AUTOSAR XML (schema 4-0-3)
standard types defined: Boolean, UInt16, UInt32, UInt8
package /AUTOSAR_Platform/DataConstrs
  range DC_Boolean: raw 0..1
  range DC_UInt16: raw 0..65535
  range DC_UInt8: raw 0..255
package /DataTypes/Units
  unit NoUnit1: display-name=NoUnit, factor-si-to-unit=1, offset-si-to-unit=0
package /PATAC/Facility/DataTypes/Implementation
  unit NoUnit: factor-si-to-unit=1, offset-si-to-unit=0
package /PATAC/MSM/ComponentTypes
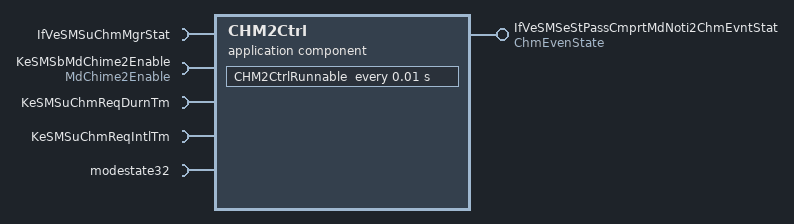
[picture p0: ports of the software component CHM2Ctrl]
  application sw component type CHM2Ctrl
    provide port IfVeSMSeStPassCmprtMdNoti2ChmEvntStat: nonqueued-sender-com-spec=data-element=ChmEvenState/Val, provided-interface=ChmEvenState
    5 x require port:
      IfVeSMSuChmMgrStat: nonqueued-receiver-com-spec{data-element=IfVeSMSuChmMgrStat/Val, filter=data-filter-type=ALWAYS}, required-interface=IfVeSMSuChmMgrStat
      KeSMSbMdChime2Enable: parameter-require-com-spec{init-value=0, parameter=MdChime2Enable/Val}, required-interface=MdChime2Enable
      KeSMSuChmReqDurnTm: parameter-require-com-spec{init-value=200, parameter=KeSMSuChmReqDurnTm/Val}, required-interface=KeSMSuChmReqDurnTm
      KeSMSuChmReqIntlTm: parameter-require-com-spec{init-value=50, parameter=KeSMSuChmReqIntlTm/Val}, required-interface=KeSMSuChmReqIntlTm
      modestate32: nonqueued-receiver-com-spec{data-element=modestate32/Val, filter=data-filter-type=ALWAYS, init-value=0}, required-interface=modestate32
    behavior CHM2Ctrl_InternalBehavior
      timing event TMT_CHM2CtrlRunnable: start-on-event=CHM2CtrlRunnable, period=0.01
      runnable CHM2CtrlRunnable
        data-receive-point-by-arguments:
          access REC_IfVeSMSuChmMgrStat_Val: accessed-variable=IfVeSMSuChmMgrStat.Val
          access REC_modestate32_Val: accessed-variable=modestate32.Val
        data-send-points:
          access SEND_IfVeSMSeStPassCmprtMdNoti2ChmEvntStat_Val: accessed-variable=IfVeSMSeStPassCmprtMdNoti2ChmEvntStat.Val
        parameter access PA_KeSMSbMdChime2Enable_Val: accessed-parameter=KeSMSbMdChime2Enable.Val
        parameter access PA_KeSMSuChmReqDurnTm_Val: accessed-parameter=KeSMSuChmReqDurnTm.Val
        parameter access PA_KeSMSuChmReqIntlTm_Val: accessed-parameter=KeSMSuChmReqIntlTm.Val
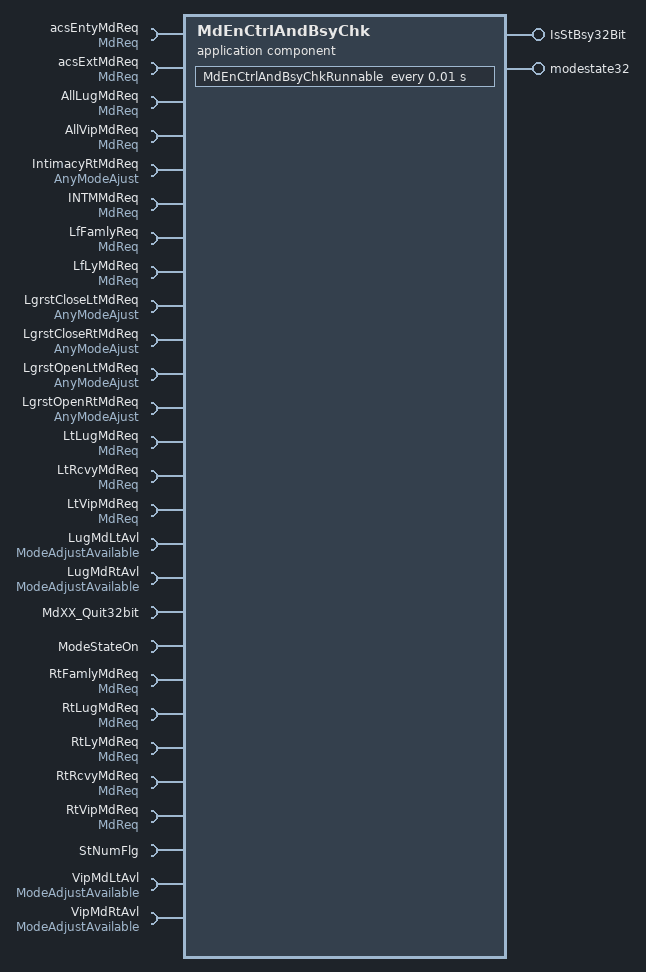
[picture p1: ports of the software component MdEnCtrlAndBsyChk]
  application sw component type MdEnCtrlAndBsyChk
    provide port IsStBsy32Bit: nonqueued-sender-com-spec{data-element=IsStBsy32Bit/Val, init-value=0}, provided-interface=IsStBsy32Bit
    provide port modestate32: nonqueued-sender-com-spec{data-element=modestate32/Val, init-value=0}, provided-interface=modestate32
    27 x require port:
      acsEntyMdReq: nonqueued-receiver-com-spec{data-element=MdReq/Val, filter=data-filter-type=ALWAYS, init-value=0}, required-interface=MdReq
      acsExtMdReq: nonqueued-receiver-com-spec{data-element=MdReq/Val, filter=data-filter-type=ALWAYS, init-value=0}, required-interface=MdReq
      AllLugMdReq: nonqueued-receiver-com-spec{data-element=MdReq/Val, filter=data-filter-type=ALWAYS, init-value=0}, required-interface=MdReq
      AllVipMdReq: nonqueued-receiver-com-spec{data-element=MdReq/Val, filter=data-filter-type=ALWAYS, init-value=0}, required-interface=MdReq
      IntimacyRtMdReq: nonqueued-receiver-com-spec{data-element=AnyModeAjust/Val, filter=data-filter-type=ALWAYS, init-value=0}, required-interface=AnyModeAjust
      INTMMdReq: nonqueued-receiver-com-spec{data-element=MdReq/Val, filter=data-filter-type=ALWAYS, init-value=0}, required-interface=MdReq
      LfFamlyReq: nonqueued-receiver-com-spec{data-element=MdReq/Val, filter=data-filter-type=ALWAYS, init-value=0}, required-interface=MdReq
      LfLyMdReq: nonqueued-receiver-com-spec{data-element=MdReq/Val, filter=data-filter-type=ALWAYS, init-value=0}, required-interface=MdReq
      LgrstCloseLtMdReq: nonqueued-receiver-com-spec{data-element=AnyModeAjust/Val, filter=data-filter-type=ALWAYS, init-value=0}, required-interface=AnyModeAjust
      LgrstCloseRtMdReq: nonqueued-receiver-com-spec{data-element=AnyModeAjust/Val, filter=data-filter-type=ALWAYS, init-value=0}, required-interface=AnyModeAjust
      LgrstOpenLtMdReq: nonqueued-receiver-com-spec{data-element=AnyModeAjust/Val, filter=data-filter-type=ALWAYS, init-value=0}, required-interface=AnyModeAjust
      LgrstOpenRtMdReq: nonqueued-receiver-com-spec{data-element=AnyModeAjust/Val, filter=data-filter-type=ALWAYS, init-value=0}, required-interface=AnyModeAjust
      LtLugMdReq: nonqueued-receiver-com-spec{data-element=MdReq/Val, filter=data-filter-type=ALWAYS, init-value=0}, required-interface=MdReq
      LtRcvyMdReq: nonqueued-receiver-com-spec{data-element=MdReq/Val, filter=data-filter-type=ALWAYS, init-value=0}, required-interface=MdReq
      LtVipMdReq: nonqueued-receiver-com-spec{data-element=MdReq/Val, filter=data-filter-type=ALWAYS, init-value=0}, required-interface=MdReq
      LugMdLtAvl: nonqueued-receiver-com-spec{data-element=ModeAdjustAvailable/Val, filter=data-filter-type=ALWAYS, init-value=0}, required-interface=ModeAdjustAvailable
      LugMdRtAvl: nonqueued-receiver-com-spec{data-element=ModeAdjustAvailable/Val, filter=data-filter-type=ALWAYS, init-value=0}, required-interface=ModeAdjustAvailable
      MdXX_Quit32bit: nonqueued-receiver-com-spec{data-element=MdXX_Quit32bit/Val, filter=data-filter-type=ALWAYS, init-value=0}, required-interface=MdXX_Quit32bit
      ModeStateOn: nonqueued-receiver-com-spec{data-element=ModeStateOn/Val, filter=data-filter-type=ALWAYS, init-value=0}, required-interface=ModeStateOn
      RtFamlyMdReq: nonqueued-receiver-com-spec{data-element=MdReq/Val, filter=data-filter-type=ALWAYS, init-value=0}, required-interface=MdReq
      RtLugMdReq: nonqueued-receiver-com-spec{data-element=MdReq/Val, filter=data-filter-type=ALWAYS, init-value=0}, required-interface=MdReq
      RtLyMdReq: nonqueued-receiver-com-spec{data-element=MdReq/Val, filter=data-filter-type=ALWAYS, init-value=0}, required-interface=MdReq
      RtRcvyMdReq: nonqueued-receiver-com-spec{data-element=MdReq/Val, filter=data-filter-type=ALWAYS, init-value=0}, required-interface=MdReq
      RtVipMdReq: nonqueued-receiver-com-spec{data-element=MdReq/Val, filter=data-filter-type=ALWAYS, init-value=0}, required-interface=MdReq
      StNumFlg: required-interface=StNumFlg
        required-com-specs:
          data-element=Is4s, filter=data-filter-type=ALWAYS, init-value=0
          data-element=Is6s, filter=data-filter-type=ALWAYS, init-value=0
          data-element=Is6s7s, filter=data-filter-type=ALWAYS, init-value=0
          data-element=Is7s, filter=data-filter-type=ALWAYS, init-value=0
      VipMdLtAvl: nonqueued-receiver-com-spec{data-element=ModeAdjustAvailable/Val, filter=data-filter-type=ALWAYS, init-value=0}, required-interface=ModeAdjustAvailable
      VipMdRtAvl: nonqueued-receiver-com-spec{data-element=ModeAdjustAvailable/Val, filter=data-filter-type=ALWAYS, init-value=0}, required-interface=ModeAdjustAvailable
    behavior MdEnCtrlAndBsyChk_InternalBehavior
      timing event TMT_EZEStateCtrlRunnable: start-on-event=MdEnCtrlAndBsyChkRunnable, period=0.01
      runnable MdEnCtrlAndBsyChkRunnable
        data-receive-point-by-arguments:
          30 x access:
            REC_acsEntyMdReq_Val: accessed-variable=acsEntyMdReq.Val
            REC_acsExtMdReq_Val: accessed-variable=acsExtMdReq.Val
            REC_AllLugMdReq_Val: accessed-variable=AllLugMdReq.Val
            REC_AllVipMdReq_Val: accessed-variable=AllVipMdReq.Val
            REC_IntimacyRtMdReq_Val: accessed-variable=IntimacyRtMdReq.Val
            REC_INTMMdReq_Val: accessed-variable=INTMMdReq.Val
            REC_LfFamlyReq_Val: accessed-variable=LfFamlyReq.Val
            REC_LfLyMdReq_Val: accessed-variable=LfLyMdReq.Val
            REC_LgrstCloseLtMdReq_Val: accessed-variable=LgrstCloseLtMdReq.Val
            REC_LgrstCloseRtMdReq_Val: accessed-variable=LgrstCloseRtMdReq.Val
            REC_LgrstOpenLtMdReq_Val: accessed-variable=LgrstOpenLtMdReq.Val
            REC_LgrstOpenRtMdReq_Val: accessed-variable=LgrstOpenRtMdReq.Val
            REC_LtLugMdReq_Val: accessed-variable=LtLugMdReq.Val
            REC_LtRcvyMdReq_Val: accessed-variable=LtRcvyMdReq.Val
            REC_LtVipMdReq_Val: accessed-variable=LtVipMdReq.Val
            REC_LugMdLtAvl_Val: accessed-variable=LugMdLtAvl.Val
            REC_LugMdRtAvl_Val: accessed-variable=LugMdRtAvl.Val
            REC_MdXX_Quit32bit_Val: accessed-variable=MdXX_Quit32bit.Val
            REC_ModeStateOn_Val: accessed-variable=ModeStateOn.Val
            REC_RtFamlyMdReq_Val: accessed-variable=RtFamlyMdReq.Val
            REC_RtLugMdReq_Val: accessed-variable=RtLugMdReq.Val
            REC_RtLyMdReq_Val: accessed-variable=RtLyMdReq.Val
            REC_RtRcvyMdReq_Val: accessed-variable=RtRcvyMdReq.Val
            REC_RtVipMdReq_Val: accessed-variable=RtVipMdReq.Val
            REC_StNumFlg_Is4s: accessed-variable=StNumFlg.Is4s
            REC_StNumFlg_Is6s: accessed-variable=StNumFlg.Is6s
            REC_StNumFlg_Is6s7s: accessed-variable=StNumFlg.Is6s7s
            REC_StNumFlg_Is7s: accessed-variable=StNumFlg.Is7s
            REC_VipMdLtAvl_Val: accessed-variable=VipMdLtAvl.Val
            REC_VipMdRtAvl_Val: accessed-variable=VipMdRtAvl.Val
        data-send-points:
          access SEND_IsStBsy32Bit_Val: accessed-variable=IsStBsy32Bit.Val
          access SEND_modestate32_Val: accessed-variable=modestate32.Val
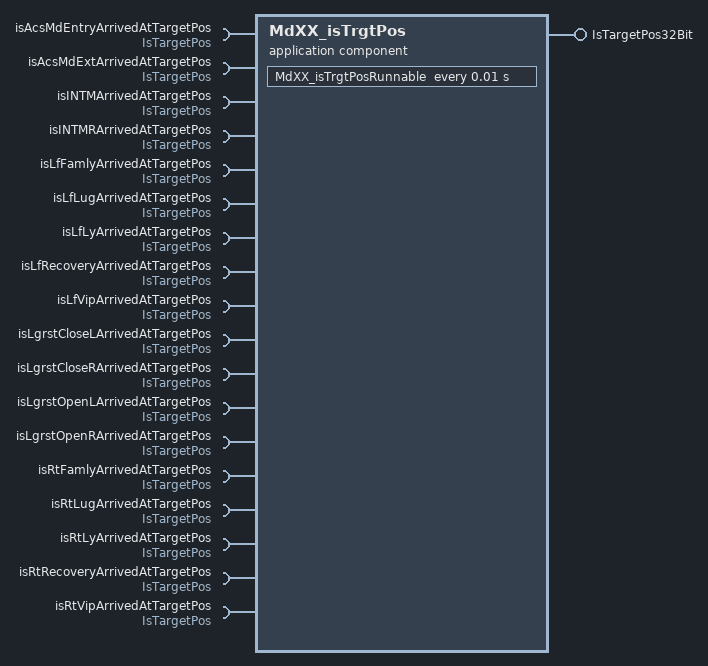
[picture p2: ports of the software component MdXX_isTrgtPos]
  application sw component type MdXX_isTrgtPos
    provide port IsTargetPos32Bit: nonqueued-sender-com-spec{data-element=IsTargetPos32Bit/Val, init-value=0}, provided-interface=IsTargetPos32Bit
    18 x require port, all with nonqueued-receiver-com-spec{data-element=IsTargetPos/Val, filter=data-filter-type=ALWAYS, init-value=0}, required-interface=IsTargetPos:
      isAcsMdEntryArrivedAtTargetPos
      isAcsMdExtArrivedAtTargetPos
      isINTMArrivedAtTargetPos
      isINTMRArrivedAtTargetPos
      isLfFamlyArrivedAtTargetPos
      isLfLugArrivedAtTargetPos
      isLfLyArrivedAtTargetPos
      isLfRecoveryArrivedAtTargetPos
      isLfVipArrivedAtTargetPos
      isLgrstCloseLArrivedAtTargetPos
      isLgrstCloseRArrivedAtTargetPos
      isLgrstOpenLArrivedAtTargetPos
      isLgrstOpenRArrivedAtTargetPos
      isRtFamlyArrivedAtTargetPos
      isRtLugArrivedAtTargetPos
      isRtLyArrivedAtTargetPos
      isRtRecoveryArrivedAtTargetPos
      isRtVipArrivedAtTargetPos
    behavior MdXX_isTrgtPos_InternalBehavior
      timing event TMT_MdXX_isTrgtPosRunnable: start-on-event=MdXX_isTrgtPosRunnable, period=0.01
      runnable MdXX_isTrgtPosRunnable
        data-receive-point-by-arguments:
          18 x access:
            REC_isAcsMdEntryArrivedAtTargetPos_Val: accessed-variable=isAcsMdEntryArrivedAtTargetPos.Val
            REC_isAcsMdExtArrivedAtTargetPos_Val: accessed-variable=isAcsMdExtArrivedAtTargetPos.Val
            REC_isINTMArrivedAtTargetPos_Val: accessed-variable=isINTMArrivedAtTargetPos.Val
            REC_isINTMRArrivedAtTargetPos_Val: accessed-variable=isINTMRArrivedAtTargetPos.Val
            REC_isLfFamlyArrivedAtTargetPos_Val: accessed-variable=isLfFamlyArrivedAtTargetPos.Val
            REC_isLfLugArrivedAtTargetPos_Val: accessed-variable=isLfLugArrivedAtTargetPos.Val
            REC_isLfLyArrivedAtTargetPos_Val: accessed-variable=isLfLyArrivedAtTargetPos.Val
            REC_isLfRecoveryArrivedAtTargetPos_Val: accessed-variable=isLfRecoveryArrivedAtTargetPos.Val
            REC_isLfVipArrivedAtTargetPos_Val: accessed-variable=isLfVipArrivedAtTargetPos.Val
            REC_isLgrstCloseLArrivedAtTargetPos_Val: accessed-variable=isLgrstCloseLArrivedAtTargetPos.Val
            REC_isLgrstCloseRArrivedAtTargetPos_Val: accessed-variable=isLgrstCloseRArrivedAtTargetPos.Val
            REC_isLgrstOpenLArrivedAtTargetPos_Val: accessed-variable=isLgrstOpenLArrivedAtTargetPos.Val
            REC_isLgrstOpenRArrivedAtTargetPos_Val: accessed-variable=isLgrstOpenRArrivedAtTargetPos.Val
            REC_isRtFamlyArrivedAtTargetPos_Val: accessed-variable=isRtFamlyArrivedAtTargetPos.Val
            REC_isRtLugArrivedAtTargetPos_Val: accessed-variable=isRtLugArrivedAtTargetPos.Val
            REC_isRtLyArrivedAtTargetPos_Val: accessed-variable=isRtLyArrivedAtTargetPos.Val
            REC_isRtRecoveryArrivedAtTargetPos_Val: accessed-variable=isRtRecoveryArrivedAtTargetPos.Val
            REC_isRtVipArrivedAtTargetPos_Val: accessed-variable=isRtVipArrivedAtTargetPos.Val
        data-send-points:
          access SEND_IsTargetPos32Bit_Val: accessed-variable=IsTargetPos32Bit.Val
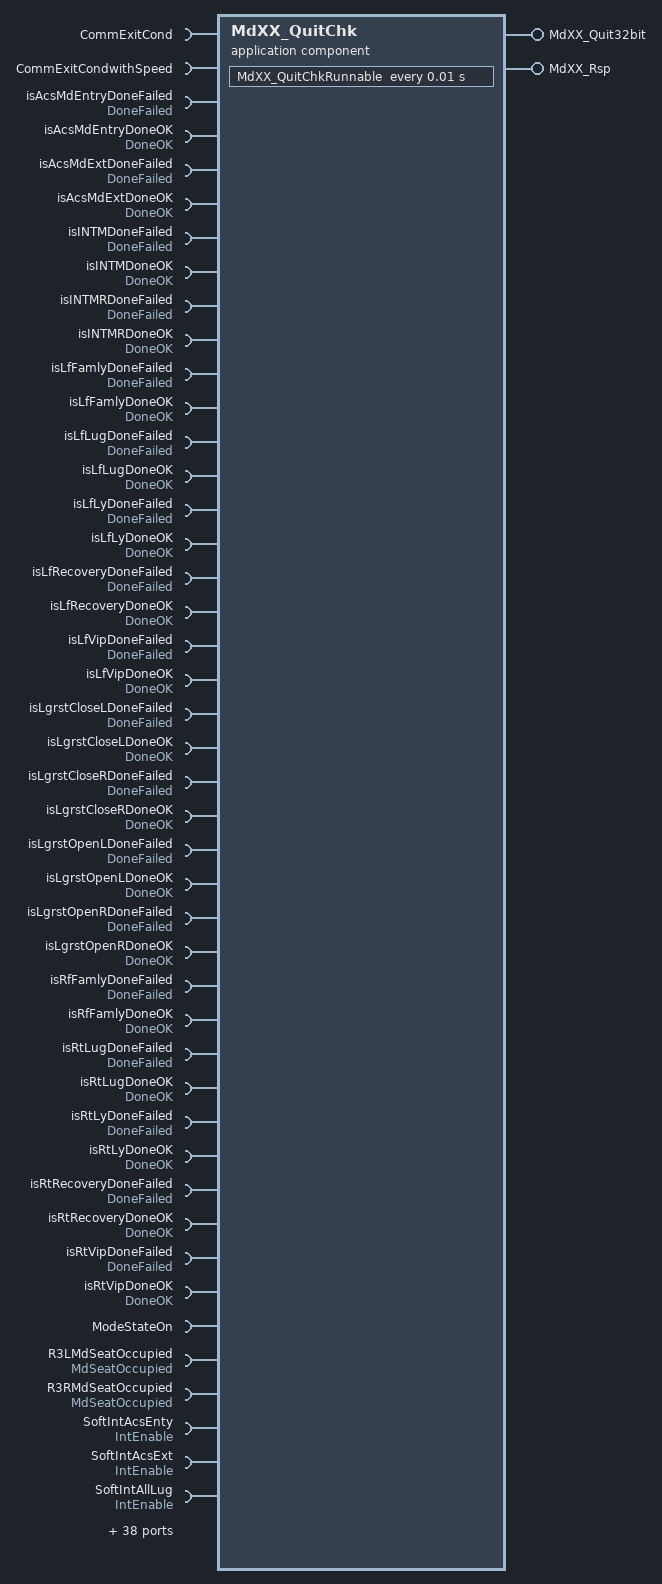
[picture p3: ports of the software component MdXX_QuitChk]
  application sw component type MdXX_QuitChk
    provide port MdXX_Quit32bit: nonqueued-sender-com-spec{data-element=MdXX_Quit32bit/Val, init-value=0}, provided-interface=MdXX_Quit32bit
    provide port MdXX_Rsp: provided-interface=MdXX_Rsp
      provided-com-specs:
        data-element=Md1_Rsp, init-value=0
        data-element=Md{10..19}_Rsp, init-value=0
        data-element=Md2_Rsp, init-value=0
        data-element=Md{20..29}_Rsp, init-value=0
        data-element=Md3_Rsp, init-value=0
        data-element=Md{30..32}_Rsp, init-value=0
        data-element=Md{4..9}_Rsp, init-value=0
    82 x require port:
      CommExitCond: nonqueued-receiver-com-spec{data-element=CommExitCond/Val, filter=data-filter-type=ALWAYS, init-value=0}, required-interface=CommExitCond
      CommExitCondwithSpeed: nonqueued-receiver-com-spec{data-element=CommExitCondwithSpeed/Val, filter=data-filter-type=ALWAYS, init-value=0}, required-interface=CommExitCondwithSpeed
      isAcsMdEntryDoneFailed: nonqueued-receiver-com-spec{data-element=DoneFailed/Val, filter=data-filter-type=ALWAYS, init-value=0}, required-interface=DoneFailed
      isAcsMdEntryDoneOK: nonqueued-receiver-com-spec{data-element=DoneOK/Val, filter=data-filter-type=ALWAYS, init-value=0}, required-interface=DoneOK
      isAcsMdExtDoneFailed: nonqueued-receiver-com-spec{data-element=DoneFailed/Val, filter=data-filter-type=ALWAYS, init-value=0}, required-interface=DoneFailed
      isAcsMdExtDoneOK: nonqueued-receiver-com-spec{data-element=DoneOK/Val, filter=data-filter-type=ALWAYS, init-value=0}, required-interface=DoneOK
      isINTMDoneFailed: nonqueued-receiver-com-spec{data-element=DoneFailed/Val, filter=data-filter-type=ALWAYS, init-value=0}, required-interface=DoneFailed
      isINTMDoneOK: nonqueued-receiver-com-spec{data-element=DoneOK/Val, filter=data-filter-type=ALWAYS, init-value=0}, required-interface=DoneOK
      isINTMRDoneFailed: nonqueued-receiver-com-spec{data-element=DoneFailed/Val, filter=data-filter-type=ALWAYS, init-value=0}, required-interface=DoneFailed
      isINTMRDoneOK: nonqueued-receiver-com-spec{data-element=DoneOK/Val, filter=data-filter-type=ALWAYS, init-value=0}, required-interface=DoneOK
      isLfFamlyDoneFailed: nonqueued-receiver-com-spec{data-element=DoneFailed/Val, filter=data-filter-type=ALWAYS, init-value=0}, required-interface=DoneFailed
      isLfFamlyDoneOK: nonqueued-receiver-com-spec{data-element=DoneOK/Val, filter=data-filter-type=ALWAYS, init-value=0}, required-interface=DoneOK
      isLfLugDoneFailed: nonqueued-receiver-com-spec{data-element=DoneFailed/Val, filter=data-filter-type=ALWAYS, init-value=0}, required-interface=DoneFailed
      isLfLugDoneOK: nonqueued-receiver-com-spec{data-element=DoneOK/Val, filter=data-filter-type=ALWAYS, init-value=0}, required-interface=DoneOK
      isLfLyDoneFailed: nonqueued-receiver-com-spec{data-element=DoneFailed/Val, filter=data-filter-type=ALWAYS, init-value=0}, required-interface=DoneFailed
      isLfLyDoneOK: nonqueued-receiver-com-spec{data-element=DoneOK/Val, filter=data-filter-type=ALWAYS, init-value=0}, required-interface=DoneOK
      isLfRecoveryDoneFailed: nonqueued-receiver-com-spec{data-element=DoneFailed/Val, filter=data-filter-type=ALWAYS, init-value=0}, required-interface=DoneFailed
      isLfRecoveryDoneOK: nonqueued-receiver-com-spec{data-element=DoneOK/Val, filter=data-filter-type=ALWAYS, init-value=0}, required-interface=DoneOK
      isLfVipDoneFailed: nonqueued-receiver-com-spec{data-element=DoneFailed/Val, filter=data-filter-type=ALWAYS, init-value=0}, required-interface=DoneFailed
      isLfVipDoneOK: nonqueued-receiver-com-spec{data-element=DoneOK/Val, filter=data-filter-type=ALWAYS, init-value=0}, required-interface=DoneOK
      isLgrstCloseLDoneFailed: nonqueued-receiver-com-spec{data-element=DoneFailed/Val, filter=data-filter-type=ALWAYS, init-value=0}, required-interface=DoneFailed
      isLgrstCloseLDoneOK: nonqueued-receiver-com-spec{data-element=DoneOK/Val, filter=data-filter-type=ALWAYS, init-value=0}, required-interface=DoneOK
      isLgrstCloseRDoneFailed: nonqueued-receiver-com-spec{data-element=DoneFailed/Val, filter=data-filter-type=ALWAYS, init-value=0}, required-interface=DoneFailed
      isLgrstCloseRDoneOK: nonqueued-receiver-com-spec{data-element=DoneOK/Val, filter=data-filter-type=ALWAYS, init-value=0}, required-interface=DoneOK
      isLgrstOpenLDoneFailed: nonqueued-receiver-com-spec{data-element=DoneFailed/Val, filter=data-filter-type=ALWAYS, init-value=0}, required-interface=DoneFailed
      isLgrstOpenLDoneOK: nonqueued-receiver-com-spec{data-element=DoneOK/Val, filter=data-filter-type=ALWAYS, init-value=0}, required-interface=DoneOK
      isLgrstOpenRDoneFailed: nonqueued-receiver-com-spec{data-element=DoneFailed/Val, filter=data-filter-type=ALWAYS, init-value=0}, required-interface=DoneFailed
      isLgrstOpenRDoneOK: nonqueued-receiver-com-spec{data-element=DoneOK/Val, filter=data-filter-type=ALWAYS, init-value=0}, required-interface=DoneOK
      isRfFamlyDoneFailed: nonqueued-receiver-com-spec{data-element=DoneFailed/Val, filter=data-filter-type=ALWAYS, init-value=0}, required-interface=DoneFailed
      isRfFamlyDoneOK: nonqueued-receiver-com-spec{data-element=DoneOK/Val, filter=data-filter-type=ALWAYS, init-value=0}, required-interface=DoneOK
      isRtLugDoneFailed: nonqueued-receiver-com-spec{data-element=DoneFailed/Val, filter=data-filter-type=ALWAYS, init-value=0}, required-interface=DoneFailed
      isRtLugDoneOK: nonqueued-receiver-com-spec{data-element=DoneOK/Val, filter=data-filter-type=ALWAYS, init-value=0}, required-interface=DoneOK
      isRtLyDoneFailed: nonqueued-receiver-com-spec{data-element=DoneFailed/Val, filter=data-filter-type=ALWAYS, init-value=0}, required-interface=DoneFailed
      isRtLyDoneOK: nonqueued-receiver-com-spec{data-element=DoneOK/Val, filter=data-filter-type=ALWAYS, init-value=0}, required-interface=DoneOK
      isRtRecoveryDoneFailed: nonqueued-receiver-com-spec{data-element=DoneFailed/Val, filter=data-filter-type=ALWAYS, init-value=0}, required-interface=DoneFailed
      isRtRecoveryDoneOK: nonqueued-receiver-com-spec{data-element=DoneOK/Val, filter=data-filter-type=ALWAYS, init-value=0}, required-interface=DoneOK
      isRtVipDoneFailed: nonqueued-receiver-com-spec{data-element=DoneFailed/Val, filter=data-filter-type=ALWAYS, init-value=0}, required-interface=DoneFailed
      isRtVipDoneOK: nonqueued-receiver-com-spec{data-element=DoneOK/Val, filter=data-filter-type=ALWAYS, init-value=0}, required-interface=DoneOK
      ModeStateOn: nonqueued-receiver-com-spec{data-element=ModeStateOn/Val, filter=data-filter-type=ALWAYS, init-value=0}, required-interface=ModeStateOn
      R3LMdSeatOccupied: nonqueued-receiver-com-spec{data-element=MdSeatOccupied/Val, filter=data-filter-type=ALWAYS, init-value=0}, required-interface=MdSeatOccupied
      R3RMdSeatOccupied: nonqueued-receiver-com-spec{data-element=MdSeatOccupied/Val, filter=data-filter-type=ALWAYS, init-value=0}, required-interface=MdSeatOccupied
      SoftIntAcsEnty: nonqueued-receiver-com-spec{data-element=IntEnable/Val, filter=data-filter-type=ALWAYS, init-value=0}, required-interface=IntEnable
      SoftIntAcsExt: nonqueued-receiver-com-spec{data-element=IntEnable/Val, filter=data-filter-type=ALWAYS, init-value=0}, required-interface=IntEnable
      SoftIntAllLug: nonqueued-receiver-com-spec{data-element=IntEnable/Val, filter=data-filter-type=ALWAYS, init-value=0}, required-interface=IntEnable
      SoftIntAllVip: nonqueued-receiver-com-spec{data-element=IntEnable/Val, filter=data-filter-type=ALWAYS, init-value=0}, required-interface=IntEnable
      SoftIntIntimacyRt: nonqueued-receiver-com-spec{data-element=IntEnable/Val, filter=data-filter-type=ALWAYS, init-value=0}, required-interface=IntEnable
      SoftIntINTM: nonqueued-receiver-com-spec{data-element=IntEnable/Val, filter=data-filter-type=ALWAYS, init-value=0}, required-interface=IntEnable
      SoftIntLfFamly: nonqueued-receiver-com-spec{data-element=IntEnable/Val, filter=data-filter-type=ALWAYS, init-value=0}, required-interface=IntEnable
      SoftIntLfLug: nonqueued-receiver-com-spec{data-element=IntEnable/Val, filter=data-filter-type=ALWAYS, init-value=0}, required-interface=IntEnable
      SoftIntLfLy: nonqueued-receiver-com-spec{data-element=IntEnable/Val, filter=data-filter-type=ALWAYS, init-value=0}, required-interface=IntEnable
      SoftIntLfRcvy: nonqueued-receiver-com-spec{data-element=IntEnable/Val, filter=data-filter-type=ALWAYS, init-value=0}, required-interface=IntEnable
      SoftIntLfVip: nonqueued-receiver-com-spec{data-element=IntEnable/Val, filter=data-filter-type=ALWAYS, init-value=0}, required-interface=IntEnable
      SoftIntLgrstCloseLt: nonqueued-receiver-com-spec{data-element=IntEnable/Val, filter=data-filter-type=ALWAYS, init-value=0}, required-interface=IntEnable
      SoftIntLgrstCloseRt: nonqueued-receiver-com-spec{data-element=IntEnable/Val, filter=data-filter-type=ALWAYS, init-value=0}, required-interface=IntEnable
      SoftIntLgrstOpenLt: nonqueued-receiver-com-spec{data-element=IntEnable/Val, filter=data-filter-type=ALWAYS, init-value=0}, required-interface=IntEnable
      SoftIntLgrstOpenRt: nonqueued-receiver-com-spec{data-element=IntEnable/Val, filter=data-filter-type=ALWAYS, init-value=0}, required-interface=IntEnable
      SoftIntRtFamly: nonqueued-receiver-com-spec{data-element=IntEnable/Val, filter=data-filter-type=ALWAYS, init-value=0}, required-interface=IntEnable
      SoftIntRtLug: nonqueued-receiver-com-spec{data-element=IntEnable/Val, filter=data-filter-type=ALWAYS, init-value=0}, required-interface=IntEnable
      SoftIntRtLy: nonqueued-receiver-com-spec{data-element=IntEnable/Val, filter=data-filter-type=ALWAYS, init-value=0}, required-interface=IntEnable
      SoftIntRtRcvy: nonqueued-receiver-com-spec{data-element=IntEnable/Val, filter=data-filter-type=ALWAYS, init-value=0}, required-interface=IntEnable
      SoftIntRtVip: nonqueued-receiver-com-spec{data-element=IntEnable/Val, filter=data-filter-type=ALWAYS, init-value=0}, required-interface=IntEnable
      StNumFlg: required-interface=StNumFlg
        required-com-specs:
          data-element=Is4s, filter=data-filter-type=ALWAYS, init-value=0
          data-element=Is6s, filter=data-filter-type=ALWAYS, init-value=0
          data-element=Is6s7s, filter=data-filter-type=ALWAYS, init-value=0
          data-element=Is7s, filter=data-filter-type=ALWAYS, init-value=0
      SwIntAcsEnty: nonqueued-receiver-com-spec{data-element=IntEnable/Val, filter=data-filter-type=ALWAYS, init-value=0}, required-interface=IntEnable
      SwIntAcsExt: nonqueued-receiver-com-spec{data-element=IntEnable/Val, filter=data-filter-type=ALWAYS, init-value=0}, required-interface=IntEnable
      SwIntAllLug: nonqueued-receiver-com-spec{data-element=IntEnable/Val, filter=data-filter-type=ALWAYS, init-value=0}, required-interface=IntEnable
      SwIntAllVip: nonqueued-receiver-com-spec{data-element=IntEnable/Val, filter=data-filter-type=ALWAYS, init-value=0}, required-interface=IntEnable
      SwIntIntimacyRt: nonqueued-receiver-com-spec{data-element=IntEnable/Val, filter=data-filter-type=ALWAYS, init-value=0}, required-interface=IntEnable
      SwIntINTM: nonqueued-receiver-com-spec{data-element=IntEnable/Val, filter=data-filter-type=ALWAYS, init-value=0}, required-interface=IntEnable
      SwIntLfFamly: nonqueued-receiver-com-spec{data-element=IntEnable/Val, filter=data-filter-type=ALWAYS, init-value=0}, required-interface=IntEnable
      SwIntLfLug: nonqueued-receiver-com-spec{data-element=IntEnable/Val, filter=data-filter-type=ALWAYS, init-value=0}, required-interface=IntEnable
      SwIntLfLy: nonqueued-receiver-com-spec{data-element=IntEnable/Val, filter=data-filter-type=ALWAYS, init-value=0}, required-interface=IntEnable
      SwIntLfRcvy: nonqueued-receiver-com-spec{data-element=IntEnable/Val, filter=data-filter-type=ALWAYS, init-value=0}, required-interface=IntEnable
      SwIntLfVip: nonqueued-receiver-com-spec{data-element=IntEnable/Val, filter=data-filter-type=ALWAYS, init-value=0}, required-interface=IntEnable
      SwIntLgrstCloseLt: nonqueued-receiver-com-spec{data-element=IntEnable/Val, filter=data-filter-type=ALWAYS, init-value=0}, required-interface=IntEnable
      SwIntLgrstCloseRt: nonqueued-receiver-com-spec{data-element=IntEnable/Val, filter=data-filter-type=ALWAYS, init-value=0}, required-interface=IntEnable
      SwIntLgrstOpenLt: nonqueued-receiver-com-spec{data-element=IntEnable/Val, filter=data-filter-type=ALWAYS, init-value=0}, required-interface=IntEnable
      SwIntLgrstOpenRt: nonqueued-receiver-com-spec{data-element=IntEnable/Val, filter=data-filter-type=ALWAYS, init-value=0}, required-interface=IntEnable
      SwIntRtFamly: nonqueued-receiver-com-spec{data-element=IntEnable/Val, filter=data-filter-type=ALWAYS, init-value=0}, required-interface=IntEnable
      SwIntRtLug: nonqueued-receiver-com-spec{data-element=IntEnable/Val, filter=data-filter-type=ALWAYS, init-value=0}, required-interface=IntEnable
      SwIntRtLy: nonqueued-receiver-com-spec{data-element=IntEnable/Val, filter=data-filter-type=ALWAYS, init-value=0}, required-interface=IntEnable
      SwIntRtRcvy: nonqueued-receiver-com-spec{data-element=IntEnable/Val, filter=data-filter-type=ALWAYS, init-value=0}, required-interface=IntEnable
      SwIntRtVip: nonqueued-receiver-com-spec{data-element=IntEnable/Val, filter=data-filter-type=ALWAYS, init-value=0}, required-interface=IntEnable
    behavior MdXX_QuitChk_InternalBehavior
      timing event TMT_EZEBsyChkRunnable: start-on-event=MdXX_QuitChkRunnable, period=0.01
      runnable MdXX_QuitChkRunnable
        data-receive-point-by-arguments:
          85 x access:
            REC_CommExitCond_Val: accessed-variable=CommExitCond.Val
            REC_CommExitCondwithSpeed_Val: accessed-variable=CommExitCondwithSpeed.Val
            REC_isAcsMdEntryDoneFailed_Val: accessed-variable=isAcsMdEntryDoneFailed.Val
            REC_isAcsMdEntryDoneOK_Val: accessed-variable=isAcsMdEntryDoneOK.Val
            REC_isAcsMdExtDoneFailed_Val: accessed-variable=isAcsMdExtDoneFailed.Val
            REC_isAcsMdExtDoneOK_Val: accessed-variable=isAcsMdExtDoneOK.Val
            REC_isINTMDoneFailed_Val: accessed-variable=isINTMDoneFailed.Val
            REC_isINTMDoneOK_Val: accessed-variable=isINTMDoneOK.Val
            REC_isINTMRDoneFailed_Val: accessed-variable=isINTMRDoneFailed.Val
            REC_isINTMRDoneOK_Val: accessed-variable=isINTMRDoneOK.Val
            REC_isLfFamlyDoneFailed_Val: accessed-variable=isLfFamlyDoneFailed.Val
            REC_isLfFamlyDoneOK_Val: accessed-variable=isLfFamlyDoneOK.Val
            REC_isLfLugDoneFailed_Val: accessed-variable=isLfLugDoneFailed.Val
            REC_isLfLugDoneOK_Val: accessed-variable=isLfLugDoneOK.Val
            REC_isLfLyDoneFailed_Val: accessed-variable=isLfLyDoneFailed.Val
            REC_isLfLyDoneOK_Val: accessed-variable=isLfLyDoneOK.Val
            REC_isLfRecoveryDoneFailed_Val: accessed-variable=isLfRecoveryDoneFailed.Val
            REC_isLfRecoveryDoneOK_Val: accessed-variable=isLfRecoveryDoneOK.Val
            REC_isLfVipDoneFailed_Val: accessed-variable=isLfVipDoneFailed.Val
            REC_isLfVipDoneOK_Val: accessed-variable=isLfVipDoneOK.Val
            REC_isLgrstCloseLDoneFailed_Val: accessed-variable=isLgrstCloseLDoneFailed.Val
            REC_isLgrstCloseLDoneOK_Val: accessed-variable=isLgrstCloseLDoneOK.Val
            REC_isLgrstCloseRDoneFailed_Val: accessed-variable=isLgrstCloseRDoneFailed.Val
            REC_isLgrstCloseRDoneOK_Val: accessed-variable=isLgrstCloseRDoneOK.Val
            REC_isLgrstOpenLDoneFailed_Val: accessed-variable=isLgrstOpenLDoneFailed.Val
            REC_isLgrstOpenLDoneOK_Val: accessed-variable=isLgrstOpenLDoneOK.Val
            REC_isLgrstOpenRDoneFailed_Val: accessed-variable=isLgrstOpenRDoneFailed.Val
            REC_isLgrstOpenRDoneOK_Val: accessed-variable=isLgrstOpenRDoneOK.Val
            REC_isRfFamlyDoneFailed_Val: accessed-variable=isRfFamlyDoneFailed.Val
            REC_isRfFamlyDoneOK_Val: accessed-variable=isRfFamlyDoneOK.Val
            REC_isRtLugDoneFailed_Val: accessed-variable=isRtLugDoneFailed.Val
            REC_isRtLugDoneOK_Val: accessed-variable=isRtLugDoneOK.Val
            REC_isRtLyDoneFailed_Val: accessed-variable=isRtLyDoneFailed.Val
            REC_isRtLyDoneOK_Val: accessed-variable=isRtLyDoneOK.Val
            REC_isRtRecoveryDoneFailed_Val: accessed-variable=isRtRecoveryDoneFailed.Val
            REC_isRtRecoveryDoneOK_Val: accessed-variable=isRtRecoveryDoneOK.Val
            REC_isRtVipDoneFailed_Val: accessed-variable=isRtVipDoneFailed.Val
            REC_isRtVipDoneOK_Val: accessed-variable=isRtVipDoneOK.Val
            REC_ModeStateOn_Val: accessed-variable=ModeStateOn.Val
            REC_R3LMdSeatOccupied_Val: accessed-variable=R3LMdSeatOccupied.Val
            REC_R3RMdSeatOccupied_Val: accessed-variable=R3RMdSeatOccupied.Val
            REC_SoftIntAcsEnty_Val: accessed-variable=SoftIntAcsEnty.Val
            REC_SoftIntAcsExt_Val: accessed-variable=SoftIntAcsExt.Val
            REC_SoftIntAllLug_Val: accessed-variable=SoftIntAllLug.Val
            REC_SoftIntAllVip_Val: accessed-variable=SoftIntAllVip.Val
            REC_SoftIntIntimacyRt_Val: accessed-variable=SoftIntIntimacyRt.Val
            REC_SoftIntINTM_Val: accessed-variable=SoftIntINTM.Val
            REC_SoftIntLfFamly_Val: accessed-variable=SoftIntLfFamly.Val
            REC_SoftIntLfLug_Val: accessed-variable=SoftIntLfLug.Val
            REC_SoftIntLfLy_Val: accessed-variable=SoftIntLfLy.Val
            REC_SoftIntLfRcvy_Val: accessed-variable=SoftIntLfRcvy.Val
            REC_SoftIntLfVip_Val: accessed-variable=SoftIntLfVip.Val
            REC_SoftIntLgrstCloseLt_Val: accessed-variable=SoftIntLgrstCloseLt.Val
            REC_SoftIntLgrstCloseRt_Val: accessed-variable=SoftIntLgrstCloseRt.Val
            REC_SoftIntLgrstOpenLt_Val: accessed-variable=SoftIntLgrstOpenLt.Val
            REC_SoftIntLgrstOpenRt_Val: accessed-variable=SoftIntLgrstOpenRt.Val
            REC_SoftIntRtFamly_Val: accessed-variable=SoftIntRtFamly.Val
            REC_SoftIntRtLug_Val: accessed-variable=SoftIntRtLug.Val
            REC_SoftIntRtLy_Val: accessed-variable=SoftIntRtLy.Val
            REC_SoftIntRtRcvy_Val: accessed-variable=SoftIntRtRcvy.Val
            REC_SoftIntRtVip_Val: accessed-variable=SoftIntRtVip.Val
            REC_StNumFlg_Is4s: accessed-variable=StNumFlg.Is4s
            REC_StNumFlg_Is6s: accessed-variable=StNumFlg.Is6s
            REC_StNumFlg_Is6s7s: accessed-variable=StNumFlg.Is6s7s
            REC_StNumFlg_Is7s: accessed-variable=StNumFlg.Is7s
            REC_SwIntAcsEnty_Val: accessed-variable=SwIntAcsEnty.Val
            REC_SwIntAcsExt_Val: accessed-variable=SwIntAcsExt.Val
            REC_SwIntAllLug_Val: accessed-variable=SwIntAllLug.Val
            REC_SwIntAllVip_Val: accessed-variable=SwIntAllVip.Val
            REC_SwIntIntimacyRt_Val: accessed-variable=SwIntIntimacyRt.Val
            REC_SwIntINTM_Val: accessed-variable=SwIntINTM.Val
            REC_SwIntLfFamly_Val: accessed-variable=SwIntLfFamly.Val
            REC_SwIntLfLug_Val: accessed-variable=SwIntLfLug.Val
            REC_SwIntLfLy_Val: accessed-variable=SwIntLfLy.Val
            REC_SwIntLfRcvy_Val: accessed-variable=SwIntLfRcvy.Val
            REC_SwIntLfVip_Val: accessed-variable=SwIntLfVip.Val
            REC_SwIntLgrstCloseLt_Val: accessed-variable=SwIntLgrstCloseLt.Val
            REC_SwIntLgrstCloseRt_Val: accessed-variable=SwIntLgrstCloseRt.Val
            REC_SwIntLgrstOpenLt_Val: accessed-variable=SwIntLgrstOpenLt.Val
            REC_SwIntLgrstOpenRt_Val: accessed-variable=SwIntLgrstOpenRt.Val
            REC_SwIntRtFamly_Val: accessed-variable=SwIntRtFamly.Val
            REC_SwIntRtLug_Val: accessed-variable=SwIntRtLug.Val
            REC_SwIntRtLy_Val: accessed-variable=SwIntRtLy.Val
            REC_SwIntRtRcvy_Val: accessed-variable=SwIntRtRcvy.Val
            REC_SwIntRtVip_Val: accessed-variable=SwIntRtVip.Val
        data-send-points:
          33 x access:
            SEND_MdXX_Rsp_Md1_Rsp: accessed-variable=MdXX_Rsp.Md1_Rsp
            SEND_MdXX_Rsp_Md{10..19}_Rsp: accessed-variable=MdXX_Rsp.Md{10..19}_Rsp
            SEND_MdXX_Rsp_Md2_Rsp: accessed-variable=MdXX_Rsp.Md2_Rsp
            SEND_MdXX_Rsp_Md{20..29}_Rsp: accessed-variable=MdXX_Rsp.Md{20..29}_Rsp
            SEND_MdXX_Rsp_Md3_Rsp: accessed-variable=MdXX_Rsp.Md3_Rsp
            SEND_MdXX_Rsp_Md{30..32}_Rsp: accessed-variable=MdXX_Rsp.Md{30..32}_Rsp
            SEND_MdXX_Rsp_Md{4..9}_Rsp: accessed-variable=MdXX_Rsp.Md{4..9}_Rsp
            SEND_MdXXQuit32bit_Val: accessed-variable=MdXX_Quit32bit.Val
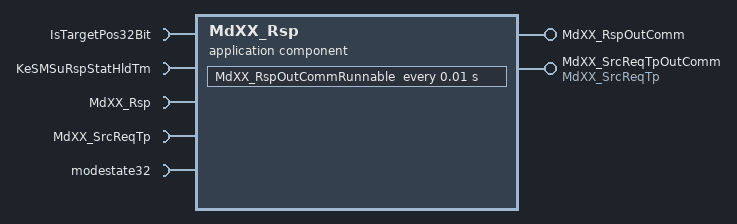
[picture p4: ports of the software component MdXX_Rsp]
  application sw component type MdXX_Rsp
    provide port MdXX_RspOutComm: provided-interface=MdXX_RspOutComm
      provided-com-specs:
        data-element=Md1_RspOutComm, init-value=0
        data-element=Md{10..19}_RspOutComm, init-value=0
        data-element=Md2_RspOutComm, init-value=0
        data-element=Md{20..29}_RspOutComm, init-value=0
        data-element=Md3_RspOutComm, init-value=0
        data-element=Md{30..32}_RspOutComm, init-value=0
        data-element=Md{4..9}_RspOutComm, init-value=0
    provide port MdXX_SrcReqTpOutComm: provided-interface=MdXX_SrcReqTp
      provided-com-specs:
        data-element=Md1_SrcTp, init-value=0
        data-element=Md{10..19}_SrcTp, init-value=0
        data-element=Md2_SrcTp, init-value=0
        data-element=Md{20..29}_SrcTp, init-value=0
        data-element=Md3_SrcTp, init-value=0
        data-element=Md{30..32}_SrcTp, init-value=0
        data-element=Md{4..9}_SrcTp, init-value=0
    5 x require port:
      IsTargetPos32Bit: nonqueued-receiver-com-spec{data-element=IsTargetPos32Bit/Val, filter=data-filter-type=ALWAYS, init-value=0}, required-interface=IsTargetPos32Bit
      KeSMSuRspStatHldTm: parameter-require-com-spec{init-value=100, parameter=KeSMSuRspStatHldTm/Val}, required-interface=KeSMSuRspStatHldTm
      MdXX_Rsp: required-interface=MdXX_Rsp
        required-com-specs:
          data-element=Md1_Rsp, filter=data-filter-type=ALWAYS, init-value=0
          data-element=Md{10..19}_Rsp, filter=data-filter-type=ALWAYS, init-value=0
          data-element=Md2_Rsp, filter=data-filter-type=ALWAYS, init-value=0
          data-element=Md{20..29}_Rsp, filter=data-filter-type=ALWAYS, init-value=0
          data-element=Md3_Rsp, filter=data-filter-type=ALWAYS, init-value=0
          data-element=Md{30..32}_Rsp, filter=data-filter-type=ALWAYS, init-value=0
          data-element=Md{4..9}_Rsp, filter=data-filter-type=ALWAYS, init-value=0
      MdXX_SrcReqTp: required-interface=MdXX_SrcReqTp
        required-com-specs:
          data-element=Md1_SrcTp, filter=data-filter-type=ALWAYS, init-value=0
          data-element=Md{10..19}_SrcTp, filter=data-filter-type=ALWAYS, init-value=0
          data-element=Md2_SrcTp, filter=data-filter-type=ALWAYS, init-value=0
          data-element=Md{20..29}_SrcTp, filter=data-filter-type=ALWAYS, init-value=0
          data-element=Md3_SrcTp, filter=data-filter-type=ALWAYS, init-value=0
          data-element=Md{30..32}_SrcTp, filter=data-filter-type=ALWAYS, init-value=0
          data-element=Md{4..9}_SrcTp, filter=data-filter-type=ALWAYS, init-value=0
      modestate32: nonqueued-receiver-com-spec{data-element=modestate32/Val, filter=data-filter-type=ALWAYS}, required-interface=modestate32
    behavior MdXX_Rsp_InternalBehavior
      timing event TMT_Runnable: start-on-event=MdXX_RspOutCommRunnable, period=0.01
      runnable MdXX_RspOutCommRunnable
        data-receive-point-by-arguments:
          66 x access:
            REC_IsTargetPos32Bit_Val: accessed-variable=IsTargetPos32Bit.Val
            REC_MdXX_Rsp_Md1_Rsp: accessed-variable=MdXX_Rsp.Md1_Rsp
            REC_MdXX_Rsp_Md{10..19}_Rsp: accessed-variable=MdXX_Rsp.Md{10..19}_Rsp
            REC_MdXX_Rsp_Md2_Rsp: accessed-variable=MdXX_Rsp.Md2_Rsp
            REC_MdXX_Rsp_Md{20..29}_Rsp: accessed-variable=MdXX_Rsp.Md{20..29}_Rsp
            REC_MdXX_Rsp_Md3_Rsp: accessed-variable=MdXX_Rsp.Md3_Rsp
            REC_MdXX_Rsp_Md{30..32}_Rsp: accessed-variable=MdXX_Rsp.Md{30..32}_Rsp
            REC_MdXX_Rsp_Md{4..9}_Rsp: accessed-variable=MdXX_Rsp.Md{4..9}_Rsp
            REC_MdXX_SrcReqTp_Md1_SrcTp: accessed-variable=MdXX_SrcReqTp.Md1_SrcTp
            REC_MdXX_SrcReqTp_Md{10..19}_SrcTp: accessed-variable=MdXX_SrcReqTp.Md{10..19}_SrcTp
            REC_MdXX_SrcReqTp_Md2_SrcTp: accessed-variable=MdXX_SrcReqTp.Md2_SrcTp
            REC_MdXX_SrcReqTp_Md{20..29}_SrcTp: accessed-variable=MdXX_SrcReqTp.Md{20..29}_SrcTp
            REC_MdXX_SrcReqTp_Md3_SrcTp: accessed-variable=MdXX_SrcReqTp.Md3_SrcTp
            REC_MdXX_SrcReqTp_Md{30..32}_SrcTp: accessed-variable=MdXX_SrcReqTp.Md{30..32}_SrcTp
            REC_MdXX_SrcReqTp_Md{4..9}_SrcTp: accessed-variable=MdXX_SrcReqTp.Md{4..9}_SrcTp
            REC_modestate32_Val: accessed-variable=modestate32.Val
        data-send-points:
          64 x access:
            SEND_MdXX_RspOutComm_Md1_RspOutComm: accessed-variable=MdXX_RspOutComm.Md1_RspOutComm
            SEND_MdXX_RspOutComm_Md{10..19}_RspOutComm: accessed-variable=MdXX_RspOutComm.Md{10..19}_RspOutComm
            SEND_MdXX_RspOutComm_Md2_RspOutComm: accessed-variable=MdXX_RspOutComm.Md2_RspOutComm
            SEND_MdXX_RspOutComm_Md{20..29}_RspOutComm: accessed-variable=MdXX_RspOutComm.Md{20..29}_RspOutComm
            SEND_MdXX_RspOutComm_Md3_RspOutComm: accessed-variable=MdXX_RspOutComm.Md3_RspOutComm
            SEND_MdXX_RspOutComm_Md{30..32}_RspOutComm: accessed-variable=MdXX_RspOutComm.Md{30..32}_RspOutComm
            SEND_MdXX_RspOutComm_Md{4..9}_RspOutComm: accessed-variable=MdXX_RspOutComm.Md{4..9}_RspOutComm
            SEND_MdXX_SrcReqTpOutComm_Md1_SrcTp: accessed-variable=MdXX_SrcReqTpOutComm.Md1_SrcTp
            SEND_MdXX_SrcReqTpOutComm_Md{10..19}_SrcTp: accessed-variable=MdXX_SrcReqTpOutComm.Md{10..19}_SrcTp
            SEND_MdXX_SrcReqTpOutComm_Md2_SrcTp: accessed-variable=MdXX_SrcReqTpOutComm.Md2_SrcTp
            SEND_MdXX_SrcReqTpOutComm_Md{20..29}_SrcTp: accessed-variable=MdXX_SrcReqTpOutComm.Md{20..29}_SrcTp
            SEND_MdXX_SrcReqTpOutComm_Md3_SrcTp: accessed-variable=MdXX_SrcReqTpOutComm.Md3_SrcTp
            SEND_MdXX_SrcReqTpOutComm_Md{30..32}_SrcTp: accessed-variable=MdXX_SrcReqTpOutComm.Md{30..32}_SrcTp
            SEND_MdXX_SrcReqTpOutComm_Md{4..9}_SrcTp: accessed-variable=MdXX_SrcReqTpOutComm.Md{4..9}_SrcTp
        parameter access PA_KeSMSuRspStatHldTm_Val: accessed-parameter=KeSMSuRspStatHldTm.Val
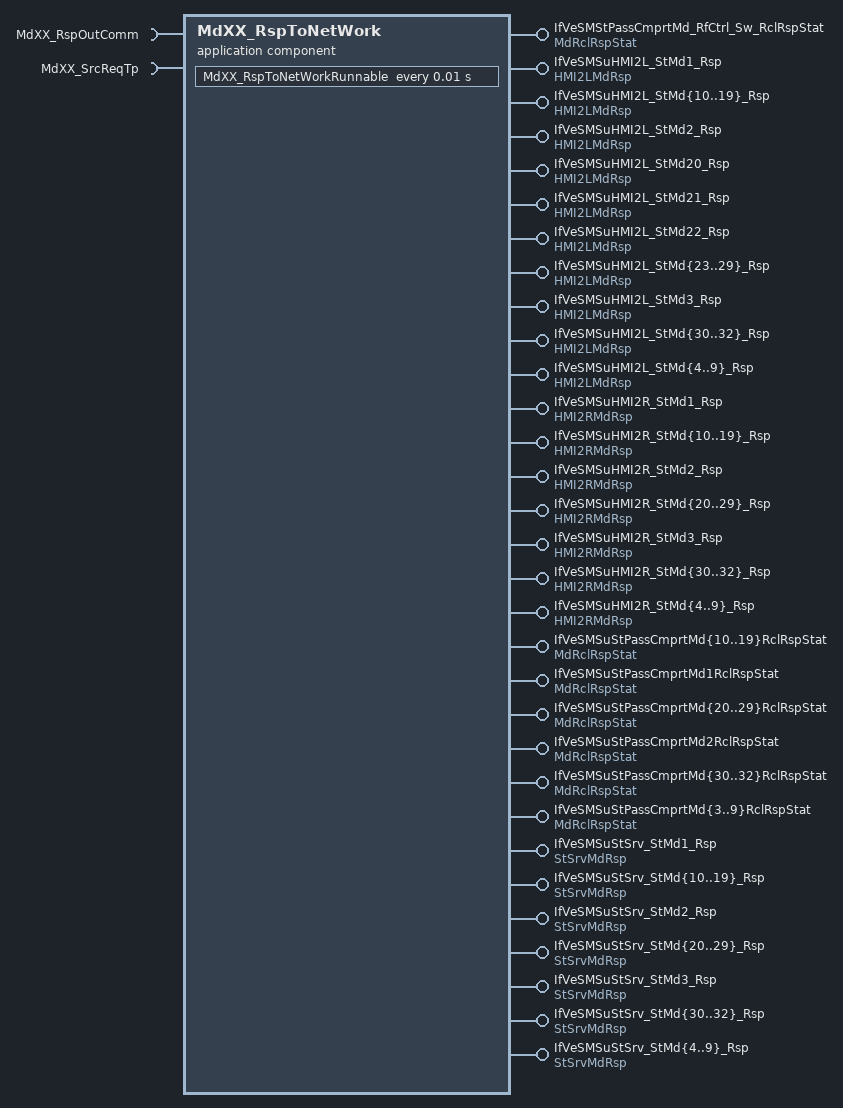
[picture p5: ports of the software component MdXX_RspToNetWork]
  application sw component type MdXX_RspToNetWork
    129 x provide port:
      IfVeSMStPassCmprtMd_RfCtrl_Sw_RclRspStat: nonqueued-sender-com-spec=data-element=MdRclRspStat/Val, provided-interface=MdRclRspStat
      IfVeSMSuHMI2L_StMd1_Rsp: nonqueued-sender-com-spec=data-element=HMI2LMdRsp/Val, provided-interface=HMI2LMdRsp
      IfVeSMSuHMI2L_StMd{10..19}_Rsp: nonqueued-sender-com-spec=data-element=HMI2LMdRsp/Val, provided-interface=HMI2LMdRsp
      IfVeSMSuHMI2L_StMd2_Rsp: nonqueued-sender-com-spec=data-element=HMI2LMdRsp/Val, provided-interface=HMI2LMdRsp
      IfVeSMSuHMI2L_StMd20_Rsp: nonqueued-sender-com-spec=data-element=HMI2LMdRsp/Val, provided-interface=HMI2LMdRsp
      IfVeSMSuHMI2L_StMd21_Rsp: nonqueued-sender-com-spec=data-element=HMI2LMdRsp/Val, provided-interface=HMI2LMdRsp
      IfVeSMSuHMI2L_StMd22_Rsp: nonqueued-sender-com-spec{data-element=HMI2LMdRsp/Val, init-value=0}, provided-interface=HMI2LMdRsp
      IfVeSMSuHMI2L_StMd{23..29}_Rsp: nonqueued-sender-com-spec=data-element=HMI2LMdRsp/Val, provided-interface=HMI2LMdRsp
      IfVeSMSuHMI2L_StMd3_Rsp: nonqueued-sender-com-spec=data-element=HMI2LMdRsp/Val, provided-interface=HMI2LMdRsp
      IfVeSMSuHMI2L_StMd{30..32}_Rsp: nonqueued-sender-com-spec=data-element=HMI2LMdRsp/Val, provided-interface=HMI2LMdRsp
      IfVeSMSuHMI2L_StMd{4..9}_Rsp: nonqueued-sender-com-spec=data-element=HMI2LMdRsp/Val, provided-interface=HMI2LMdRsp
      IfVeSMSuHMI2R_StMd1_Rsp: nonqueued-sender-com-spec=data-element=HMI2RMdRsp/Val, provided-interface=HMI2RMdRsp
      IfVeSMSuHMI2R_StMd{10..19}_Rsp: nonqueued-sender-com-spec=data-element=HMI2RMdRsp/Val, provided-interface=HMI2RMdRsp
      IfVeSMSuHMI2R_StMd2_Rsp: nonqueued-sender-com-spec=data-element=HMI2RMdRsp/Val, provided-interface=HMI2RMdRsp
      IfVeSMSuHMI2R_StMd{20..29}_Rsp: nonqueued-sender-com-spec=data-element=HMI2RMdRsp/Val, provided-interface=HMI2RMdRsp
      IfVeSMSuHMI2R_StMd3_Rsp: nonqueued-sender-com-spec=data-element=HMI2RMdRsp/Val, provided-interface=HMI2RMdRsp
      IfVeSMSuHMI2R_StMd{30..32}_Rsp: nonqueued-sender-com-spec=data-element=HMI2RMdRsp/Val, provided-interface=HMI2RMdRsp
      IfVeSMSuHMI2R_StMd{4..9}_Rsp: nonqueued-sender-com-spec=data-element=HMI2RMdRsp/Val, provided-interface=HMI2RMdRsp
      IfVeSMSuStPassCmprtMd{10..19}RclRspStat: nonqueued-sender-com-spec=data-element=MdRclRspStat/Val, provided-interface=MdRclRspStat
      IfVeSMSuStPassCmprtMd1RclRspStat: nonqueued-sender-com-spec=data-element=MdRclRspStat/Val, provided-interface=MdRclRspStat
      IfVeSMSuStPassCmprtMd{20..29}RclRspStat: nonqueued-sender-com-spec=data-element=MdRclRspStat/Val, provided-interface=MdRclRspStat
      IfVeSMSuStPassCmprtMd2RclRspStat: nonqueued-sender-com-spec=data-element=MdRclRspStat/Val, provided-interface=MdRclRspStat
      IfVeSMSuStPassCmprtMd{30..32}RclRspStat: nonqueued-sender-com-spec=data-element=MdRclRspStat/Val, provided-interface=MdRclRspStat
      IfVeSMSuStPassCmprtMd{3..9}RclRspStat: nonqueued-sender-com-spec=data-element=MdRclRspStat/Val, provided-interface=MdRclRspStat
      IfVeSMSuStSrv_StMd1_Rsp: nonqueued-sender-com-spec=data-element=StSrvMdRsp/Val, provided-interface=StSrvMdRsp
      IfVeSMSuStSrv_StMd{10..19}_Rsp: nonqueued-sender-com-spec=data-element=StSrvMdRsp/Val, provided-interface=StSrvMdRsp
      IfVeSMSuStSrv_StMd2_Rsp: nonqueued-sender-com-spec=data-element=StSrvMdRsp/Val, provided-interface=StSrvMdRsp
      IfVeSMSuStSrv_StMd{20..29}_Rsp: nonqueued-sender-com-spec=data-element=StSrvMdRsp/Val, provided-interface=StSrvMdRsp
      IfVeSMSuStSrv_StMd3_Rsp: nonqueued-sender-com-spec=data-element=StSrvMdRsp/Val, provided-interface=StSrvMdRsp
      IfVeSMSuStSrv_StMd{30..32}_Rsp: nonqueued-sender-com-spec=data-element=StSrvMdRsp/Val, provided-interface=StSrvMdRsp
      IfVeSMSuStSrv_StMd{4..9}_Rsp: nonqueued-sender-com-spec=data-element=StSrvMdRsp/Val, provided-interface=StSrvMdRsp
    require port MdXX_RspOutComm: required-interface=MdXX_RspOutComm
      required-com-specs:
        data-element=Md1_RspOutComm, filter=data-filter-type=ALWAYS, init-value=0
        data-element=Md{10..19}_RspOutComm, filter=data-filter-type=ALWAYS, init-value=0
        data-element=Md2_RspOutComm, filter=data-filter-type=ALWAYS, init-value=0
        data-element=Md{20..29}_RspOutComm, filter=data-filter-type=ALWAYS, init-value=0
        data-element=Md3_RspOutComm, filter=data-filter-type=ALWAYS, init-value=0
        data-element=Md{30..32}_RspOutComm, filter=data-filter-type=ALWAYS, init-value=0
        data-element=Md{4..9}_RspOutComm, filter=data-filter-type=ALWAYS, init-value=0
    require port MdXX_SrcReqTp: required-interface=MdXX_SrcReqTp
      required-com-specs:
        data-element=Md1_SrcTp, filter=data-filter-type=ALWAYS, init-value=0
        data-element=Md{10..19}_SrcTp, filter=data-filter-type=ALWAYS, init-value=0
        data-element=Md2_SrcTp, filter=data-filter-type=ALWAYS, init-value=0
        data-element=Md{20..29}_SrcTp, filter=data-filter-type=ALWAYS, init-value=0
        data-element=Md3_SrcTp, filter=data-filter-type=ALWAYS, init-value=0
        data-element=Md{30..32}_SrcTp, filter=data-filter-type=ALWAYS, init-value=0
        data-element=Md{4..9}_SrcTp, filter=data-filter-type=ALWAYS, init-value=0
    behavior MdXX_RspToNetWork_InternalBehavior
      timing event TMT_MdXX_RspSelcRunnable: start-on-event=MdXX_RspToNetWorkRunnable, period=0.01
      runnable MdXX_RspToNetWorkRunnable
        data-receive-point-by-arguments:
          64 x access:
            REC_MdXX_RspOutComm_Md1_RspOutComm: accessed-variable=MdXX_RspOutComm.Md1_RspOutComm
            REC_MdXX_RspOutComm_Md{10..19}_RspOutComm: accessed-variable=MdXX_RspOutComm.Md{10..19}_RspOutComm
            REC_MdXX_RspOutComm_Md2_RspOutComm: accessed-variable=MdXX_RspOutComm.Md2_RspOutComm
            REC_MdXX_RspOutComm_Md{20..29}_RspOutComm: accessed-variable=MdXX_RspOutComm.Md{20..29}_RspOutComm
            REC_MdXX_RspOutComm_Md3_RspOutComm: accessed-variable=MdXX_RspOutComm.Md3_RspOutComm
            REC_MdXX_RspOutComm_Md{30..32}_RspOutComm: accessed-variable=MdXX_RspOutComm.Md{30..32}_RspOutComm
            REC_MdXX_RspOutComm_Md{4..9}_RspOutComm: accessed-variable=MdXX_RspOutComm.Md{4..9}_RspOutComm
            REC_MdXX_SrcReqTp_Md1_SrcTp: accessed-variable=MdXX_SrcReqTp.Md1_SrcTp
            REC_MdXX_SrcReqTp_Md{10..19}_SrcTp: accessed-variable=MdXX_SrcReqTp.Md{10..19}_SrcTp
            REC_MdXX_SrcReqTp_Md2_SrcTp: accessed-variable=MdXX_SrcReqTp.Md2_SrcTp
            REC_MdXX_SrcReqTp_Md{20..29}_SrcTp: accessed-variable=MdXX_SrcReqTp.Md{20..29}_SrcTp
            REC_MdXX_SrcReqTp_Md3_SrcTp: accessed-variable=MdXX_SrcReqTp.Md3_SrcTp
            REC_MdXX_SrcReqTp_Md{30..32}_SrcTp: accessed-variable=MdXX_SrcReqTp.Md{30..32}_SrcTp
            REC_MdXX_SrcReqTp_Md{4..9}_SrcTp: accessed-variable=MdXX_SrcReqTp.Md{4..9}_SrcTp
        data-send-points:
          129 x access:
            SEND_IfVeSMStPassCmprtMd_RfCtrl_Sw_RclRspStat_Val: accessed-variable=IfVeSMStPassCmprtMd_RfCtrl_Sw_RclRspStat.Val
            SEND_IfVeSMSuHMI2L_StMd1_Rsp_Val: accessed-variable=IfVeSMSuHMI2L_StMd1_Rsp.Val
            SEND_IfVeSMSuHMI2L_StMd{10..19}_Rsp_Val: accessed-variable=IfVeSMSuHMI2L_StMd{10..19}_Rsp.Val
            SEND_IfVeSMSuHMI2L_StMd2_Rsp_Val: accessed-variable=IfVeSMSuHMI2L_StMd2_Rsp.Val
            SEND_IfVeSMSuHMI2L_StMd{20..29}_Rsp_Val: accessed-variable=IfVeSMSuHMI2L_StMd{20..29}_Rsp.Val
            SEND_IfVeSMSuHMI2L_StMd3_Rsp_Val: accessed-variable=IfVeSMSuHMI2L_StMd3_Rsp.Val
            SEND_IfVeSMSuHMI2L_StMd{30..32}_Rsp_Val: accessed-variable=IfVeSMSuHMI2L_StMd{30..32}_Rsp.Val
            SEND_IfVeSMSuHMI2L_StMd{4..9}_Rsp_Val: accessed-variable=IfVeSMSuHMI2L_StMd{4..9}_Rsp.Val
            SEND_IfVeSMSuHMI2R_StMd1_Rsp_Val: accessed-variable=IfVeSMSuHMI2R_StMd1_Rsp.Val
            SEND_IfVeSMSuHMI2R_StMd{10..19}_Rsp_Val: accessed-variable=IfVeSMSuHMI2R_StMd{10..19}_Rsp.Val
            SEND_IfVeSMSuHMI2R_StMd2_Rsp_Val: accessed-variable=IfVeSMSuHMI2R_StMd2_Rsp.Val
            SEND_IfVeSMSuHMI2R_StMd{20..29}_Rsp_Val: accessed-variable=IfVeSMSuHMI2R_StMd{20..29}_Rsp.Val
            SEND_IfVeSMSuHMI2R_StMd3_Rsp_Val: accessed-variable=IfVeSMSuHMI2R_StMd3_Rsp.Val
            SEND_IfVeSMSuHMI2R_StMd{30..32}_Rsp_Val: accessed-variable=IfVeSMSuHMI2R_StMd{30..32}_Rsp.Val
            SEND_IfVeSMSuHMI2R_StMd{4..9}_Rsp_Val: accessed-variable=IfVeSMSuHMI2R_StMd{4..9}_Rsp.Val
            SEND_IfVeSMSuStPassCmprtMd{10..19}RclRspStat_Val: accessed-variable=IfVeSMSuStPassCmprtMd{10..19}RclRspStat.Val
            SEND_IfVeSMSuStPassCmprtMd1RclRspStat_Val: accessed-variable=IfVeSMSuStPassCmprtMd1RclRspStat.Val
            SEND_IfVeSMSuStPassCmprtMd{20..29}RclRspStat_Val: accessed-variable=IfVeSMSuStPassCmprtMd{20..29}RclRspStat.Val
            SEND_IfVeSMSuStPassCmprtMd2RclRspStat_Val: accessed-variable=IfVeSMSuStPassCmprtMd2RclRspStat.Val
            SEND_IfVeSMSuStPassCmprtMd{30..32}RclRspStat_Val: accessed-variable=IfVeSMSuStPassCmprtMd{30..32}RclRspStat.Val
            SEND_IfVeSMSuStPassCmprtMd{3..9}RclRspStat_Val: accessed-variable=IfVeSMSuStPassCmprtMd{3..9}RclRspStat.Val
            SEND_IfVeSMSuStSrv_StMd1_Rsp_Val: accessed-variable=IfVeSMSuStSrv_StMd1_Rsp.Val
            SEND_IfVeSMSuStSrv_StMd{10..19}_Rsp_Val: accessed-variable=IfVeSMSuStSrv_StMd{10..19}_Rsp.Val
            SEND_IfVeSMSuStSrv_StMd2_Rsp_Val: accessed-variable=IfVeSMSuStSrv_StMd2_Rsp.Val
            SEND_IfVeSMSuStSrv_StMd{20..29}_Rsp_Val: accessed-variable=IfVeSMSuStSrv_StMd{20..29}_Rsp.Val
            SEND_IfVeSMSuStSrv_StMd3_Rsp_Val: accessed-variable=IfVeSMSuStSrv_StMd3_Rsp.Val
            SEND_IfVeSMSuStSrv_StMd{30..32}_Rsp_Val: accessed-variable=IfVeSMSuStSrv_StMd{30..32}_Rsp.Val
            SEND_IfVeSMSuStSrv_StMd{4..9}_Rsp_Val: accessed-variable=IfVeSMSuStSrv_StMd{4..9}_Rsp.Val
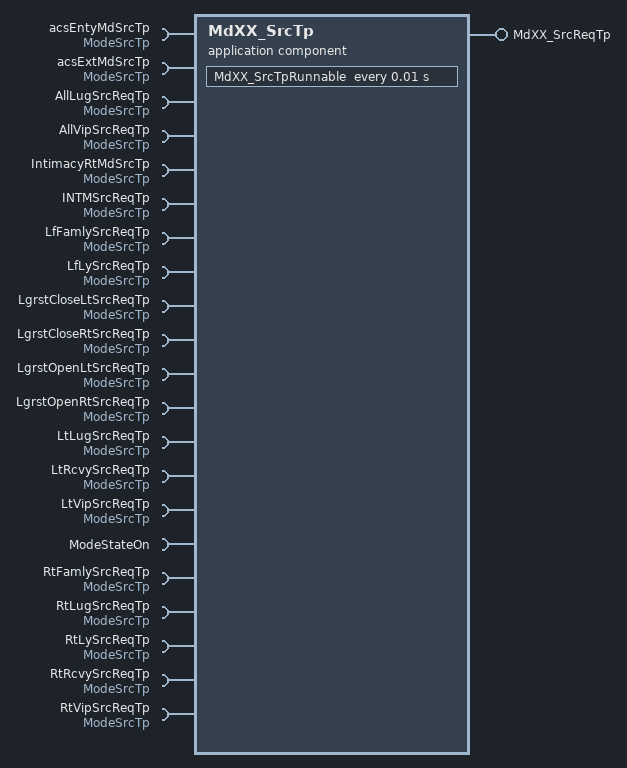
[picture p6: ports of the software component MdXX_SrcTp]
  application sw component type MdXX_SrcTp
    provide port MdXX_SrcReqTp: provided-interface=MdXX_SrcReqTp
      provided-com-specs:
        data-element=Md1_SrcTp, init-value=0
        data-element=Md{10..19}_SrcTp, init-value=0
        data-element=Md2_SrcTp, init-value=0
        data-element=Md{20..29}_SrcTp, init-value=0
        data-element=Md3_SrcTp, init-value=0
        data-element=Md{30..32}_SrcTp, init-value=0
        data-element=Md{4..9}_SrcTp, init-value=0
    21 x require port:
      acsEntyMdSrcTp: nonqueued-receiver-com-spec{data-element=ModeSrcTp/Val, filter=data-filter-type=ALWAYS, init-value=0}, required-interface=ModeSrcTp
      acsExtMdSrcTp: nonqueued-receiver-com-spec{data-element=ModeSrcTp/Val, filter=data-filter-type=ALWAYS, init-value=0}, required-interface=ModeSrcTp
      AllLugSrcReqTp: nonqueued-receiver-com-spec{data-element=ModeSrcTp/Val, filter=data-filter-type=ALWAYS, init-value=0}, required-interface=ModeSrcTp
      AllVipSrcReqTp: nonqueued-receiver-com-spec{data-element=ModeSrcTp/Val, filter=data-filter-type=ALWAYS, init-value=0}, required-interface=ModeSrcTp
      IntimacyRtMdSrcTp: nonqueued-receiver-com-spec{data-element=ModeSrcTp/Val, filter=data-filter-type=ALWAYS, init-value=0}, required-interface=ModeSrcTp
      INTMSrcReqTp: nonqueued-receiver-com-spec{data-element=ModeSrcTp/Val, filter=data-filter-type=ALWAYS, init-value=0}, required-interface=ModeSrcTp
      LfFamlySrcReqTp: nonqueued-receiver-com-spec{data-element=ModeSrcTp/Val, filter=data-filter-type=ALWAYS, init-value=0}, required-interface=ModeSrcTp
      LfLySrcReqTp: nonqueued-receiver-com-spec{data-element=ModeSrcTp/Val, filter=data-filter-type=ALWAYS, init-value=0}, required-interface=ModeSrcTp
      LgrstCloseLtSrcReqTp: nonqueued-receiver-com-spec{data-element=ModeSrcTp/Val, filter=data-filter-type=ALWAYS, init-value=0}, required-interface=ModeSrcTp
      LgrstCloseRtSrcReqTp: nonqueued-receiver-com-spec{data-element=ModeSrcTp/Val, filter=data-filter-type=ALWAYS, init-value=0}, required-interface=ModeSrcTp
      LgrstOpenLtSrcReqTp: nonqueued-receiver-com-spec{data-element=ModeSrcTp/Val, filter=data-filter-type=ALWAYS, init-value=0}, required-interface=ModeSrcTp
      LgrstOpenRtSrcReqTp: nonqueued-receiver-com-spec{data-element=ModeSrcTp/Val, filter=data-filter-type=ALWAYS, init-value=0}, required-interface=ModeSrcTp
      LtLugSrcReqTp: nonqueued-receiver-com-spec{data-element=ModeSrcTp/Val, filter=data-filter-type=ALWAYS, init-value=0}, required-interface=ModeSrcTp
      LtRcvySrcReqTp: nonqueued-receiver-com-spec{data-element=ModeSrcTp/Val, filter=data-filter-type=ALWAYS, init-value=0}, required-interface=ModeSrcTp
      LtVipSrcReqTp: nonqueued-receiver-com-spec{data-element=ModeSrcTp/Val, filter=data-filter-type=ALWAYS, init-value=0}, required-interface=ModeSrcTp
      ModeStateOn: nonqueued-receiver-com-spec{data-element=ModeStateOn/Val, filter=data-filter-type=ALWAYS, init-value=0}, required-interface=ModeStateOn
      RtFamlySrcReqTp: nonqueued-receiver-com-spec{data-element=ModeSrcTp/Val, filter=data-filter-type=ALWAYS, init-value=0}, required-interface=ModeSrcTp
      RtLugSrcReqTp: nonqueued-receiver-com-spec{data-element=ModeSrcTp/Val, filter=data-filter-type=ALWAYS, init-value=0}, required-interface=ModeSrcTp
      RtLySrcReqTp: nonqueued-receiver-com-spec{data-element=ModeSrcTp/Val, filter=data-filter-type=ALWAYS, init-value=0}, required-interface=ModeSrcTp
      RtRcvySrcReqTp: nonqueued-receiver-com-spec{data-element=ModeSrcTp/Val, filter=data-filter-type=ALWAYS, init-value=0}, required-interface=ModeSrcTp
      RtVipSrcReqTp: nonqueued-receiver-com-spec{data-element=ModeSrcTp/Val, filter=data-filter-type=ALWAYS, init-value=0}, required-interface=ModeSrcTp
    behavior MdXX_SrcTp_InternalBehavior
      timing event TMT_MdXX_SrcTpRunnable: start-on-event=MdXX_SrcTpRunnable, period=0.01
      runnable MdXX_SrcTpRunnable
        data-receive-point-by-arguments:
          21 x access:
            REC_acsEntyMdSrcTp_Val: accessed-variable=acsEntyMdSrcTp.Val
            REC_acsExtMdSrcTp_Val: accessed-variable=acsExtMdSrcTp.Val
            REC_AllLugSrcReqTp_Val: accessed-variable=AllLugSrcReqTp.Val
            REC_AllVipSrcReqTp_Val: accessed-variable=AllVipSrcReqTp.Val
            REC_IntimacyRtMdSrcTp_Val: accessed-variable=IntimacyRtMdSrcTp.Val
            REC_INTMSrcReqTp_Val: accessed-variable=INTMSrcReqTp.Val
            REC_LfFamlySrcReqTp_Val: accessed-variable=LfFamlySrcReqTp.Val
            REC_LfLySrcReqTp_Val: accessed-variable=LfLySrcReqTp.Val
            REC_LgrstCloseLtSrcReqTp_Val: accessed-variable=LgrstCloseLtSrcReqTp.Val
            REC_LgrstCloseRtSrcReqTp_Val: accessed-variable=LgrstCloseRtSrcReqTp.Val
            REC_LgrstOpenLtSrcReqTp_Val: accessed-variable=LgrstOpenLtSrcReqTp.Val
            REC_LgrstOpenRtSrcReqTp_Val: accessed-variable=LgrstOpenRtSrcReqTp.Val
            REC_LtLugSrcReqTp_Val: accessed-variable=LtLugSrcReqTp.Val
            REC_LtRcvySrcReqTp_Val: accessed-variable=LtRcvySrcReqTp.Val
            REC_LtVipSrcReqTp_Val: accessed-variable=LtVipSrcReqTp.Val
            REC_ModeStateOn_Val: accessed-variable=ModeStateOn.Val
            REC_RtFamlySrcReqTp_Val: accessed-variable=RtFamlySrcReqTp.Val
            REC_RtLugSrcReqTp_Val: accessed-variable=RtLugSrcReqTp.Val
            REC_RtLySrcReqTp_Val: accessed-variable=RtLySrcReqTp.Val
            REC_RtRcvySrcReqTp_Val: accessed-variable=RtRcvySrcReqTp.Val
            REC_RtVipSrcReqTp_Val: accessed-variable=RtVipSrcReqTp.Val
        data-send-points:
          32 x access:
            SEND_MdXX_SrcReqTp_Md1_SrcTp: accessed-variable=MdXX_SrcReqTp.Md1_SrcTp
            SEND_MdXX_SrcReqTp_Md{10..19}_SrcTp: accessed-variable=MdXX_SrcReqTp.Md{10..19}_SrcTp
            SEND_MdXX_SrcReqTp_Md2_SrcTp: accessed-variable=MdXX_SrcReqTp.Md2_SrcTp
            SEND_MdXX_SrcReqTp_Md{20..29}_SrcTp: accessed-variable=MdXX_SrcReqTp.Md{20..29}_SrcTp
            SEND_MdXX_SrcReqTp_Md3_SrcTp: accessed-variable=MdXX_SrcReqTp.Md3_SrcTp
            SEND_MdXX_SrcReqTp_Md{30..32}_SrcTp: accessed-variable=MdXX_SrcReqTp.Md{30..32}_SrcTp
            SEND_MdXX_SrcReqTp_Md{4..9}_SrcTp: accessed-variable=MdXX_SrcReqTp.Md{4..9}_SrcTp
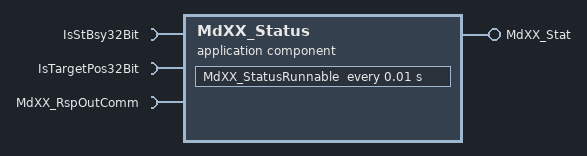
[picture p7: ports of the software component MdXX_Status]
  application sw component type MdXX_Status
    provide port MdXX_Stat: provided-interface=MdXX_Stat
      provided-com-specs:
        data-element=Md1_Stat, init-value=0
        data-element=Md{10..19}_Stat, init-value=0
        data-element=Md2_Stat, init-value=0
        data-element=Md{20..29}_Stat, init-value=0
        data-element=Md3_Stat, init-value=0
        data-element=Md{30..32}_Stat, init-value=0
        data-element=Md{4..9}_Stat, init-value=0
    require port IsStBsy32Bit: nonqueued-receiver-com-spec{data-element=IsStBsy32Bit/Val, filter=data-filter-type=ALWAYS, init-value=0}, required-interface=IsStBsy32Bit
    require port IsTargetPos32Bit: nonqueued-receiver-com-spec{data-element=IsTargetPos32Bit/Val, filter=data-filter-type=ALWAYS, init-value=0}, required-interface=IsTargetPos32Bit
    require port MdXX_RspOutComm: required-interface=MdXX_RspOutComm
      required-com-specs:
        data-element=Md1_RspOutComm, filter=data-filter-type=ALWAYS, init-value=0
        data-element=Md{10..19}_RspOutComm, filter=data-filter-type=ALWAYS, init-value=0
        data-element=Md2_RspOutComm, filter=data-filter-type=ALWAYS, init-value=0
        data-element=Md{20..29}_RspOutComm, filter=data-filter-type=ALWAYS, init-value=0
        data-element=Md3_RspOutComm, filter=data-filter-type=ALWAYS, init-value=0
        data-element=Md{30..32}_RspOutComm, filter=data-filter-type=ALWAYS, init-value=0
        data-element=Md{4..9}_RspOutComm, filter=data-filter-type=ALWAYS, init-value=0
    behavior MdXX_Status_InternalBehavior
      timing event TMT_MdXX_StatusRunnable: start-on-event=MdXX_StatusRunnable, period=0.01
      runnable MdXX_StatusRunnable
        data-receive-point-by-arguments:
          34 x access:
            REC_IsStBsy32Bit_Val: accessed-variable=IsStBsy32Bit.Val
            REC_IsTargetPos32Bit_Val: accessed-variable=IsTargetPos32Bit.Val
            REC_MdXX_RspOutComm_Md1_RspOutComm: accessed-variable=MdXX_RspOutComm.Md1_RspOutComm
            REC_MdXX_RspOutComm_Md{10..19}_RspOutComm: accessed-variable=MdXX_RspOutComm.Md{10..19}_RspOutComm
            REC_MdXX_RspOutComm_Md2_RspOutComm: accessed-variable=MdXX_RspOutComm.Md2_RspOutComm
            REC_MdXX_RspOutComm_Md{20..29}_RspOutComm: accessed-variable=MdXX_RspOutComm.Md{20..29}_RspOutComm
            REC_MdXX_RspOutComm_Md3_RspOutComm: accessed-variable=MdXX_RspOutComm.Md3_RspOutComm
            REC_MdXX_RspOutComm_Md{30..32}_RspOutComm: accessed-variable=MdXX_RspOutComm.Md{30..32}_RspOutComm
            REC_MdXX_RspOutComm_Md{4..9}_RspOutComm: accessed-variable=MdXX_RspOutComm.Md{4..9}_RspOutComm
        data-send-points:
          32 x access:
            SEND_MdXX_Stat_Md1_Stat: accessed-variable=MdXX_Stat.Md1_Stat
            SEND_MdXX_Stat_Md{10..19}_Stat: accessed-variable=MdXX_Stat.Md{10..19}_Stat
            SEND_MdXX_Stat_Md2_Stat: accessed-variable=MdXX_Stat.Md2_Stat
            SEND_MdXX_Stat_Md{20..29}_Stat: accessed-variable=MdXX_Stat.Md{20..29}_Stat
            SEND_MdXX_Stat_Md3_Stat: accessed-variable=MdXX_Stat.Md3_Stat
            SEND_MdXX_Stat_Md{30..32}_Stat: accessed-variable=MdXX_Stat.Md{30..32}_Stat
            SEND_MdXX_Stat_Md{4..9}_Stat: accessed-variable=MdXX_Stat.Md{4..9}_Stat
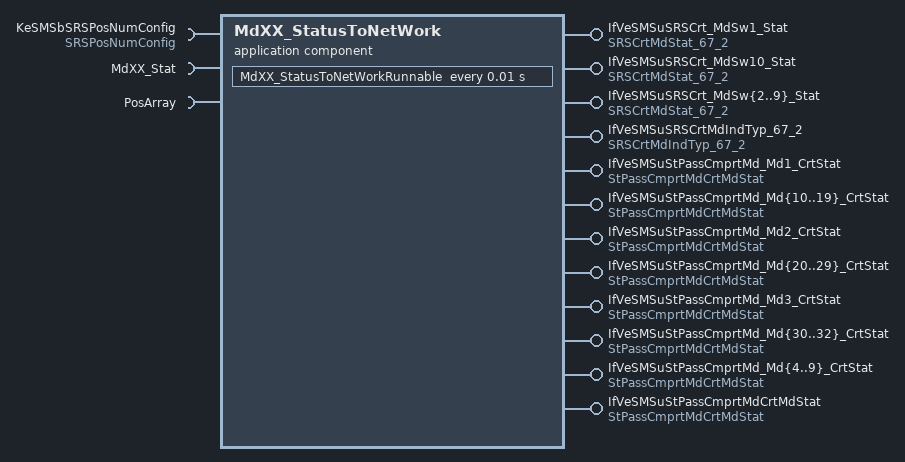
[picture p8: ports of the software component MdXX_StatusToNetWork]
  application sw component type MdXX_StatusToNetWork
    44 x provide port:
      IfVeSMSuSRSCrt_MdSw1_Stat: nonqueued-sender-com-spec=data-element=SRSCrtMdStat_67_2/Val, provided-interface=SRSCrtMdStat_67_2
      IfVeSMSuSRSCrt_MdSw10_Stat: nonqueued-sender-com-spec=data-element=SRSCrtMdStat_67_2/Val, provided-interface=SRSCrtMdStat_67_2
      IfVeSMSuSRSCrt_MdSw{2..9}_Stat: nonqueued-sender-com-spec=data-element=SRSCrtMdStat_67_2/Val, provided-interface=SRSCrtMdStat_67_2
      IfVeSMSuSRSCrtMdIndTyp_67_2: nonqueued-sender-com-spec=data-element=SRSCrtMdIndTyp_67_2/Val, provided-interface=SRSCrtMdIndTyp_67_2
      IfVeSMSuStPassCmprtMd_Md1_CrtStat: nonqueued-sender-com-spec=data-element=StPassCmprtMdCrtMdStat/Val, provided-interface=StPassCmprtMdCrtMdStat
      IfVeSMSuStPassCmprtMd_Md{10..19}_CrtStat: nonqueued-sender-com-spec=data-element=StPassCmprtMdCrtMdStat/Val, provided-interface=StPassCmprtMdCrtMdStat
      IfVeSMSuStPassCmprtMd_Md2_CrtStat: nonqueued-sender-com-spec=data-element=StPassCmprtMdCrtMdStat/Val, provided-interface=StPassCmprtMdCrtMdStat
      IfVeSMSuStPassCmprtMd_Md{20..29}_CrtStat: nonqueued-sender-com-spec=data-element=StPassCmprtMdCrtMdStat/Val, provided-interface=StPassCmprtMdCrtMdStat
      IfVeSMSuStPassCmprtMd_Md3_CrtStat: nonqueued-sender-com-spec=data-element=StPassCmprtMdCrtMdStat/Val, provided-interface=StPassCmprtMdCrtMdStat
      IfVeSMSuStPassCmprtMd_Md{30..32}_CrtStat: nonqueued-sender-com-spec=data-element=StPassCmprtMdCrtMdStat/Val, provided-interface=StPassCmprtMdCrtMdStat
      IfVeSMSuStPassCmprtMd_Md{4..9}_CrtStat: nonqueued-sender-com-spec=data-element=StPassCmprtMdCrtMdStat/Val, provided-interface=StPassCmprtMdCrtMdStat
      IfVeSMSuStPassCmprtMdCrtMdStat: nonqueued-sender-com-spec{data-element=StPassCmprtMdCrtMdStat/Val, init-value=0}, provided-interface=StPassCmprtMdCrtMdStat
    require port KeSMSbSRSPosNumConfig: parameter-require-com-spec{init-value=4, parameter=SRSPosNumConfig/Val}, required-interface=SRSPosNumConfig
    require port MdXX_Stat: required-interface=MdXX_Stat
      required-com-specs:
        data-element=Md1_Stat, filter=data-filter-type=ALWAYS, init-value=0
        data-element=Md{10..19}_Stat, filter=data-filter-type=ALWAYS, init-value=0
        data-element=Md2_Stat, filter=data-filter-type=ALWAYS, init-value=0
        data-element=Md{20..29}_Stat, filter=data-filter-type=ALWAYS, init-value=0
        data-element=Md3_Stat, filter=data-filter-type=ALWAYS, init-value=0
        data-element=Md{30..32}_Stat, filter=data-filter-type=ALWAYS, init-value=0
        data-element=Md{4..9}_Stat, filter=data-filter-type=ALWAYS, init-value=0
    require port PosArray: nonqueued-receiver-com-spec{data-element=PosArray/Val, filter=data-filter-type=ALWAYS, init-value=11 x 0}, required-interface=PosArray
    behavior MdXX_StatusToNetWork_InternalBehavior
      timing event TMT_StPassCmprtMd_MdXX_CrtStatRunnable: start-on-event=MdXX_StatusToNetWorkRunnable, period=0.01
      runnable MdXX_StatusToNetWorkRunnable
        data-receive-point-by-arguments:
          33 x access:
            REC_MdXX_Stat_Md1_Stat: accessed-variable=MdXX_Stat.Md1_Stat
            REC_MdXX_Stat_Md{10..19}_Stat: accessed-variable=MdXX_Stat.Md{10..19}_Stat
            REC_MdXX_Stat_Md2_Stat: accessed-variable=MdXX_Stat.Md2_Stat
            REC_MdXX_Stat_Md{20..29}_Stat: accessed-variable=MdXX_Stat.Md{20..29}_Stat
            REC_MdXX_Stat_Md3_Stat: accessed-variable=MdXX_Stat.Md3_Stat
            REC_MdXX_Stat_Md{30..32}_Stat: accessed-variable=MdXX_Stat.Md{30..32}_Stat
            REC_MdXX_Stat_Md{4..9}_Stat: accessed-variable=MdXX_Stat.Md{4..9}_Stat
            REC_PosArray_Val: accessed-variable=PosArray.Val
        data-send-points:
          44 x access:
            SEND_IfVeSMSuSRSCrt_MdSw1_Stat_Val: accessed-variable=IfVeSMSuSRSCrt_MdSw1_Stat.Val
            SEND_IfVeSMSuSRSCrt_MdSw10_Stat_Val: accessed-variable=IfVeSMSuSRSCrt_MdSw10_Stat.Val
            SEND_IfVeSMSuSRSCrt_MdSw{2..9}_Stat_Val: accessed-variable=IfVeSMSuSRSCrt_MdSw{2..9}_Stat.Val
            SEND_IfVeSMSuSRSCrtMdIndTyp_67_2_Val: accessed-variable=IfVeSMSuSRSCrtMdIndTyp_67_2.Val
            SEND_IfVeSMSuStPassCmprtMd_Md1_CrtStat_Val: accessed-variable=IfVeSMSuStPassCmprtMd_Md1_CrtStat.Val
            SEND_IfVeSMSuStPassCmprtMd_Md{10..19}_CrtStat_Val: accessed-variable=IfVeSMSuStPassCmprtMd_Md{10..19}_CrtStat.Val
            SEND_IfVeSMSuStPassCmprtMd_Md2_CrtStat_Val: accessed-variable=IfVeSMSuStPassCmprtMd_Md2_CrtStat.Val
            SEND_IfVeSMSuStPassCmprtMd_Md{20..29}_CrtStat_Val: accessed-variable=IfVeSMSuStPassCmprtMd_Md{20..29}_CrtStat.Val
            SEND_IfVeSMSuStPassCmprtMd_Md3_CrtStat_Val: accessed-variable=IfVeSMSuStPassCmprtMd_Md3_CrtStat.Val
            SEND_IfVeSMSuStPassCmprtMd_Md{30..32}_CrtStat_Val: accessed-variable=IfVeSMSuStPassCmprtMd_Md{30..32}_CrtStat.Val
            SEND_IfVeSMSuStPassCmprtMd_Md{4..9}_CrtStat_Val: accessed-variable=IfVeSMSuStPassCmprtMd_Md{4..9}_CrtStat.Val
            SEND_IfVeSMSuStPassCmprtMdCrtMdStat_Val: accessed-variable=IfVeSMSuStPassCmprtMdCrtMdStat.Val
        parameter access PA_KeSMSbSRSPosNumConfig_Val: accessed-parameter=KeSMSbSRSPosNumConfig.Val
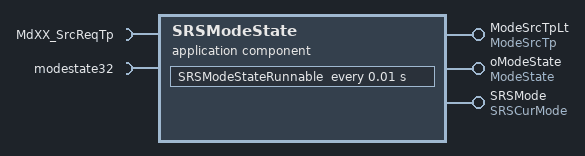
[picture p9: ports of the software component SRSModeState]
  application sw component type SRSModeState
    provide port ModeSrcTpLt: nonqueued-sender-com-spec{data-element=ModeSrcTp/Val, init-value=0}, provided-interface=ModeSrcTp
    provide port oModeState: nonqueued-sender-com-spec=data-element=ModeState/Val, provided-interface=ModeState
    provide port SRSMode: nonqueued-sender-com-spec=data-element=SRSCurMode/Val, provided-interface=SRSCurMode
    require port MdXX_SrcReqTp: required-interface=MdXX_SrcReqTp
      required-com-specs:
        data-element=Md1_SrcTp, filter=data-filter-type=ALWAYS, init-value=0
        data-element=Md{10..19}_SrcTp, filter=data-filter-type=ALWAYS, init-value=0
        data-element=Md2_SrcTp, filter=data-filter-type=ALWAYS, init-value=0
        data-element=Md{20..29}_SrcTp, filter=data-filter-type=ALWAYS, init-value=0
        data-element=Md3_SrcTp, filter=data-filter-type=ALWAYS, init-value=0
        data-element=Md{30..32}_SrcTp, filter=data-filter-type=ALWAYS, init-value=0
        data-element=Md{4..9}_SrcTp, filter=data-filter-type=ALWAYS, init-value=0
    require port modestate32: nonqueued-receiver-com-spec{data-element=modestate32/Val, filter=data-filter-type=ALWAYS, init-value=0}, required-interface=modestate32
    behavior SRSModeState_InternalBehavior
      timing event TMT_SRSModeStateRunnable: start-on-event=SRSModeStateRunnable, period=0.01
      runnable SRSModeStateRunnable
        data-receive-point-by-arguments:
          33 x access:
            REC_MdXX_SrcReqTp_Md1_SrcTp: accessed-variable=MdXX_SrcReqTp.Md1_SrcTp
            REC_MdXX_SrcReqTp_Md{10..19}_SrcTp: accessed-variable=MdXX_SrcReqTp.Md{10..19}_SrcTp
            REC_MdXX_SrcReqTp_Md2_SrcTp: accessed-variable=MdXX_SrcReqTp.Md2_SrcTp
            REC_MdXX_SrcReqTp_Md{20..29}_SrcTp: accessed-variable=MdXX_SrcReqTp.Md{20..29}_SrcTp
            REC_MdXX_SrcReqTp_Md3_SrcTp: accessed-variable=MdXX_SrcReqTp.Md3_SrcTp
            REC_MdXX_SrcReqTp_Md{30..32}_SrcTp: accessed-variable=MdXX_SrcReqTp.Md{30..32}_SrcTp
            REC_MdXX_SrcReqTp_Md{4..9}_SrcTp: accessed-variable=MdXX_SrcReqTp.Md{4..9}_SrcTp
            REC_modestate32_Val: accessed-variable=modestate32.Val
        data-send-points:
          access SEND_ModeSrcTpLt_Val: accessed-variable=ModeSrcTpLt.Val
          access SEND_oModeState_Val: accessed-variable=oModeState.Val
          access SEND_SRSMode_Val: accessed-variable=SRSMode.Val
  application sw component type StateOnOffChk
    provide port ModeStateOn: nonqueued-sender-com-spec{data-element=ModeStateOn/Val, init-value=0}, provided-interface=ModeStateOn
    require port CommCond: nonqueued-receiver-com-spec{data-element=CommCond/Val, filter=data-filter-type=ALWAYS, init-value=0}, required-interface=CommCond
    require port modestate32: nonqueued-receiver-com-spec{data-element=modestate32/Val, filter=data-filter-type=ALWAYS, init-value=0}, required-interface=modestate32
    behavior StateOnOffChk_InternalBehavior
      timing event TMT_StateOnOffChkRunnable: start-on-event=StateOnOffChkRunnable, period=0.01
      runnable StateOnOffChkRunnable
        data-receive-point-by-arguments:
          access REC_CommCond_Val: accessed-variable=CommCond.Val
          access REC_modestate32_Val: accessed-variable=modestate32.Val
        data-send-points:
          access SEND_ModeOnState_Val: accessed-variable=ModeStateOn.Val
  application sw component type StNumChk
    provide port StNumFlg: provided-interface=StNumFlg
      provided-com-specs:
        data-element=Is4s, init-value=0
        data-element=Is6s, init-value=0
        data-element=Is6s7s, init-value=0
        data-element=Is7s, init-value=0
    require port IfVeSMSeStNumConfig: nonqueued-receiver-com-spec{data-element=IfVeSMSeStNumConfig/Val, filter=data-filter-type=ALWAYS, init-value=0}, required-interface=IfVeSMSeStNumConfig
    behavior StNumChk_InternalBehavior
      timing event Runnable_InitEvent: start-on-event=StNumChkRunnable, period=0
      runnable StNumChkRunnable
        data-receive-point-by-arguments:
          access REC_IfVeSMSeStNumConfig_Val: accessed-variable=IfVeSMSeStNumConfig.Val
        data-send-points:
          4 x access:
            SEND_StNumFlg_Is4s: accessed-variable=StNumFlg.Is4s
            SEND_StNumFlg_Is6s: accessed-variable=StNumFlg.Is6s
            SEND_StNumFlg_Is6s7s: accessed-variable=StNumFlg.Is6s7s
            SEND_StNumFlg_Is7s: accessed-variable=StNumFlg.Is7s
  application sw component type StPassCmprtMdHMIDisCmd
    provide port IfVeSMSuStPassCmprtMdHMIDisCmd: nonqueued-sender-com-spec=data-element=StPassCmprtMdHMIDisCmdSrv/Val, provided-interface=StPassCmprtMdHMIDisCmdSrv
    require port modestate32: nonqueued-receiver-com-spec{data-element=modestate32/Val, filter=data-filter-type=ALWAYS, init-value=0}, required-interface=modestate32
    require port PwrMdChked: nonqueued-receiver-com-spec{data-element=PowerMode/Val, filter=data-filter-type=ALWAYS}, required-interface=PowerMode
    behavior StPassCmprtMdHMIDisCmd_InternalBehavior
      timing event TMT_StPassCmprtMdHMIDisCmdRunnable: start-on-event=StPassCmprtMdHMIDisCmdRunnable, period=0.01
      runnable StPassCmprtMdHMIDisCmdRunnable
        data-receive-point-by-arguments:
          access REC_modestate32_Val: accessed-variable=modestate32.Val
          access REC_PwrMdChked_Val: accessed-variable=PwrMdChked.Val
        data-send-points:
          access SEND_IfVeSMSuStPassCmprtMdHMIDisCmd_Val: accessed-variable=IfVeSMSuStPassCmprtMdHMIDisCmd.Val
  composition sw component type ModeRsp
    178 x provide port:
      IfVeSMSeStPassCmprtMdNoti2ChmEvntStat: nonqueued-sender-com-spec=data-element=ChmEvenState/Val, provided-interface=ChmEvenState
      IfVeSMStPassCmprtMd_RfCtrl_Sw_RclRspStat: nonqueued-sender-com-spec=data-element=MdRclRspStat/Val, provided-interface=MdRclRspStat
      IfVeSMSuHMI2L_StMd1_Rsp: nonqueued-sender-com-spec=data-element=HMI2LMdRsp/Val, provided-interface=HMI2LMdRsp
      IfVeSMSuHMI2L_StMd{10..19}_Rsp: nonqueued-sender-com-spec=data-element=HMI2LMdRsp/Val, provided-interface=HMI2LMdRsp
      IfVeSMSuHMI2L_StMd2_Rsp: nonqueued-sender-com-spec=data-element=HMI2LMdRsp/Val, provided-interface=HMI2LMdRsp
      IfVeSMSuHMI2L_StMd20_Rsp: nonqueued-sender-com-spec=data-element=HMI2LMdRsp/Val, provided-interface=HMI2LMdRsp
      IfVeSMSuHMI2L_StMd21_Rsp: nonqueued-sender-com-spec=data-element=HMI2LMdRsp/Val, provided-interface=HMI2LMdRsp
      IfVeSMSuHMI2L_StMd22_Rsp: nonqueued-sender-com-spec{data-element=HMI2LMdRsp/Val, init-value=0}, provided-interface=HMI2LMdRsp
      IfVeSMSuHMI2L_StMd{23..29}_Rsp: nonqueued-sender-com-spec=data-element=HMI2LMdRsp/Val, provided-interface=HMI2LMdRsp
      IfVeSMSuHMI2L_StMd3_Rsp: nonqueued-sender-com-spec=data-element=HMI2LMdRsp/Val, provided-interface=HMI2LMdRsp
      IfVeSMSuHMI2L_StMd{30..32}_Rsp: nonqueued-sender-com-spec=data-element=HMI2LMdRsp/Val, provided-interface=HMI2LMdRsp
      IfVeSMSuHMI2L_StMd{4..9}_Rsp: nonqueued-sender-com-spec=data-element=HMI2LMdRsp/Val, provided-interface=HMI2LMdRsp
      IfVeSMSuHMI2R_StMd1_Rsp: nonqueued-sender-com-spec=data-element=HMI2RMdRsp/Val, provided-interface=HMI2RMdRsp
      IfVeSMSuHMI2R_StMd{10..19}_Rsp: nonqueued-sender-com-spec=data-element=HMI2RMdRsp/Val, provided-interface=HMI2RMdRsp
      IfVeSMSuHMI2R_StMd2_Rsp: nonqueued-sender-com-spec=data-element=HMI2RMdRsp/Val, provided-interface=HMI2RMdRsp
      IfVeSMSuHMI2R_StMd{20..29}_Rsp: nonqueued-sender-com-spec=data-element=HMI2RMdRsp/Val, provided-interface=HMI2RMdRsp
      IfVeSMSuHMI2R_StMd3_Rsp: nonqueued-sender-com-spec=data-element=HMI2RMdRsp/Val, provided-interface=HMI2RMdRsp
      IfVeSMSuHMI2R_StMd{30..32}_Rsp: nonqueued-sender-com-spec=data-element=HMI2RMdRsp/Val, provided-interface=HMI2RMdRsp
      IfVeSMSuHMI2R_StMd{4..9}_Rsp: nonqueued-sender-com-spec=data-element=HMI2RMdRsp/Val, provided-interface=HMI2RMdRsp
      IfVeSMSuSRSCrt_MdSw1_Stat: nonqueued-sender-com-spec=data-element=SRSCrtMdStat_67_2/Val, provided-interface=SRSCrtMdStat_67_2
      IfVeSMSuSRSCrt_MdSw10_Stat: nonqueued-sender-com-spec=data-element=SRSCrtMdStat_67_2/Val, provided-interface=SRSCrtMdStat_67_2
      IfVeSMSuSRSCrt_MdSw{2..9}_Stat: nonqueued-sender-com-spec=data-element=SRSCrtMdStat_67_2/Val, provided-interface=SRSCrtMdStat_67_2
      IfVeSMSuSRSCrtMdIndTyp_67_2: nonqueued-sender-com-spec=data-element=SRSCrtMdIndTyp_67_2/Val, provided-interface=SRSCrtMdIndTyp_67_2
      IfVeSMSuStPassCmprtMd_Md1_CrtStat: nonqueued-sender-com-spec=data-element=StPassCmprtMdCrtMdStat/Val, provided-interface=StPassCmprtMdCrtMdStat
      IfVeSMSuStPassCmprtMd_Md{10..19}_CrtStat: nonqueued-sender-com-spec=data-element=StPassCmprtMdCrtMdStat/Val, provided-interface=StPassCmprtMdCrtMdStat
      IfVeSMSuStPassCmprtMd_Md2_CrtStat: nonqueued-sender-com-spec=data-element=StPassCmprtMdCrtMdStat/Val, provided-interface=StPassCmprtMdCrtMdStat
      IfVeSMSuStPassCmprtMd_Md{20..29}_CrtStat: nonqueued-sender-com-spec=data-element=StPassCmprtMdCrtMdStat/Val, provided-interface=StPassCmprtMdCrtMdStat
      IfVeSMSuStPassCmprtMd_Md3_CrtStat: nonqueued-sender-com-spec=data-element=StPassCmprtMdCrtMdStat/Val, provided-interface=StPassCmprtMdCrtMdStat
      IfVeSMSuStPassCmprtMd_Md{30..32}_CrtStat: nonqueued-sender-com-spec=data-element=StPassCmprtMdCrtMdStat/Val, provided-interface=StPassCmprtMdCrtMdStat
      IfVeSMSuStPassCmprtMd_Md{4..9}_CrtStat: nonqueued-sender-com-spec=data-element=StPassCmprtMdCrtMdStat/Val, provided-interface=StPassCmprtMdCrtMdStat
      IfVeSMSuStPassCmprtMd{10..19}RclRspStat: nonqueued-sender-com-spec=data-element=MdRclRspStat/Val, provided-interface=MdRclRspStat
      IfVeSMSuStPassCmprtMd1RclRspStat: nonqueued-sender-com-spec=data-element=MdRclRspStat/Val, provided-interface=MdRclRspStat
      IfVeSMSuStPassCmprtMd{20..29}RclRspStat: nonqueued-sender-com-spec=data-element=MdRclRspStat/Val, provided-interface=MdRclRspStat
      IfVeSMSuStPassCmprtMd2RclRspStat: nonqueued-sender-com-spec=data-element=MdRclRspStat/Val, provided-interface=MdRclRspStat
      IfVeSMSuStPassCmprtMd{30..32}RclRspStat: nonqueued-sender-com-spec=data-element=MdRclRspStat/Val, provided-interface=MdRclRspStat
      IfVeSMSuStPassCmprtMd{3..9}RclRspStat: nonqueued-sender-com-spec=data-element=MdRclRspStat/Val, provided-interface=MdRclRspStat
      IfVeSMSuStPassCmprtMdCrtMdStat: nonqueued-sender-com-spec{data-element=StPassCmprtMdCrtMdStat/Val, init-value=0}, provided-interface=StPassCmprtMdCrtMdStat
      IfVeSMSuStPassCmprtMdHMIDisCmd: nonqueued-sender-com-spec=data-element=StPassCmprtMdHMIDisCmdSrv/Val, provided-interface=StPassCmprtMdHMIDisCmdSrv
      IfVeSMSuStSrv_StMd1_Rsp: nonqueued-sender-com-spec=data-element=StSrvMdRsp/Val, provided-interface=StSrvMdRsp
      IfVeSMSuStSrv_StMd{10..19}_Rsp: nonqueued-sender-com-spec=data-element=StSrvMdRsp/Val, provided-interface=StSrvMdRsp
      IfVeSMSuStSrv_StMd2_Rsp: nonqueued-sender-com-spec=data-element=StSrvMdRsp/Val, provided-interface=StSrvMdRsp
      IfVeSMSuStSrv_StMd{20..29}_Rsp: nonqueued-sender-com-spec=data-element=StSrvMdRsp/Val, provided-interface=StSrvMdRsp
      IfVeSMSuStSrv_StMd3_Rsp: nonqueued-sender-com-spec=data-element=StSrvMdRsp/Val, provided-interface=StSrvMdRsp
      IfVeSMSuStSrv_StMd{30..32}_Rsp: nonqueued-sender-com-spec=data-element=StSrvMdRsp/Val, provided-interface=StSrvMdRsp
      IfVeSMSuStSrv_StMd{4..9}_Rsp: nonqueued-sender-com-spec=data-element=StSrvMdRsp/Val, provided-interface=StSrvMdRsp
      ModeSrcTpLt: nonqueued-sender-com-spec{data-element=ModeSrcTp/Val, init-value=0}, provided-interface=ModeSrcTp
      oModeState: nonqueued-sender-com-spec=data-element=ModeState/Val, provided-interface=ModeState
      SRSMode: nonqueued-sender-com-spec=data-element=SRSCurMode/Val, provided-interface=SRSCurMode
    13 x require port:
      IfVeSMSuChmMgrStat: nonqueued-receiver-com-spec{data-element=IfVeSMSuChmMgrStat/Val, filter=data-filter-type=ALWAYS}, required-interface=IfVeSMSuChmMgrStat
      IsStBsy32Bit: nonqueued-receiver-com-spec{data-element=IsStBsy32Bit/Val, filter=data-filter-type=ALWAYS, init-value=0}, required-interface=IsStBsy32Bit
      IsTargetPos32Bit: nonqueued-receiver-com-spec{data-element=IsTargetPos32Bit/Val, filter=data-filter-type=ALWAYS, init-value=0}, required-interface=IsTargetPos32Bit
      KeSMSbMdChime2Enable: parameter-require-com-spec{init-value=0, parameter=MdChime2Enable/Val}, required-interface=MdChime2Enable
      KeSMSbSRSPosNumConfig: parameter-require-com-spec{init-value=4, parameter=SRSPosNumConfig/Val}, required-interface=SRSPosNumConfig
      KeSMSuChmReqDurnTm: parameter-require-com-spec{init-value=200, parameter=KeSMSuChmReqDurnTm/Val}, required-interface=KeSMSuChmReqDurnTm
      KeSMSuChmReqIntlTm: parameter-require-com-spec{init-value=50, parameter=KeSMSuChmReqIntlTm/Val}, required-interface=KeSMSuChmReqIntlTm
      KeSMSuRspStatHldTm: parameter-require-com-spec{init-value=100, parameter=KeSMSuRspStatHldTm/Val}, required-interface=KeSMSuRspStatHldTm
      MdXX_Rsp: required-interface=MdXX_Rsp
        required-com-specs:
          data-element=Md1_Rsp, filter=data-filter-type=ALWAYS, init-value=0
          data-element=Md{10..19}_Rsp, filter=data-filter-type=ALWAYS, init-value=0
          data-element=Md2_Rsp, filter=data-filter-type=ALWAYS, init-value=0
          data-element=Md{20..29}_Rsp, filter=data-filter-type=ALWAYS, init-value=0
          data-element=Md3_Rsp, filter=data-filter-type=ALWAYS, init-value=0
          data-element=Md{30..32}_Rsp, filter=data-filter-type=ALWAYS, init-value=0
          data-element=Md{4..9}_Rsp, filter=data-filter-type=ALWAYS, init-value=0
      MdXX_SrcReqTp: required-interface=MdXX_SrcReqTp
        required-com-specs:
          data-element=Md1_SrcTp, filter=data-filter-type=ALWAYS, init-value=0
          data-element=Md{10..19}_SrcTp, filter=data-filter-type=ALWAYS, init-value=0
          data-element=Md2_SrcTp, filter=data-filter-type=ALWAYS, init-value=0
          data-element=Md20_SrcTp, filter=data-filter-type=ALWAYS, init-value=0
          data-element=Md{21..29}_SrcTp, filter=data-filter-type=ALWAYS
          data-element=Md3_SrcTp, filter=data-filter-type=ALWAYS, init-value=0
          data-element=Md{30..32}_SrcTp, filter=data-filter-type=ALWAYS
          data-element=Md{4..9}_SrcTp, filter=data-filter-type=ALWAYS, init-value=0
      modestate32: nonqueued-receiver-com-spec{data-element=modestate32/Val, filter=data-filter-type=ALWAYS, init-value=0}, required-interface=modestate32
      PosArray: nonqueued-receiver-com-spec{data-element=PosArray/Val, filter=data-filter-type=ALWAYS, init-value=11 x 0}, required-interface=PosArray
      PwrMdChked: nonqueued-receiver-com-spec{data-element=PowerMode/Val, filter=data-filter-type=ALWAYS}, required-interface=PowerMode
    7 x component:
      CHM2Ctrl: type=CHM2Ctrl
      MdXX_Rsp1: type=MdXX_Rsp
      MdXX_RspToNetWork: type=MdXX_RspToNetWork
      MdXX_Status: type=MdXX_Status
      MdXX_StatusToNetWork: type=MdXX_StatusToNetWork
      SRSModeState: type=SRSModeState
      StPassCmprtMdHMIDisCmd: type=StPassCmprtMdHMIDisCmd
    connect MdXX_Rsp1.MdXX_RspOutComm -> MdXX_RspToNetWork.MdXX_RspOutComm
    connect MdXX_Rsp1.MdXX_SrcReqTpOutComm -> MdXX_RspToNetWork.MdXX_SrcReqTp
    connect MdXX_Rsp1.MdXX_RspOutComm -> MdXX_Status.MdXX_RspOutComm
    connect MdXX_Rsp1.MdXX_SrcReqTpOutComm -> SRSModeState.MdXX_SrcReqTp
    connect MdXX_Status.MdXX_Stat -> MdXX_StatusToNetWork.MdXX_Stat
    delegate CHM2Ctrl.IfVeSMSeStPassCmprtMdNoti2ChmEvntStat <-> outer port ModeRsp/IfVeSMSeStPassCmprtMdNoti2ChmEvntStat
    delegate MdXX_RspToNetWork.IfVeSMStPassCmprtMd_RfCtrl_Sw_RclRspStat <-> outer port ModeRsp/IfVeSMStPassCmprtMd_RfCtrl_Sw_RclRspStat
    delegate CHM2Ctrl.IfVeSMSuChmMgrStat <-> outer port ModeRsp/IfVeSMSuChmMgrStat
    delegate MdXX_RspToNetWork.IfVeSMSuHMI2L_StMd1_Rsp <-> outer port ModeRsp/IfVeSMSuHMI2L_StMd1_Rsp
    delegate MdXX_RspToNetWork.IfVeSMSuHMI2L_StMd{10..19}_Rsp <-> outer port ModeRsp/IfVeSMSuHMI2L_StMd{10..19}_Rsp
    delegate MdXX_RspToNetWork.IfVeSMSuHMI2L_StMd2_Rsp <-> outer port ModeRsp/IfVeSMSuHMI2L_StMd2_Rsp
    delegate MdXX_RspToNetWork.IfVeSMSuHMI2L_StMd{20..29}_Rsp <-> outer port ModeRsp/IfVeSMSuHMI2L_StMd{20..29}_Rsp
    delegate MdXX_RspToNetWork.IfVeSMSuHMI2L_StMd3_Rsp <-> outer port ModeRsp/IfVeSMSuHMI2L_StMd3_Rsp
    delegate MdXX_RspToNetWork.IfVeSMSuHMI2L_StMd{30..32}_Rsp <-> outer port ModeRsp/IfVeSMSuHMI2L_StMd{30..32}_Rsp
    delegate MdXX_RspToNetWork.IfVeSMSuHMI2L_StMd{4..9}_Rsp <-> outer port ModeRsp/IfVeSMSuHMI2L_StMd{4..9}_Rsp
    delegate MdXX_RspToNetWork.IfVeSMSuHMI2R_StMd1_Rsp <-> outer port ModeRsp/IfVeSMSuHMI2R_StMd1_Rsp
    delegate MdXX_RspToNetWork.IfVeSMSuHMI2R_StMd{10..19}_Rsp <-> outer port ModeRsp/IfVeSMSuHMI2R_StMd{10..19}_Rsp
    delegate MdXX_RspToNetWork.IfVeSMSuHMI2R_StMd2_Rsp <-> outer port ModeRsp/IfVeSMSuHMI2R_StMd2_Rsp
    delegate MdXX_RspToNetWork.IfVeSMSuHMI2R_StMd{20..29}_Rsp <-> outer port ModeRsp/IfVeSMSuHMI2R_StMd{20..29}_Rsp
    delegate MdXX_RspToNetWork.IfVeSMSuHMI2R_StMd3_Rsp <-> outer port ModeRsp/IfVeSMSuHMI2R_StMd3_Rsp
    delegate MdXX_RspToNetWork.IfVeSMSuHMI2R_StMd{30..32}_Rsp <-> outer port ModeRsp/IfVeSMSuHMI2R_StMd{30..32}_Rsp
    delegate MdXX_RspToNetWork.IfVeSMSuHMI2R_StMd{4..9}_Rsp <-> outer port ModeRsp/IfVeSMSuHMI2R_StMd{4..9}_Rsp
    delegate MdXX_StatusToNetWork.IfVeSMSuSRSCrt_MdSw1_Stat <-> outer port ModeRsp/IfVeSMSuSRSCrt_MdSw1_Stat
    delegate MdXX_StatusToNetWork.IfVeSMSuSRSCrt_MdSw10_Stat <-> outer port ModeRsp/IfVeSMSuSRSCrt_MdSw10_Stat
    delegate MdXX_StatusToNetWork.IfVeSMSuSRSCrt_MdSw{2..9}_Stat <-> outer port ModeRsp/IfVeSMSuSRSCrt_MdSw{2..9}_Stat
    delegate MdXX_StatusToNetWork.IfVeSMSuSRSCrtMdIndTyp_67_2 <-> outer port ModeRsp/IfVeSMSuSRSCrtMdIndTyp_67_2
    delegate MdXX_StatusToNetWork.IfVeSMSuStPassCmprtMd_Md1_CrtStat <-> outer port ModeRsp/IfVeSMSuStPassCmprtMd_Md1_CrtStat
    delegate MdXX_StatusToNetWork.IfVeSMSuStPassCmprtMd_Md{10..19}_CrtStat <-> outer port ModeRsp/IfVeSMSuStPassCmprtMd_Md{10..19}_CrtStat
    delegate MdXX_StatusToNetWork.IfVeSMSuStPassCmprtMd_Md2_CrtStat <-> outer port ModeRsp/IfVeSMSuStPassCmprtMd_Md2_CrtStat
    delegate MdXX_StatusToNetWork.IfVeSMSuStPassCmprtMd_Md{20..29}_CrtStat <-> outer port ModeRsp/IfVeSMSuStPassCmprtMd_Md{20..29}_CrtStat
    delegate MdXX_StatusToNetWork.IfVeSMSuStPassCmprtMd_Md3_CrtStat <-> outer port ModeRsp/IfVeSMSuStPassCmprtMd_Md3_CrtStat
    delegate MdXX_StatusToNetWork.IfVeSMSuStPassCmprtMd_Md{30..32}_CrtStat <-> outer port ModeRsp/IfVeSMSuStPassCmprtMd_Md{30..32}_CrtStat
    delegate MdXX_StatusToNetWork.IfVeSMSuStPassCmprtMd_Md{4..9}_CrtStat <-> outer port ModeRsp/IfVeSMSuStPassCmprtMd_Md{4..9}_CrtStat
    delegate MdXX_RspToNetWork.IfVeSMSuStPassCmprtMd{10..19}RclRspStat <-> outer port ModeRsp/IfVeSMSuStPassCmprtMd{10..19}RclRspStat
    delegate MdXX_RspToNetWork.IfVeSMSuStPassCmprtMd1RclRspStat <-> outer port ModeRsp/IfVeSMSuStPassCmprtMd1RclRspStat
    delegate MdXX_RspToNetWork.IfVeSMSuStPassCmprtMd{20..29}RclRspStat <-> outer port ModeRsp/IfVeSMSuStPassCmprtMd{20..29}RclRspStat
    delegate MdXX_RspToNetWork.IfVeSMSuStPassCmprtMd2RclRspStat <-> outer port ModeRsp/IfVeSMSuStPassCmprtMd2RclRspStat
    delegate MdXX_RspToNetWork.IfVeSMSuStPassCmprtMd{30..32}RclRspStat <-> outer port ModeRsp/IfVeSMSuStPassCmprtMd{30..32}RclRspStat
    delegate MdXX_RspToNetWork.IfVeSMSuStPassCmprtMd{3..9}RclRspStat <-> outer port ModeRsp/IfVeSMSuStPassCmprtMd{3..9}RclRspStat
    delegate MdXX_StatusToNetWork.IfVeSMSuStPassCmprtMdCrtMdStat <-> outer port ModeRsp/IfVeSMSuStPassCmprtMdCrtMdStat
    delegate StPassCmprtMdHMIDisCmd.IfVeSMSuStPassCmprtMdHMIDisCmd <-> outer port ModeRsp/IfVeSMSuStPassCmprtMdHMIDisCmd
    delegate MdXX_RspToNetWork.IfVeSMSuStSrv_StMd1_Rsp <-> outer port ModeRsp/IfVeSMSuStSrv_StMd1_Rsp
    delegate MdXX_RspToNetWork.IfVeSMSuStSrv_StMd{10..19}_Rsp <-> outer port ModeRsp/IfVeSMSuStSrv_StMd{10..19}_Rsp
    delegate MdXX_RspToNetWork.IfVeSMSuStSrv_StMd2_Rsp <-> outer port ModeRsp/IfVeSMSuStSrv_StMd2_Rsp
    delegate MdXX_RspToNetWork.IfVeSMSuStSrv_StMd{20..29}_Rsp <-> outer port ModeRsp/IfVeSMSuStSrv_StMd{20..29}_Rsp
    delegate MdXX_RspToNetWork.IfVeSMSuStSrv_StMd3_Rsp <-> outer port ModeRsp/IfVeSMSuStSrv_StMd3_Rsp
    delegate MdXX_RspToNetWork.IfVeSMSuStSrv_StMd{30..32}_Rsp <-> outer port ModeRsp/IfVeSMSuStSrv_StMd{30..32}_Rsp
    delegate MdXX_RspToNetWork.IfVeSMSuStSrv_StMd{4..9}_Rsp <-> outer port ModeRsp/IfVeSMSuStSrv_StMd{4..9}_Rsp
    delegate MdXX_Status.IsStBsy32Bit <-> outer port ModeRsp/IsStBsy32Bit
    delegate MdXX_Rsp1.IsTargetPos32Bit <-> outer port ModeRsp/IsTargetPos32Bit
    delegate MdXX_Status.IsTargetPos32Bit <-> outer port ModeRsp/IsTargetPos32Bit
    delegate CHM2Ctrl.KeSMSbMdChime2Enable <-> outer port ModeRsp/KeSMSbMdChime2Enable
    delegate MdXX_StatusToNetWork.KeSMSbSRSPosNumConfig <-> outer port ModeRsp/KeSMSbSRSPosNumConfig
    delegate CHM2Ctrl.KeSMSuChmReqDurnTm <-> outer port ModeRsp/KeSMSuChmReqDurnTm
    delegate CHM2Ctrl.KeSMSuChmReqIntlTm <-> outer port ModeRsp/KeSMSuChmReqIntlTm
    delegate MdXX_Rsp1.KeSMSuRspStatHldTm <-> outer port ModeRsp/KeSMSuRspStatHldTm
    delegate MdXX_Rsp1.MdXX_Rsp <-> outer port ModeRsp/MdXX_Rsp
    delegate MdXX_Rsp1.MdXX_SrcReqTp <-> outer port ModeRsp/MdXX_SrcReqTp
    delegate SRSModeState.ModeSrcTpLt <-> outer port ModeRsp/ModeSrcTpLt
    delegate MdXX_Rsp1.modestate32 <-> outer port ModeRsp/modestate32
    delegate CHM2Ctrl.modestate32 <-> outer port ModeRsp/modestate32
    delegate StPassCmprtMdHMIDisCmd.modestate32 <-> outer port ModeRsp/modestate32
    delegate SRSModeState.modestate32 <-> outer port ModeRsp/modestate32
    delegate SRSModeState.oModeState <-> outer port ModeRsp/oModeState
    delegate MdXX_StatusToNetWork.PosArray <-> outer port ModeRsp/PosArray
    delegate StPassCmprtMdHMIDisCmd.PwrMdChked <-> outer port ModeRsp/PwrMdChked
    delegate SRSModeState.SRSMode <-> outer port ModeRsp/SRSMode
  composition sw component type ModeStatCtrl
    5 x provide port:
      IsStBsy32Bit: nonqueued-sender-com-spec{data-element=IsStBsy32Bit/Val, init-value=0}, provided-interface=IsStBsy32Bit
      IsTargetPos32Bit: nonqueued-sender-com-spec{data-element=IsTargetPos32Bit/Val, init-value=0}, provided-interface=IsTargetPos32Bit
      MdXX_Rsp: provided-interface=MdXX_Rsp
        provided-com-specs:
          data-element=Md1_Rsp, init-value=0
          data-element=Md{10..19}_Rsp, init-value=0
          data-element=Md2_Rsp, init-value=0
          data-element=Md{20..29}_Rsp, init-value=0
          data-element=Md3_Rsp, init-value=0
          data-element=Md{30..32}_Rsp, init-value=0
          data-element=Md{4..9}_Rsp, init-value=0
      MdXX_SrcReqTp: provided-interface=MdXX_SrcReqTp
        provided-com-specs:
          data-element=Md1_SrcTp, init-value=0
          data-element=Md{10..19}_SrcTp, init-value=0
          data-element=Md2_SrcTp, init-value=0
          data-element=Md{20..29}_SrcTp, init-value=0
          data-element=Md3_SrcTp, init-value=0
          data-element=Md{30..32}_SrcTp, init-value=0
          data-element=Md{4..9}_SrcTp, init-value=0
      modestate32: nonqueued-sender-com-spec{data-element=modestate32/Val, init-value=0}, provided-interface=modestate32
    144 x require port:
      acsEntyMdReq: nonqueued-receiver-com-spec{data-element=MdReq/Val, filter=data-filter-type=ALWAYS, init-value=0}, required-interface=MdReq
      acsEntyMdSrcTp: nonqueued-receiver-com-spec{data-element=ModeSrcTp/Val, filter=data-filter-type=ALWAYS, init-value=0}, required-interface=ModeSrcTp
      acsExtMdReq: nonqueued-receiver-com-spec{data-element=MdReq/Val, filter=data-filter-type=ALWAYS, init-value=0}, required-interface=MdReq
      acsExtMdSrcTp: nonqueued-receiver-com-spec{data-element=ModeSrcTp/Val, filter=data-filter-type=ALWAYS, init-value=0}, required-interface=ModeSrcTp
      AllLugMdReq: nonqueued-receiver-com-spec{data-element=MdReq/Val, filter=data-filter-type=ALWAYS, init-value=0}, required-interface=MdReq
      AllLugSrcReqTp: nonqueued-receiver-com-spec{data-element=ModeSrcTp/Val, filter=data-filter-type=ALWAYS, init-value=0}, required-interface=ModeSrcTp
      AllVipMdReq: nonqueued-receiver-com-spec{data-element=MdReq/Val, filter=data-filter-type=ALWAYS, init-value=0}, required-interface=MdReq
      AllVipSrcReqTp: nonqueued-receiver-com-spec{data-element=ModeSrcTp/Val, filter=data-filter-type=ALWAYS, init-value=0}, required-interface=ModeSrcTp
      CommCond: nonqueued-receiver-com-spec{data-element=CommCond/Val, filter=data-filter-type=ALWAYS, init-value=0}, required-interface=CommCond
      CommExitCond: nonqueued-receiver-com-spec{data-element=CommExitCond/Val, filter=data-filter-type=ALWAYS, init-value=0}, required-interface=CommExitCond
      CommExitCondwithSpeed: nonqueued-receiver-com-spec{data-element=CommExitCondwithSpeed/Val, filter=data-filter-type=ALWAYS, init-value=0}, required-interface=CommExitCondwithSpeed
      IntimacyRtMdReq: nonqueued-receiver-com-spec{data-element=AnyModeAjust/Val, filter=data-filter-type=ALWAYS, init-value=0}, required-interface=AnyModeAjust
      IntimacyRtMdSrcTp: nonqueued-receiver-com-spec{data-element=ModeSrcTp/Val, filter=data-filter-type=ALWAYS, init-value=0}, required-interface=ModeSrcTp
      INTMMdReq: nonqueued-receiver-com-spec{data-element=MdReq/Val, filter=data-filter-type=ALWAYS, init-value=0}, required-interface=MdReq
      INTMSrcReqTp: nonqueued-receiver-com-spec{data-element=ModeSrcTp/Val, filter=data-filter-type=ALWAYS, init-value=0}, required-interface=ModeSrcTp
      isAcsMdEntryArrivedAtTargetPos: nonqueued-receiver-com-spec{data-element=IsTargetPos/Val, filter=data-filter-type=ALWAYS, init-value=0}, required-interface=IsTargetPos
      isAcsMdEntryDoneFailed: nonqueued-receiver-com-spec{data-element=DoneFailed/Val, filter=data-filter-type=ALWAYS, init-value=0}, required-interface=DoneFailed
      isAcsMdEntryDoneOK: nonqueued-receiver-com-spec{data-element=DoneOK/Val, filter=data-filter-type=ALWAYS, init-value=0}, required-interface=DoneOK
      isAcsMdExtArrivedAtTargetPos: nonqueued-receiver-com-spec{data-element=IsTargetPos/Val, filter=data-filter-type=ALWAYS, init-value=0}, required-interface=IsTargetPos
      isAcsMdExtDoneFailed: nonqueued-receiver-com-spec{data-element=DoneFailed/Val, filter=data-filter-type=ALWAYS, init-value=0}, required-interface=DoneFailed
      isAcsMdExtDoneOK: nonqueued-receiver-com-spec{data-element=DoneOK/Val, filter=data-filter-type=ALWAYS, init-value=0}, required-interface=DoneOK
      isINTMArrivedAtTargetPos: nonqueued-receiver-com-spec{data-element=IsTargetPos/Val, filter=data-filter-type=ALWAYS, init-value=0}, required-interface=IsTargetPos
      isINTMDoneFailed: nonqueued-receiver-com-spec{data-element=DoneFailed/Val, filter=data-filter-type=ALWAYS, init-value=0}, required-interface=DoneFailed
      isINTMDoneOK: nonqueued-receiver-com-spec{data-element=DoneOK/Val, filter=data-filter-type=ALWAYS, init-value=0}, required-interface=DoneOK
      isINTMRArrivedAtTargetPos: nonqueued-receiver-com-spec{data-element=IsTargetPos/Val, filter=data-filter-type=ALWAYS, init-value=0}, required-interface=IsTargetPos
      isINTMRDoneFailed: nonqueued-receiver-com-spec{data-element=DoneFailed/Val, filter=data-filter-type=ALWAYS, init-value=0}, required-interface=DoneFailed
      isINTMRDoneOK: nonqueued-receiver-com-spec{data-element=DoneOK/Val, filter=data-filter-type=ALWAYS, init-value=0}, required-interface=DoneOK
      isLfFamlyArrivedAtTargetPos: nonqueued-receiver-com-spec{data-element=IsTargetPos/Val, filter=data-filter-type=ALWAYS, init-value=0}, required-interface=IsTargetPos
      isLfFamlyDoneFailed: nonqueued-receiver-com-spec{data-element=DoneFailed/Val, filter=data-filter-type=ALWAYS, init-value=0}, required-interface=DoneFailed
      isLfFamlyDoneOK: nonqueued-receiver-com-spec{data-element=DoneOK/Val, filter=data-filter-type=ALWAYS, init-value=0}, required-interface=DoneOK
      isLfLugArrivedAtTargetPos: nonqueued-receiver-com-spec{data-element=IsTargetPos/Val, filter=data-filter-type=ALWAYS, init-value=0}, required-interface=IsTargetPos
      isLfLugDoneFailed: nonqueued-receiver-com-spec{data-element=DoneFailed/Val, filter=data-filter-type=ALWAYS, init-value=0}, required-interface=DoneFailed
      isLfLugDoneOK: nonqueued-receiver-com-spec{data-element=DoneOK/Val, filter=data-filter-type=ALWAYS, init-value=0}, required-interface=DoneOK
      isLfLyArrivedAtTargetPos: nonqueued-receiver-com-spec{data-element=IsTargetPos/Val, filter=data-filter-type=ALWAYS, init-value=0}, required-interface=IsTargetPos
      isLfLyDoneFailed: nonqueued-receiver-com-spec{data-element=DoneFailed/Val, filter=data-filter-type=ALWAYS, init-value=0}, required-interface=DoneFailed
      isLfLyDoneOK: nonqueued-receiver-com-spec{data-element=DoneOK/Val, filter=data-filter-type=ALWAYS, init-value=0}, required-interface=DoneOK
      isLfRecoveryArrivedAtTargetPos: nonqueued-receiver-com-spec{data-element=IsTargetPos/Val, filter=data-filter-type=ALWAYS, init-value=0}, required-interface=IsTargetPos
      isLfRecoveryDoneFailed: nonqueued-receiver-com-spec{data-element=DoneFailed/Val, filter=data-filter-type=ALWAYS, init-value=0}, required-interface=DoneFailed
      isLfRecoveryDoneOK: nonqueued-receiver-com-spec{data-element=DoneOK/Val, filter=data-filter-type=ALWAYS, init-value=0}, required-interface=DoneOK
      isLfVipArrivedAtTargetPos: nonqueued-receiver-com-spec{data-element=IsTargetPos/Val, filter=data-filter-type=ALWAYS, init-value=0}, required-interface=IsTargetPos
      isLfVipDoneFailed: nonqueued-receiver-com-spec{data-element=DoneFailed/Val, filter=data-filter-type=ALWAYS, init-value=0}, required-interface=DoneFailed
      isLfVipDoneOK: nonqueued-receiver-com-spec{data-element=DoneOK/Val, filter=data-filter-type=ALWAYS, init-value=0}, required-interface=DoneOK
      isLgrstCloseLArrivedAtTargetPos: nonqueued-receiver-com-spec{data-element=IsTargetPos/Val, filter=data-filter-type=ALWAYS, init-value=0}, required-interface=IsTargetPos
      isLgrstCloseLDoneFailed: nonqueued-receiver-com-spec{data-element=DoneFailed/Val, filter=data-filter-type=ALWAYS, init-value=0}, required-interface=DoneFailed
      isLgrstCloseLDoneOK: nonqueued-receiver-com-spec{data-element=DoneOK/Val, filter=data-filter-type=ALWAYS, init-value=0}, required-interface=DoneOK
      isLgrstCloseRArrivedAtTargetPos: nonqueued-receiver-com-spec{data-element=IsTargetPos/Val, filter=data-filter-type=ALWAYS, init-value=0}, required-interface=IsTargetPos
      isLgrstCloseRDoneFailed: nonqueued-receiver-com-spec{data-element=DoneFailed/Val, filter=data-filter-type=ALWAYS, init-value=0}, required-interface=DoneFailed
      isLgrstCloseRDoneOK: nonqueued-receiver-com-spec{data-element=DoneOK/Val, filter=data-filter-type=ALWAYS, init-value=0}, required-interface=DoneOK
      isLgrstOpenLArrivedAtTargetPos: nonqueued-receiver-com-spec{data-element=IsTargetPos/Val, filter=data-filter-type=ALWAYS, init-value=0}, required-interface=IsTargetPos
      isLgrstOpenLDoneFailed: nonqueued-receiver-com-spec{data-element=DoneFailed/Val, filter=data-filter-type=ALWAYS, init-value=0}, required-interface=DoneFailed
      isLgrstOpenLDoneOK: nonqueued-receiver-com-spec{data-element=DoneOK/Val, filter=data-filter-type=ALWAYS, init-value=0}, required-interface=DoneOK
      isLgrstOpenRArrivedAtTargetPos: nonqueued-receiver-com-spec{data-element=IsTargetPos/Val, filter=data-filter-type=ALWAYS, init-value=0}, required-interface=IsTargetPos
      isLgrstOpenRDoneFailed: nonqueued-receiver-com-spec{data-element=DoneFailed/Val, filter=data-filter-type=ALWAYS, init-value=0}, required-interface=DoneFailed
      isLgrstOpenRDoneOK: nonqueued-receiver-com-spec{data-element=DoneOK/Val, filter=data-filter-type=ALWAYS, init-value=0}, required-interface=DoneOK
      isRfFamlyDoneFailed: nonqueued-receiver-com-spec{data-element=DoneFailed/Val, filter=data-filter-type=ALWAYS, init-value=0}, required-interface=DoneFailed
      isRfFamlyDoneOK: nonqueued-receiver-com-spec{data-element=DoneOK/Val, filter=data-filter-type=ALWAYS, init-value=0}, required-interface=DoneOK
      isRtFamlyArrivedAtTargetPos: nonqueued-receiver-com-spec{data-element=IsTargetPos/Val, filter=data-filter-type=ALWAYS, init-value=0}, required-interface=IsTargetPos
      isRtLugArrivedAtTargetPos: nonqueued-receiver-com-spec{data-element=IsTargetPos/Val, filter=data-filter-type=ALWAYS, init-value=0}, required-interface=IsTargetPos
      isRtLugDoneFailed: nonqueued-receiver-com-spec{data-element=DoneFailed/Val, filter=data-filter-type=ALWAYS, init-value=0}, required-interface=DoneFailed
      isRtLugDoneOK: nonqueued-receiver-com-spec{data-element=DoneOK/Val, filter=data-filter-type=ALWAYS, init-value=0}, required-interface=DoneOK
      isRtLyArrivedAtTargetPos: nonqueued-receiver-com-spec{data-element=IsTargetPos/Val, filter=data-filter-type=ALWAYS, init-value=0}, required-interface=IsTargetPos
      isRtLyDoneFailed: nonqueued-receiver-com-spec{data-element=DoneFailed/Val, filter=data-filter-type=ALWAYS, init-value=0}, required-interface=DoneFailed
      isRtLyDoneOK: nonqueued-receiver-com-spec{data-element=DoneOK/Val, filter=data-filter-type=ALWAYS, init-value=0}, required-interface=DoneOK
      isRtRecoveryArrivedAtTargetPos: nonqueued-receiver-com-spec{data-element=IsTargetPos/Val, filter=data-filter-type=ALWAYS, init-value=0}, required-interface=IsTargetPos
      isRtRecoveryDoneFailed: nonqueued-receiver-com-spec{data-element=DoneFailed/Val, filter=data-filter-type=ALWAYS, init-value=0}, required-interface=DoneFailed
      isRtRecoveryDoneOK: nonqueued-receiver-com-spec{data-element=DoneOK/Val, filter=data-filter-type=ALWAYS, init-value=0}, required-interface=DoneOK
      isRtVipArrivedAtTargetPos: nonqueued-receiver-com-spec{data-element=IsTargetPos/Val, filter=data-filter-type=ALWAYS, init-value=0}, required-interface=IsTargetPos
      isRtVipDoneFailed: nonqueued-receiver-com-spec{data-element=DoneFailed/Val, filter=data-filter-type=ALWAYS, init-value=0}, required-interface=DoneFailed
      isRtVipDoneOK: nonqueued-receiver-com-spec{data-element=DoneOK/Val, filter=data-filter-type=ALWAYS, init-value=0}, required-interface=DoneOK
      LfFamlyReq: nonqueued-receiver-com-spec{data-element=MdReq/Val, filter=data-filter-type=ALWAYS, init-value=0}, required-interface=MdReq
      LfFamlySrcReqTp: nonqueued-receiver-com-spec{data-element=ModeSrcTp/Val, filter=data-filter-type=ALWAYS, init-value=0}, required-interface=ModeSrcTp
      LfLyMdReq: nonqueued-receiver-com-spec{data-element=MdReq/Val, filter=data-filter-type=ALWAYS, init-value=0}, required-interface=MdReq
      LfLySrcReqTp: nonqueued-receiver-com-spec{data-element=ModeSrcTp/Val, filter=data-filter-type=ALWAYS, init-value=0}, required-interface=ModeSrcTp
      LgrstCloseLtMdReq: nonqueued-receiver-com-spec{data-element=AnyModeAjust/Val, filter=data-filter-type=ALWAYS, init-value=0}, required-interface=AnyModeAjust
      LgrstCloseLtSrcReqTp: nonqueued-receiver-com-spec{data-element=ModeSrcTp/Val, filter=data-filter-type=ALWAYS, init-value=0}, required-interface=ModeSrcTp
      LgrstCloseRtMdReq: nonqueued-receiver-com-spec{data-element=AnyModeAjust/Val, filter=data-filter-type=ALWAYS, init-value=0}, required-interface=AnyModeAjust
      LgrstCloseRtSrcReqTp: nonqueued-receiver-com-spec{data-element=ModeSrcTp/Val, filter=data-filter-type=ALWAYS, init-value=0}, required-interface=ModeSrcTp
      LgrstOpenLtMdReq: nonqueued-receiver-com-spec{data-element=AnyModeAjust/Val, filter=data-filter-type=ALWAYS, init-value=0}, required-interface=AnyModeAjust
      LgrstOpenLtSrcReqTp: nonqueued-receiver-com-spec{data-element=ModeSrcTp/Val, filter=data-filter-type=ALWAYS, init-value=0}, required-interface=ModeSrcTp
      LgrstOpenRtMdReq: nonqueued-receiver-com-spec{data-element=AnyModeAjust/Val, filter=data-filter-type=ALWAYS, init-value=0}, required-interface=AnyModeAjust
      LgrstOpenRtSrcReqTp: nonqueued-receiver-com-spec{data-element=ModeSrcTp/Val, filter=data-filter-type=ALWAYS, init-value=0}, required-interface=ModeSrcTp
      LtLugMdReq: nonqueued-receiver-com-spec{data-element=MdReq/Val, filter=data-filter-type=ALWAYS, init-value=0}, required-interface=MdReq
      LtLugSrcReqTp: nonqueued-receiver-com-spec{data-element=ModeSrcTp/Val, filter=data-filter-type=ALWAYS, init-value=0}, required-interface=ModeSrcTp
      LtRcvyMdReq: nonqueued-receiver-com-spec{data-element=MdReq/Val, filter=data-filter-type=ALWAYS, init-value=0}, required-interface=MdReq
      LtRcvySrcReqTp: nonqueued-receiver-com-spec{data-element=ModeSrcTp/Val, filter=data-filter-type=ALWAYS, init-value=0}, required-interface=ModeSrcTp
      LtVipMdReq: nonqueued-receiver-com-spec{data-element=MdReq/Val, filter=data-filter-type=ALWAYS, init-value=0}, required-interface=MdReq
      LtVipSrcReqTp: nonqueued-receiver-com-spec{data-element=ModeSrcTp/Val, filter=data-filter-type=ALWAYS, init-value=0}, required-interface=ModeSrcTp
      LugMdLtAvl: nonqueued-receiver-com-spec{data-element=ModeAdjustAvailable/Val, filter=data-filter-type=ALWAYS, init-value=0}, required-interface=ModeAdjustAvailable
      LugMdRtAvl: nonqueued-receiver-com-spec{data-element=ModeAdjustAvailable/Val, filter=data-filter-type=ALWAYS, init-value=0}, required-interface=ModeAdjustAvailable
      R3LMdSeatOccupied: nonqueued-receiver-com-spec{data-element=MdSeatOccupied/Val, filter=data-filter-type=ALWAYS, init-value=0}, required-interface=MdSeatOccupied
      R3RMdSeatOccupied: nonqueued-receiver-com-spec{data-element=MdSeatOccupied/Val, filter=data-filter-type=ALWAYS, init-value=0}, required-interface=MdSeatOccupied
      RtFamlyMdReq: nonqueued-receiver-com-spec{data-element=MdReq/Val, filter=data-filter-type=ALWAYS, init-value=0}, required-interface=MdReq
      RtFamlySrcReqTp: nonqueued-receiver-com-spec{data-element=ModeSrcTp/Val, filter=data-filter-type=ALWAYS, init-value=0}, required-interface=ModeSrcTp
      RtLugMdReq: nonqueued-receiver-com-spec{data-element=MdReq/Val, filter=data-filter-type=ALWAYS, init-value=0}, required-interface=MdReq
      RtLugSrcReqTp: nonqueued-receiver-com-spec{data-element=ModeSrcTp/Val, filter=data-filter-type=ALWAYS, init-value=0}, required-interface=ModeSrcTp
      RtLyMdReq: nonqueued-receiver-com-spec{data-element=MdReq/Val, filter=data-filter-type=ALWAYS, init-value=0}, required-interface=MdReq
      RtLySrcReqTp: nonqueued-receiver-com-spec{data-element=ModeSrcTp/Val, filter=data-filter-type=ALWAYS, init-value=0}, required-interface=ModeSrcTp
      RtRcvyMdReq: nonqueued-receiver-com-spec{data-element=MdReq/Val, filter=data-filter-type=ALWAYS, init-value=0}, required-interface=MdReq
      RtRcvySrcReqTp: nonqueued-receiver-com-spec{data-element=ModeSrcTp/Val, filter=data-filter-type=ALWAYS, init-value=0}, required-interface=ModeSrcTp
      RtVipMdReq: nonqueued-receiver-com-spec{data-element=MdReq/Val, filter=data-filter-type=ALWAYS, init-value=0}, required-interface=MdReq
      RtVipSrcReqTp: nonqueued-receiver-com-spec{data-element=ModeSrcTp/Val, filter=data-filter-type=ALWAYS, init-value=0}, required-interface=ModeSrcTp
      SoftIntAcsEnty: nonqueued-receiver-com-spec{data-element=MdReq/Val, filter=data-filter-type=ALWAYS, init-value=0}, required-interface=MdReq
      SoftIntAcsExt: nonqueued-receiver-com-spec{data-element=MdReq/Val, filter=data-filter-type=ALWAYS, init-value=0}, required-interface=MdReq
      SoftIntAllLug: nonqueued-receiver-com-spec{data-element=MdReq/Val, filter=data-filter-type=ALWAYS, init-value=0}, required-interface=MdReq
      SoftIntAllVip: nonqueued-receiver-com-spec{data-element=MdReq/Val, filter=data-filter-type=ALWAYS, init-value=0}, required-interface=MdReq
      SoftIntIntimacyRt: nonqueued-receiver-com-spec{data-element=IntEnable/Val, filter=data-filter-type=ALWAYS, init-value=0}, required-interface=IntEnable
      SoftIntINTM: nonqueued-receiver-com-spec{data-element=MdReq/Val, filter=data-filter-type=ALWAYS, init-value=0}, required-interface=MdReq
      SoftIntLfFamly: nonqueued-receiver-com-spec{data-element=MdReq/Val, filter=data-filter-type=ALWAYS, init-value=0}, required-interface=MdReq
      SoftIntLfLug: nonqueued-receiver-com-spec{data-element=MdReq/Val, filter=data-filter-type=ALWAYS, init-value=0}, required-interface=MdReq
      SoftIntLfLy: nonqueued-receiver-com-spec{data-element=MdReq/Val, filter=data-filter-type=ALWAYS, init-value=0}, required-interface=MdReq
      SoftIntLfRcvy: nonqueued-receiver-com-spec{data-element=MdReq/Val, filter=data-filter-type=ALWAYS, init-value=0}, required-interface=MdReq
      SoftIntLfVip: nonqueued-receiver-com-spec{data-element=MdReq/Val, filter=data-filter-type=ALWAYS, init-value=0}, required-interface=MdReq
      SoftIntLgrstCloseLt: nonqueued-receiver-com-spec{data-element=IntEnable/Val, filter=data-filter-type=ALWAYS, init-value=0}, required-interface=IntEnable
      SoftIntLgrstCloseRt: nonqueued-receiver-com-spec{data-element=IntEnable/Val, filter=data-filter-type=ALWAYS, init-value=0}, required-interface=IntEnable
      SoftIntLgrstOpenLt: nonqueued-receiver-com-spec{data-element=IntEnable/Val, filter=data-filter-type=ALWAYS, init-value=0}, required-interface=IntEnable
      SoftIntLgrstOpenRt: nonqueued-receiver-com-spec{data-element=IntEnable/Val, filter=data-filter-type=ALWAYS, init-value=0}, required-interface=IntEnable
      SoftIntRtFamly: nonqueued-receiver-com-spec{data-element=MdReq/Val, filter=data-filter-type=ALWAYS, init-value=0}, required-interface=MdReq
      SoftIntRtLug: nonqueued-receiver-com-spec{data-element=MdReq/Val, filter=data-filter-type=ALWAYS, init-value=0}, required-interface=MdReq
      SoftIntRtLy: nonqueued-receiver-com-spec{data-element=MdReq/Val, filter=data-filter-type=ALWAYS, init-value=0}, required-interface=MdReq
      SoftIntRtRcvy: nonqueued-receiver-com-spec{data-element=MdReq/Val, filter=data-filter-type=ALWAYS, init-value=0}, required-interface=MdReq
      SoftIntRtVip: nonqueued-receiver-com-spec{data-element=MdReq/Val, filter=data-filter-type=ALWAYS, init-value=0}, required-interface=MdReq
      StNumFlg: required-interface=StNumFlg
        required-com-specs:
          data-element=Is4s, filter=data-filter-type=ALWAYS, init-value=0
          data-element=Is6s, filter=data-filter-type=ALWAYS, init-value=0
          data-element=Is6s7s, filter=data-filter-type=ALWAYS, init-value=0
          data-element=Is7s, filter=data-filter-type=ALWAYS, init-value=0
      SwIntAcsEnty: nonqueued-receiver-com-spec{data-element=MdReq/Val, filter=data-filter-type=ALWAYS, init-value=0}, required-interface=MdReq
      SwIntAcsExt: nonqueued-receiver-com-spec{data-element=MdReq/Val, filter=data-filter-type=ALWAYS, init-value=0}, required-interface=MdReq
      SwIntAllLug: nonqueued-receiver-com-spec{data-element=MdReq/Val, filter=data-filter-type=ALWAYS, init-value=0}, required-interface=MdReq
      SwIntAllVip: nonqueued-receiver-com-spec{data-element=IntEnable/Val, filter=data-filter-type=ALWAYS, init-value=0}, required-interface=IntEnable
      SwIntIntimacyRt: nonqueued-receiver-com-spec{data-element=IntEnable/Val, filter=data-filter-type=ALWAYS, init-value=0}, required-interface=IntEnable
      SwIntINTM: nonqueued-receiver-com-spec{data-element=MdReq/Val, filter=data-filter-type=ALWAYS, init-value=0}, required-interface=MdReq
      SwIntLfFamly: nonqueued-receiver-com-spec{data-element=MdReq/Val, filter=data-filter-type=ALWAYS, init-value=0}, required-interface=MdReq
      SwIntLfLug: nonqueued-receiver-com-spec{data-element=MdReq/Val, filter=data-filter-type=ALWAYS, init-value=0}, required-interface=MdReq
      SwIntLfLy: nonqueued-receiver-com-spec{data-element=MdReq/Val, filter=data-filter-type=ALWAYS, init-value=0}, required-interface=MdReq
      SwIntLfRcvy: nonqueued-receiver-com-spec{data-element=MdReq/Val, filter=data-filter-type=ALWAYS, init-value=0}, required-interface=MdReq
      SwIntLfVip: nonqueued-receiver-com-spec{data-element=MdReq/Val, filter=data-filter-type=ALWAYS, init-value=0}, required-interface=MdReq
      SwIntLgrstCloseLt: nonqueued-receiver-com-spec{data-element=IntEnable/Val, filter=data-filter-type=ALWAYS, init-value=0}, required-interface=IntEnable
      SwIntLgrstCloseRt: nonqueued-receiver-com-spec{data-element=IntEnable/Val, filter=data-filter-type=ALWAYS, init-value=0}, required-interface=IntEnable
      SwIntLgrstOpenLt: nonqueued-receiver-com-spec{data-element=IntEnable/Val, filter=data-filter-type=ALWAYS, init-value=0}, required-interface=IntEnable
      SwIntLgrstOpenRt: nonqueued-receiver-com-spec{data-element=IntEnable/Val, filter=data-filter-type=ALWAYS, init-value=0}, required-interface=IntEnable
      SwIntRtFamly: nonqueued-receiver-com-spec{data-element=MdReq/Val, filter=data-filter-type=ALWAYS, init-value=0}, required-interface=MdReq
      SwIntRtLug: nonqueued-receiver-com-spec{data-element=MdReq/Val, filter=data-filter-type=ALWAYS, init-value=0}, required-interface=MdReq
      SwIntRtLy: nonqueued-receiver-com-spec{data-element=MdReq/Val, filter=data-filter-type=ALWAYS, init-value=0}, required-interface=MdReq
      SwIntRtRcvy: nonqueued-receiver-com-spec{data-element=MdReq/Val, filter=data-filter-type=ALWAYS, init-value=0}, required-interface=MdReq
      SwIntRtVip: nonqueued-receiver-com-spec{data-element=MdReq/Val, filter=data-filter-type=ALWAYS, init-value=0}, required-interface=MdReq
      VipMdLtAvl: nonqueued-receiver-com-spec{data-element=ModeAdjustAvailable/Val, filter=data-filter-type=ALWAYS, init-value=0}, required-interface=ModeAdjustAvailable
      VipMdRtAvl: nonqueued-receiver-com-spec{data-element=ModeAdjustAvailable/Val, filter=data-filter-type=ALWAYS, init-value=0}, required-interface=ModeAdjustAvailable
    5 x component:
      MdEnCtrlAndBsyChk: type=MdEnCtrlAndBsyChk
      MdXX_isTrgtPos: type=MdXX_isTrgtPos
      MdXX_QuitChk: type=MdXX_QuitChk
      MdXX_SrcTp: type=MdXX_SrcTp
      StateOnOffChk: type=StateOnOffChk
    connect MdEnCtrlAndBsyChk.modestate32 -> StateOnOffChk.modestate32
    connect MdXX_QuitChk.MdXX_Quit32bit -> MdEnCtrlAndBsyChk.MdXX_Quit32bit
    connect StateOnOffChk.ModeStateOn -> MdEnCtrlAndBsyChk.ModeStateOn
    connect StateOnOffChk.ModeStateOn -> MdXX_QuitChk.ModeStateOn
    connect StateOnOffChk.ModeStateOn -> MdXX_SrcTp.ModeStateOn
    delegate MdEnCtrlAndBsyChk.acsEntyMdReq <-> outer port ModeStatCtrl/acsEntyMdReq
    delegate MdXX_SrcTp.acsEntyMdSrcTp <-> outer port ModeStatCtrl/acsEntyMdSrcTp
    delegate MdEnCtrlAndBsyChk.acsExtMdReq <-> outer port ModeStatCtrl/acsExtMdReq
    delegate MdXX_SrcTp.acsExtMdSrcTp <-> outer port ModeStatCtrl/acsExtMdSrcTp
    delegate MdEnCtrlAndBsyChk.AllLugMdReq <-> outer port ModeStatCtrl/AllLugMdReq
    delegate MdXX_SrcTp.AllLugSrcReqTp <-> outer port ModeStatCtrl/AllLugSrcReqTp
    delegate MdEnCtrlAndBsyChk.AllVipMdReq <-> outer port ModeStatCtrl/AllVipMdReq
    delegate MdXX_SrcTp.AllVipSrcReqTp <-> outer port ModeStatCtrl/AllVipSrcReqTp
    delegate StateOnOffChk.CommCond <-> outer port ModeStatCtrl/CommCond
    delegate MdXX_QuitChk.CommExitCond <-> outer port ModeStatCtrl/CommExitCond
    delegate MdXX_QuitChk.CommExitCondwithSpeed <-> outer port ModeStatCtrl/CommExitCondwithSpeed
    delegate MdEnCtrlAndBsyChk.IntimacyRtMdReq <-> outer port ModeStatCtrl/IntimacyRtMdReq
    delegate MdXX_SrcTp.IntimacyRtMdSrcTp <-> outer port ModeStatCtrl/IntimacyRtMdSrcTp
    delegate MdEnCtrlAndBsyChk.INTMMdReq <-> outer port ModeStatCtrl/INTMMdReq
    delegate MdXX_SrcTp.INTMSrcReqTp <-> outer port ModeStatCtrl/INTMSrcReqTp
    delegate MdXX_isTrgtPos.isAcsMdEntryArrivedAtTargetPos <-> outer port ModeStatCtrl/isAcsMdEntryArrivedAtTargetPos
    delegate MdXX_QuitChk.isAcsMdEntryDoneFailed <-> outer port ModeStatCtrl/isAcsMdEntryDoneFailed
    delegate MdXX_QuitChk.isAcsMdEntryDoneOK <-> outer port ModeStatCtrl/isAcsMdEntryDoneOK
    delegate MdXX_isTrgtPos.isAcsMdExtArrivedAtTargetPos <-> outer port ModeStatCtrl/isAcsMdExtArrivedAtTargetPos
    delegate MdXX_QuitChk.isAcsMdExtDoneFailed <-> outer port ModeStatCtrl/isAcsMdExtDoneFailed
    delegate MdXX_QuitChk.isAcsMdExtDoneOK <-> outer port ModeStatCtrl/isAcsMdExtDoneOK
    delegate MdXX_isTrgtPos.isINTMArrivedAtTargetPos <-> outer port ModeStatCtrl/isINTMArrivedAtTargetPos
    delegate MdXX_QuitChk.isINTMDoneFailed <-> outer port ModeStatCtrl/isINTMDoneFailed
    delegate MdXX_QuitChk.isINTMDoneOK <-> outer port ModeStatCtrl/isINTMDoneOK
    delegate MdXX_isTrgtPos.isINTMRArrivedAtTargetPos <-> outer port ModeStatCtrl/isINTMRArrivedAtTargetPos
    delegate MdXX_QuitChk.isINTMRDoneFailed <-> outer port ModeStatCtrl/isINTMRDoneFailed
    delegate MdXX_QuitChk.isINTMRDoneOK <-> outer port ModeStatCtrl/isINTMRDoneOK
    delegate MdXX_isTrgtPos.isLfFamlyArrivedAtTargetPos <-> outer port ModeStatCtrl/isLfFamlyArrivedAtTargetPos
    delegate MdXX_QuitChk.isLfFamlyDoneFailed <-> outer port ModeStatCtrl/isLfFamlyDoneFailed
    delegate MdXX_QuitChk.isLfFamlyDoneOK <-> outer port ModeStatCtrl/isLfFamlyDoneOK
    delegate MdXX_isTrgtPos.isLfLugArrivedAtTargetPos <-> outer port ModeStatCtrl/isLfLugArrivedAtTargetPos
    delegate MdXX_QuitChk.isLfLugDoneFailed <-> outer port ModeStatCtrl/isLfLugDoneFailed
    delegate MdXX_QuitChk.isLfLugDoneOK <-> outer port ModeStatCtrl/isLfLugDoneOK
    delegate MdXX_isTrgtPos.isLfLyArrivedAtTargetPos <-> outer port ModeStatCtrl/isLfLyArrivedAtTargetPos
    delegate MdXX_QuitChk.isLfLyDoneFailed <-> outer port ModeStatCtrl/isLfLyDoneFailed
    delegate MdXX_QuitChk.isLfLyDoneOK <-> outer port ModeStatCtrl/isLfLyDoneOK
    delegate MdXX_isTrgtPos.isLfRecoveryArrivedAtTargetPos <-> outer port ModeStatCtrl/isLfRecoveryArrivedAtTargetPos
    delegate MdXX_QuitChk.isLfRecoveryDoneFailed <-> outer port ModeStatCtrl/isLfRecoveryDoneFailed
    delegate MdXX_QuitChk.isLfRecoveryDoneOK <-> outer port ModeStatCtrl/isLfRecoveryDoneOK
    delegate MdXX_isTrgtPos.isLfVipArrivedAtTargetPos <-> outer port ModeStatCtrl/isLfVipArrivedAtTargetPos
    delegate MdXX_QuitChk.isLfVipDoneFailed <-> outer port ModeStatCtrl/isLfVipDoneFailed
    delegate MdXX_QuitChk.isLfVipDoneOK <-> outer port ModeStatCtrl/isLfVipDoneOK
    delegate MdXX_isTrgtPos.isLgrstCloseLArrivedAtTargetPos <-> outer port ModeStatCtrl/isLgrstCloseLArrivedAtTargetPos
    delegate MdXX_QuitChk.isLgrstCloseLDoneFailed <-> outer port ModeStatCtrl/isLgrstCloseLDoneFailed
    delegate MdXX_QuitChk.isLgrstCloseLDoneOK <-> outer port ModeStatCtrl/isLgrstCloseLDoneOK
    delegate MdXX_isTrgtPos.isLgrstCloseRArrivedAtTargetPos <-> outer port ModeStatCtrl/isLgrstCloseRArrivedAtTargetPos
    delegate MdXX_QuitChk.isLgrstCloseRDoneFailed <-> outer port ModeStatCtrl/isLgrstCloseRDoneFailed
    delegate MdXX_QuitChk.isLgrstCloseRDoneOK <-> outer port ModeStatCtrl/isLgrstCloseRDoneOK
    delegate MdXX_isTrgtPos.isLgrstOpenLArrivedAtTargetPos <-> outer port ModeStatCtrl/isLgrstOpenLArrivedAtTargetPos
    delegate MdXX_QuitChk.isLgrstOpenLDoneFailed <-> outer port ModeStatCtrl/isLgrstOpenLDoneFailed
    delegate MdXX_QuitChk.isLgrstOpenLDoneOK <-> outer port ModeStatCtrl/isLgrstOpenLDoneOK
    delegate MdXX_isTrgtPos.isLgrstOpenRArrivedAtTargetPos <-> outer port ModeStatCtrl/isLgrstOpenRArrivedAtTargetPos
    delegate MdXX_QuitChk.isLgrstOpenRDoneFailed <-> outer port ModeStatCtrl/isLgrstOpenRDoneFailed
    delegate MdXX_QuitChk.isLgrstOpenRDoneOK <-> outer port ModeStatCtrl/isLgrstOpenRDoneOK
    delegate MdXX_QuitChk.isRfFamlyDoneFailed <-> outer port ModeStatCtrl/isRfFamlyDoneFailed
    delegate MdXX_QuitChk.isRfFamlyDoneOK <-> outer port ModeStatCtrl/isRfFamlyDoneOK
    delegate MdXX_isTrgtPos.isRtFamlyArrivedAtTargetPos <-> outer port ModeStatCtrl/isRtFamlyArrivedAtTargetPos
    delegate MdXX_isTrgtPos.isRtLugArrivedAtTargetPos <-> outer port ModeStatCtrl/isRtLugArrivedAtTargetPos
    delegate MdXX_QuitChk.isRtLugDoneFailed <-> outer port ModeStatCtrl/isRtLugDoneFailed
    delegate MdXX_QuitChk.isRtLugDoneOK <-> outer port ModeStatCtrl/isRtLugDoneOK
    delegate MdXX_isTrgtPos.isRtLyArrivedAtTargetPos <-> outer port ModeStatCtrl/isRtLyArrivedAtTargetPos
    delegate MdXX_QuitChk.isRtLyDoneFailed <-> outer port ModeStatCtrl/isRtLyDoneFailed
    delegate MdXX_QuitChk.isRtLyDoneOK <-> outer port ModeStatCtrl/isRtLyDoneOK
    delegate MdXX_isTrgtPos.isRtRecoveryArrivedAtTargetPos <-> outer port ModeStatCtrl/isRtRecoveryArrivedAtTargetPos
    delegate MdXX_QuitChk.isRtRecoveryDoneFailed <-> outer port ModeStatCtrl/isRtRecoveryDoneFailed
    delegate MdXX_QuitChk.isRtRecoveryDoneOK <-> outer port ModeStatCtrl/isRtRecoveryDoneOK
    delegate MdXX_isTrgtPos.isRtVipArrivedAtTargetPos <-> outer port ModeStatCtrl/isRtVipArrivedAtTargetPos
    delegate MdXX_QuitChk.isRtVipDoneFailed <-> outer port ModeStatCtrl/isRtVipDoneFailed
    delegate MdXX_QuitChk.isRtVipDoneOK <-> outer port ModeStatCtrl/isRtVipDoneOK
    delegate MdEnCtrlAndBsyChk.IsStBsy32Bit <-> outer port ModeStatCtrl/IsStBsy32Bit
    delegate MdXX_isTrgtPos.IsTargetPos32Bit <-> outer port ModeStatCtrl/IsTargetPos32Bit
    delegate MdEnCtrlAndBsyChk.LfFamlyReq <-> outer port ModeStatCtrl/LfFamlyReq
    delegate MdXX_SrcTp.LfFamlySrcReqTp <-> outer port ModeStatCtrl/LfFamlySrcReqTp
    delegate MdEnCtrlAndBsyChk.LfLyMdReq <-> outer port ModeStatCtrl/LfLyMdReq
    delegate MdXX_SrcTp.LfLySrcReqTp <-> outer port ModeStatCtrl/LfLySrcReqTp
    delegate MdEnCtrlAndBsyChk.LgrstCloseLtMdReq <-> outer port ModeStatCtrl/LgrstCloseLtMdReq
    delegate MdXX_SrcTp.LgrstCloseLtSrcReqTp <-> outer port ModeStatCtrl/LgrstCloseLtSrcReqTp
    delegate MdEnCtrlAndBsyChk.LgrstCloseRtMdReq <-> outer port ModeStatCtrl/LgrstCloseRtMdReq
    delegate MdXX_SrcTp.LgrstCloseRtSrcReqTp <-> outer port ModeStatCtrl/LgrstCloseRtSrcReqTp
    delegate MdEnCtrlAndBsyChk.LgrstOpenLtMdReq <-> outer port ModeStatCtrl/LgrstOpenLtMdReq
    delegate MdXX_SrcTp.LgrstOpenLtSrcReqTp <-> outer port ModeStatCtrl/LgrstOpenLtSrcReqTp
    delegate MdEnCtrlAndBsyChk.LgrstOpenRtMdReq <-> outer port ModeStatCtrl/LgrstOpenRtMdReq
    delegate MdXX_SrcTp.LgrstOpenRtSrcReqTp <-> outer port ModeStatCtrl/LgrstOpenRtSrcReqTp
    delegate MdEnCtrlAndBsyChk.LtLugMdReq <-> outer port ModeStatCtrl/LtLugMdReq
    delegate MdXX_SrcTp.LtLugSrcReqTp <-> outer port ModeStatCtrl/LtLugSrcReqTp
    delegate MdEnCtrlAndBsyChk.LtRcvyMdReq <-> outer port ModeStatCtrl/LtRcvyMdReq
    delegate MdXX_SrcTp.LtRcvySrcReqTp <-> outer port ModeStatCtrl/LtRcvySrcReqTp
    delegate MdEnCtrlAndBsyChk.LtVipMdReq <-> outer port ModeStatCtrl/LtVipMdReq
    delegate MdXX_SrcTp.LtVipSrcReqTp <-> outer port ModeStatCtrl/LtVipSrcReqTp
    delegate MdEnCtrlAndBsyChk.LugMdLtAvl <-> outer port ModeStatCtrl/LugMdLtAvl
    delegate MdEnCtrlAndBsyChk.LugMdRtAvl <-> outer port ModeStatCtrl/LugMdRtAvl
    delegate MdXX_QuitChk.MdXX_Rsp <-> outer port ModeStatCtrl/MdXX_Rsp
    delegate MdXX_SrcTp.MdXX_SrcReqTp <-> outer port ModeStatCtrl/MdXX_SrcReqTp
    delegate MdEnCtrlAndBsyChk.modestate32 <-> outer port ModeStatCtrl/modestate32
    delegate MdXX_QuitChk.R3LMdSeatOccupied <-> outer port ModeStatCtrl/R3LMdSeatOccupied
    delegate MdXX_QuitChk.R3RMdSeatOccupied <-> outer port ModeStatCtrl/R3RMdSeatOccupied
    delegate MdEnCtrlAndBsyChk.RtFamlyMdReq <-> outer port ModeStatCtrl/RtFamlyMdReq
    delegate MdXX_SrcTp.RtFamlySrcReqTp <-> outer port ModeStatCtrl/RtFamlySrcReqTp
    delegate MdEnCtrlAndBsyChk.RtLugMdReq <-> outer port ModeStatCtrl/RtLugMdReq
    delegate MdXX_SrcTp.RtLugSrcReqTp <-> outer port ModeStatCtrl/RtLugSrcReqTp
    delegate MdEnCtrlAndBsyChk.RtLyMdReq <-> outer port ModeStatCtrl/RtLyMdReq
    delegate MdXX_SrcTp.RtLySrcReqTp <-> outer port ModeStatCtrl/RtLySrcReqTp
    delegate MdEnCtrlAndBsyChk.RtRcvyMdReq <-> outer port ModeStatCtrl/RtRcvyMdReq
    delegate MdXX_SrcTp.RtRcvySrcReqTp <-> outer port ModeStatCtrl/RtRcvySrcReqTp
    delegate MdEnCtrlAndBsyChk.RtVipMdReq <-> outer port ModeStatCtrl/RtVipMdReq
    delegate MdXX_SrcTp.RtVipSrcReqTp <-> outer port ModeStatCtrl/RtVipSrcReqTp
    delegate MdXX_QuitChk.SoftIntAcsEnty <-> outer port ModeStatCtrl/SoftIntAcsEnty
    delegate MdXX_QuitChk.SoftIntAcsExt <-> outer port ModeStatCtrl/SoftIntAcsExt
    delegate MdXX_QuitChk.SoftIntAllLug <-> outer port ModeStatCtrl/SoftIntAllLug
    delegate MdXX_QuitChk.SoftIntAllVip <-> outer port ModeStatCtrl/SoftIntAllVip
    delegate MdXX_QuitChk.SoftIntIntimacyRt <-> outer port ModeStatCtrl/SoftIntIntimacyRt
    delegate MdXX_QuitChk.SoftIntINTM <-> outer port ModeStatCtrl/SoftIntINTM
    delegate MdXX_QuitChk.SoftIntLfFamly <-> outer port ModeStatCtrl/SoftIntLfFamly
    delegate MdXX_QuitChk.SoftIntLfLug <-> outer port ModeStatCtrl/SoftIntLfLug
    delegate MdXX_QuitChk.SoftIntLfLy <-> outer port ModeStatCtrl/SoftIntLfLy
    delegate MdXX_QuitChk.SoftIntLfRcvy <-> outer port ModeStatCtrl/SoftIntLfRcvy
    delegate MdXX_QuitChk.SoftIntLfVip <-> outer port ModeStatCtrl/SoftIntLfVip
    delegate MdXX_QuitChk.SoftIntLgrstCloseLt <-> outer port ModeStatCtrl/SoftIntLgrstCloseLt
    delegate MdXX_QuitChk.SoftIntLgrstCloseRt <-> outer port ModeStatCtrl/SoftIntLgrstCloseRt
    delegate MdXX_QuitChk.SoftIntLgrstOpenLt <-> outer port ModeStatCtrl/SoftIntLgrstOpenLt
    delegate MdXX_QuitChk.SoftIntLgrstOpenRt <-> outer port ModeStatCtrl/SoftIntLgrstOpenRt
    delegate MdXX_QuitChk.SoftIntRtFamly <-> outer port ModeStatCtrl/SoftIntRtFamly
    delegate MdXX_QuitChk.SoftIntRtLug <-> outer port ModeStatCtrl/SoftIntRtLug
    delegate MdXX_QuitChk.SoftIntRtLy <-> outer port ModeStatCtrl/SoftIntRtLy
    delegate MdXX_QuitChk.SoftIntRtRcvy <-> outer port ModeStatCtrl/SoftIntRtRcvy
    delegate MdXX_QuitChk.SoftIntRtVip <-> outer port ModeStatCtrl/SoftIntRtVip
    delegate MdEnCtrlAndBsyChk.StNumFlg <-> outer port ModeStatCtrl/StNumFlg
    delegate MdXX_QuitChk.StNumFlg <-> outer port ModeStatCtrl/StNumFlg
    delegate MdXX_QuitChk.SwIntAcsEnty <-> outer port ModeStatCtrl/SwIntAcsEnty
    delegate MdXX_QuitChk.SwIntAcsExt <-> outer port ModeStatCtrl/SwIntAcsExt
    delegate MdXX_QuitChk.SwIntAllLug <-> outer port ModeStatCtrl/SwIntAllLug
    delegate MdXX_QuitChk.SwIntAllVip <-> outer port ModeStatCtrl/SwIntAllVip
    delegate MdXX_QuitChk.SwIntIntimacyRt <-> outer port ModeStatCtrl/SwIntIntimacyRt
    delegate MdXX_QuitChk.SwIntINTM <-> outer port ModeStatCtrl/SwIntINTM
    delegate MdXX_QuitChk.SwIntLfFamly <-> outer port ModeStatCtrl/SwIntLfFamly
    delegate MdXX_QuitChk.SwIntLfLug <-> outer port ModeStatCtrl/SwIntLfLug
    delegate MdXX_QuitChk.SwIntLfLy <-> outer port ModeStatCtrl/SwIntLfLy
    delegate MdXX_QuitChk.SwIntLfRcvy <-> outer port ModeStatCtrl/SwIntLfRcvy
    delegate MdXX_QuitChk.SwIntLfVip <-> outer port ModeStatCtrl/SwIntLfVip
    delegate MdXX_QuitChk.SwIntLgrstCloseLt <-> outer port ModeStatCtrl/SwIntLgrstCloseLt
    delegate MdXX_QuitChk.SwIntLgrstCloseRt <-> outer port ModeStatCtrl/SwIntLgrstCloseRt
    delegate MdXX_QuitChk.SwIntLgrstOpenLt <-> outer port ModeStatCtrl/SwIntLgrstOpenLt
    delegate MdXX_QuitChk.SwIntLgrstOpenRt <-> outer port ModeStatCtrl/SwIntLgrstOpenRt
    delegate MdXX_QuitChk.SwIntRtFamly <-> outer port ModeStatCtrl/SwIntRtFamly
    delegate MdXX_QuitChk.SwIntRtLug <-> outer port ModeStatCtrl/SwIntRtLug
    delegate MdXX_QuitChk.SwIntRtLy <-> outer port ModeStatCtrl/SwIntRtLy
    delegate MdXX_QuitChk.SwIntRtRcvy <-> outer port ModeStatCtrl/SwIntRtRcvy
    delegate MdXX_QuitChk.SwIntRtVip <-> outer port ModeStatCtrl/SwIntRtVip
    delegate MdEnCtrlAndBsyChk.VipMdLtAvl <-> outer port ModeStatCtrl/VipMdLtAvl
    delegate MdEnCtrlAndBsyChk.VipMdRtAvl <-> outer port ModeStatCtrl/VipMdRtAvl
  13 x swc implementation:
    CHM2Ctrl_Implementation: behavior=CHM2Ctrl_InternalBehavior
      code-descriptors:
        code Default: artifact-descriptors=autosar-engineering-object={short-label=Default, category=SWSRC}
    MdEnCtrlAndBsyChk_Implementation: behavior=MdEnCtrlAndBsyChk_InternalBehavior
      code-descriptors:
        code Default: artifact-descriptors=autosar-engineering-object={short-label=Default, category=SWSRC}
    MdXX_isTrgtPos_Implementation: behavior=MdXX_isTrgtPos_InternalBehavior
      code-descriptors:
        code Default: artifact-descriptors=autosar-engineering-object={short-label=Default, category=SWSRC}
    MdXX_QuitChk_Implementation: behavior=MdXX_QuitChk_InternalBehavior
      code-descriptors:
        code Default: artifact-descriptors=autosar-engineering-object={short-label=Default, category=SWSRC}
    MdXX_Rsp_Implementation: behavior=MdXX_Rsp_InternalBehavior
      code-descriptors:
        code Default: artifact-descriptors=autosar-engineering-object={short-label=Default, category=SWSRC}
    MdXX_RspToNetWork_Implementation: behavior=MdXX_RspToNetWork_InternalBehavior
      code-descriptors:
        code Default: artifact-descriptors=autosar-engineering-object={short-label=Default, category=SWSRC}
    MdXX_SrcTp_Implementation: behavior=MdXX_SrcTp_InternalBehavior
      code-descriptors:
        code Default: artifact-descriptors=autosar-engineering-object={short-label=Default, category=SWSRC}
    MdXX_Status_Implementation: behavior=MdXX_Status_InternalBehavior
      code-descriptors:
        code Default: artifact-descriptors=autosar-engineering-object={short-label=Default, category=SWSRC}
    MdXX_StatusToNetWork_Implementation: behavior=MdXX_StatusToNetWork_InternalBehavior
      code-descriptors:
        code Default: artifact-descriptors=autosar-engineering-object={short-label=Default, category=SWSRC}
    SRSModeState_Implementation: behavior=SRSModeState_InternalBehavior
      code-descriptors:
        code Default: artifact-descriptors=autosar-engineering-object={short-label=Default, category=SWSRC}
    StateOnOffChk_Implementation: behavior=StateOnOffChk_InternalBehavior
      code-descriptors:
        code Default: artifact-descriptors=autosar-engineering-object={short-label=Default, category=SWSRC}
    StNumChk_Implementation: behavior=StNumChk_InternalBehavior
      code-descriptors:
        code Default: artifact-descriptors=autosar-engineering-object={short-label=Default, category=SWSRC}
    StPassCmprtMdHMIDisCmd_Implementation: behavior=StPassCmprtMdHMIDisCmd_InternalBehavior
      code-descriptors:
        code Default: artifact-descriptors=autosar-engineering-object={short-label=Default, category=SWSRC}
package /PATAC/MSM/DataTypes/ImplementationDataTypes
  impl type IfVeSMSeStNumConfig: category=VALUE, base-type=UInt8, sw-calibration-access=READ-ONLY, compu {0=SeatNum4Config, 1=SeatNum6Config, 2=SeatNum7Config, 3=SeatNum4PConfig}, type-emitter=RTE
  impl type IntEnable: category=VALUE, base-type=Boolean, sw-calibration-access=READ-ONLY, type-emitter=RTE
package /PATAC/MSM/ModeAdjust
  composition sw component type ModeStatAndRsp
    179 x provide port:
      IfVeSMSeStPassCmprtMdNoti2ChmEvntStat: nonqueued-sender-com-spec=data-element=ChmEvenState/Val, provided-interface=ChmEvenState
      IfVeSMSeStPassCmprtMdRclRspStat: nonqueued-sender-com-spec=data-element=MdRclRspStat/Val, provided-interface=MdRclRspStat
      IfVeSMSuHMI2L_StMd1_Rsp: nonqueued-sender-com-spec=data-element=HMI2LMdRsp/Val, provided-interface=HMI2LMdRsp
      IfVeSMSuHMI2L_StMd{10..19}_Rsp: nonqueued-sender-com-spec=data-element=HMI2LMdRsp/Val, provided-interface=HMI2LMdRsp
      IfVeSMSuHMI2L_StMd2_Rsp: nonqueued-sender-com-spec=data-element=HMI2LMdRsp/Val, provided-interface=HMI2LMdRsp
      IfVeSMSuHMI2L_StMd{20..29}_Rsp: nonqueued-sender-com-spec=data-element=HMI2LMdRsp/Val, provided-interface=HMI2LMdRsp
      IfVeSMSuHMI2L_StMd3_Rsp: nonqueued-sender-com-spec=data-element=HMI2LMdRsp/Val, provided-interface=HMI2LMdRsp
      IfVeSMSuHMI2L_StMd{30..32}_Rsp: nonqueued-sender-com-spec=data-element=HMI2LMdRsp/Val, provided-interface=HMI2LMdRsp
      IfVeSMSuHMI2L_StMd{4..9}_Rsp: nonqueued-sender-com-spec=data-element=HMI2LMdRsp/Val, provided-interface=HMI2LMdRsp
      IfVeSMSuHMI2R_StMd1_Rsp: nonqueued-sender-com-spec=data-element=HMI2RMdRsp/Val, provided-interface=HMI2RMdRsp
      IfVeSMSuHMI2R_StMd{10..19}_Rsp: nonqueued-sender-com-spec=data-element=HMI2RMdRsp/Val, provided-interface=HMI2RMdRsp
      IfVeSMSuHMI2R_StMd2_Rsp: nonqueued-sender-com-spec=data-element=HMI2RMdRsp/Val, provided-interface=HMI2RMdRsp
      IfVeSMSuHMI2R_StMd{20..29}_Rsp: nonqueued-sender-com-spec=data-element=HMI2RMdRsp/Val, provided-interface=HMI2RMdRsp
      IfVeSMSuHMI2R_StMd3_Rsp: nonqueued-sender-com-spec=data-element=HMI2RMdRsp/Val, provided-interface=HMI2RMdRsp
      IfVeSMSuHMI2R_StMd{30..32}_Rsp: nonqueued-sender-com-spec=data-element=HMI2RMdRsp/Val, provided-interface=HMI2RMdRsp
      IfVeSMSuHMI2R_StMd{4..9}_Rsp: nonqueued-sender-com-spec=data-element=HMI2RMdRsp/Val, provided-interface=HMI2RMdRsp
      IfVeSMSuSRSCrt_MdSw1_Stat: nonqueued-sender-com-spec=data-element=SRSCrtMdStat_67_2/Val, provided-interface=SRSCrtMdStat_67_2
      IfVeSMSuSRSCrt_MdSw10_Stat: nonqueued-sender-com-spec=data-element=SRSCrtMdStat_67_2/Val, provided-interface=SRSCrtMdStat_67_2
      IfVeSMSuSRSCrt_MdSw{2..9}_Stat: nonqueued-sender-com-spec=data-element=SRSCrtMdStat_67_2/Val, provided-interface=SRSCrtMdStat_67_2
      IfVeSMSuSRSCrtMdIndTyp_67_2: nonqueued-sender-com-spec=data-element=SRSCrtMdIndTyp_67_2/Val, provided-interface=SRSCrtMdIndTyp_67_2
      IfVeSMSuStPassCmprtMd_Md1_CrtStat: nonqueued-sender-com-spec=data-element=StPassCmprtMdCrtMdStat/Val, provided-interface=StPassCmprtMdCrtMdStat
      IfVeSMSuStPassCmprtMd_Md{10..19}_CrtStat: nonqueued-sender-com-spec=data-element=StPassCmprtMdCrtMdStat/Val, provided-interface=StPassCmprtMdCrtMdStat
      IfVeSMSuStPassCmprtMd_Md2_CrtStat: nonqueued-sender-com-spec=data-element=StPassCmprtMdCrtMdStat/Val, provided-interface=StPassCmprtMdCrtMdStat
      IfVeSMSuStPassCmprtMd_Md{20..29}_CrtStat: nonqueued-sender-com-spec=data-element=StPassCmprtMdCrtMdStat/Val, provided-interface=StPassCmprtMdCrtMdStat
      IfVeSMSuStPassCmprtMd_Md3_CrtStat: nonqueued-sender-com-spec=data-element=StPassCmprtMdCrtMdStat/Val, provided-interface=StPassCmprtMdCrtMdStat
      IfVeSMSuStPassCmprtMd_Md{30..32}_CrtStat: nonqueued-sender-com-spec=data-element=StPassCmprtMdCrtMdStat/Val, provided-interface=StPassCmprtMdCrtMdStat
      IfVeSMSuStPassCmprtMd_Md{4..9}_CrtStat: nonqueued-sender-com-spec=data-element=StPassCmprtMdCrtMdStat/Val, provided-interface=StPassCmprtMdCrtMdStat
      IfVeSMSuStPassCmprtMd{10..19}RclRspStat: nonqueued-sender-com-spec=data-element=MdRclRspStat/Val, provided-interface=MdRclRspStat
      IfVeSMSuStPassCmprtMd1RclRspStat: nonqueued-sender-com-spec=data-element=MdRclRspStat/Val, provided-interface=MdRclRspStat
      IfVeSMSuStPassCmprtMd{20..29}RclRspStat: nonqueued-sender-com-spec=data-element=MdRclRspStat/Val, provided-interface=MdRclRspStat
      IfVeSMSuStPassCmprtMd2RclRspStat: nonqueued-sender-com-spec=data-element=MdRclRspStat/Val, provided-interface=MdRclRspStat
      IfVeSMSuStPassCmprtMd{30..32}RclRspStat: nonqueued-sender-com-spec=data-element=MdRclRspStat/Val, provided-interface=MdRclRspStat
      IfVeSMSuStPassCmprtMd{3..9}RclRspStat: nonqueued-sender-com-spec=data-element=MdRclRspStat/Val, provided-interface=MdRclRspStat
      IfVeSMSuStPassCmprtMdCrtMdStat: nonqueued-sender-com-spec=data-element=StPassCmprtMdCrtMdStat/Val, provided-interface=StPassCmprtMdCrtMdStat
      IfVeSMSuStPassCmprtMdHMIDisCmd: nonqueued-sender-com-spec=data-element=StPassCmprtMdHMIDisCmdSrv/Val, provided-interface=StPassCmprtMdHMIDisCmdSrv
      IfVeSMSuStSrv_StMd1_Rsp: nonqueued-sender-com-spec=data-element=StSrvMdRsp/Val, provided-interface=StSrvMdRsp
      IfVeSMSuStSrv_StMd{10..19}_Rsp: nonqueued-sender-com-spec=data-element=StSrvMdRsp/Val, provided-interface=StSrvMdRsp
      IfVeSMSuStSrv_StMd2_Rsp: nonqueued-sender-com-spec=data-element=StSrvMdRsp/Val, provided-interface=StSrvMdRsp
      IfVeSMSuStSrv_StMd{20..29}_Rsp: nonqueued-sender-com-spec=data-element=StSrvMdRsp/Val, provided-interface=StSrvMdRsp
      IfVeSMSuStSrv_StMd3_Rsp: nonqueued-sender-com-spec=data-element=StSrvMdRsp/Val, provided-interface=StSrvMdRsp
      IfVeSMSuStSrv_StMd{30..32}_Rsp: nonqueued-sender-com-spec=data-element=StSrvMdRsp/Val, provided-interface=StSrvMdRsp
      IfVeSMSuStSrv_StMd{4..9}_Rsp: nonqueued-sender-com-spec=data-element=StSrvMdRsp/Val, provided-interface=StSrvMdRsp
      ModeSrcTpLt: nonqueued-sender-com-spec=data-element=ModeSrcTp/Val, provided-interface=ModeSrcTp
      modestate32: nonqueued-sender-com-spec=data-element=modestate32/Val, provided-interface=modestate32
      oModeState: nonqueued-sender-com-spec=data-element=ModeState/Val, provided-interface=ModeState
      SRSMode: nonqueued-sender-com-spec=data-element=SRSCurMode/Val, provided-interface=SRSCurMode
    152 x require port:
      acsEntyMdReq: nonqueued-receiver-com-spec{data-element=MdReq/Val, filter=data-filter-type=ALWAYS}, required-interface=MdReq
      acsEntyMdSrcTp: nonqueued-receiver-com-spec{data-element=ModeSrcTp/Val, filter=data-filter-type=ALWAYS}, required-interface=ModeSrcTp
      acsExtMdReq: nonqueued-receiver-com-spec{data-element=MdReq/Val, filter=data-filter-type=ALWAYS}, required-interface=MdReq
      acsExtMdSrcTp: nonqueued-receiver-com-spec{data-element=ModeSrcTp/Val, filter=data-filter-type=ALWAYS}, required-interface=ModeSrcTp
      AllLugMdReq: nonqueued-receiver-com-spec{data-element=MdReq/Val, filter=data-filter-type=ALWAYS}, required-interface=MdReq
      AllLugSrcReqTp: nonqueued-receiver-com-spec{data-element=ModeSrcTp/Val, filter=data-filter-type=ALWAYS}, required-interface=ModeSrcTp
      AllVipMdReq: nonqueued-receiver-com-spec{data-element=MdReq/Val, filter=data-filter-type=ALWAYS}, required-interface=MdReq
      AllVipSrcReqTp: nonqueued-receiver-com-spec{data-element=ModeSrcTp/Val, filter=data-filter-type=ALWAYS}, required-interface=ModeSrcTp
      CommCond: nonqueued-receiver-com-spec{data-element=CommCond/Val, filter=data-filter-type=ALWAYS}, required-interface=CommCond
      CommExitCond: nonqueued-receiver-com-spec{data-element=CommExitCond/Val, filter=data-filter-type=ALWAYS}, required-interface=CommExitCond
      CommExitCondwithSpeed: nonqueued-receiver-com-spec{data-element=CommExitCondwithSpeed/Val, filter=data-filter-type=ALWAYS}, required-interface=CommExitCondwithSpeed
      IfVeSMSeStNumConfig: nonqueued-receiver-com-spec{data-element=IfVeSMSeStNumConfig/Val, filter=data-filter-type=ALWAYS}, required-interface=IfVeSMSeStNumConfig
      IfVeSMSuChmMgrStat: nonqueued-receiver-com-spec{data-element=IfVeSMSuChmMgrStat/Val, filter=data-filter-type=ALWAYS}, required-interface=IfVeSMSuChmMgrStat
      IntimacyRtMdReq: nonqueued-receiver-com-spec{data-element=AnyModeAjust/Val, filter=data-filter-type=ALWAYS}, required-interface=AnyModeAjust
      IntimacyRtMdSrcTp: nonqueued-receiver-com-spec{data-element=ModeSrcTp/Val, filter=data-filter-type=ALWAYS}, required-interface=ModeSrcTp
      INTMMdReq: nonqueued-receiver-com-spec{data-element=MdReq/Val, filter=data-filter-type=ALWAYS}, required-interface=MdReq
      INTMSrcReqTp: nonqueued-receiver-com-spec{data-element=ModeSrcTp/Val, filter=data-filter-type=ALWAYS}, required-interface=ModeSrcTp
      isAcsMdEntryArrivedAtTargetPos: nonqueued-receiver-com-spec{data-element=IsTargetPos/Val, filter=data-filter-type=ALWAYS}, required-interface=IsTargetPos
      isAcsMdEntryDoneFailed: nonqueued-receiver-com-spec{data-element=DoneFailed/Val, filter=data-filter-type=ALWAYS}, required-interface=DoneFailed
      isAcsMdEntryDoneOK: nonqueued-receiver-com-spec{data-element=DoneOK/Val, filter=data-filter-type=ALWAYS}, required-interface=DoneOK
      isAcsMdExtArrivedAtTargetPos: nonqueued-receiver-com-spec{data-element=IsTargetPos/Val, filter=data-filter-type=ALWAYS}, required-interface=IsTargetPos
      isAcsMdExtDoneFailed: nonqueued-receiver-com-spec{data-element=DoneFailed/Val, filter=data-filter-type=ALWAYS}, required-interface=DoneFailed
      isAcsMdExtDoneOK: nonqueued-receiver-com-spec{data-element=DoneOK/Val, filter=data-filter-type=ALWAYS}, required-interface=DoneOK
      isINTMArrivedAtTargetPos: nonqueued-receiver-com-spec{data-element=IsTargetPos/Val, filter=data-filter-type=ALWAYS}, required-interface=IsTargetPos
      isINTMDoneFailed: nonqueued-receiver-com-spec{data-element=DoneFailed/Val, filter=data-filter-type=ALWAYS}, required-interface=DoneFailed
      isINTMDoneOK: nonqueued-receiver-com-spec{data-element=DoneOK/Val, filter=data-filter-type=ALWAYS}, required-interface=DoneOK
      isINTMRArrivedAtTargetPos: nonqueued-receiver-com-spec{data-element=IsTargetPos/Val, filter=data-filter-type=ALWAYS}, required-interface=IsTargetPos
      isINTMRDoneFailed: nonqueued-receiver-com-spec{data-element=DoneFailed/Val, filter=data-filter-type=ALWAYS}, required-interface=DoneFailed
      isINTMRDoneOK: nonqueued-receiver-com-spec{data-element=DoneOK/Val, filter=data-filter-type=ALWAYS}, required-interface=DoneOK
      isLfFamlyArrivedAtTargetPos: nonqueued-receiver-com-spec{data-element=IsTargetPos/Val, filter=data-filter-type=ALWAYS}, required-interface=IsTargetPos
      isLfFamlyDoneFailed: nonqueued-receiver-com-spec{data-element=DoneFailed/Val, filter=data-filter-type=ALWAYS}, required-interface=DoneFailed
      isLfFamlyDoneOK: nonqueued-receiver-com-spec{data-element=DoneOK/Val, filter=data-filter-type=ALWAYS}, required-interface=DoneOK
      isLfLugArrivedAtTargetPos: nonqueued-receiver-com-spec{data-element=IsTargetPos/Val, filter=data-filter-type=ALWAYS}, required-interface=IsTargetPos
      isLfLugDoneFailed: nonqueued-receiver-com-spec{data-element=DoneFailed/Val, filter=data-filter-type=ALWAYS}, required-interface=DoneFailed
      isLfLugDoneOK: nonqueued-receiver-com-spec{data-element=DoneOK/Val, filter=data-filter-type=ALWAYS}, required-interface=DoneOK
      isLfLyArrivedAtTargetPos: nonqueued-receiver-com-spec{data-element=IsTargetPos/Val, filter=data-filter-type=ALWAYS}, required-interface=IsTargetPos
      isLfLyDoneFailed: nonqueued-receiver-com-spec{data-element=DoneFailed/Val, filter=data-filter-type=ALWAYS}, required-interface=DoneFailed
      isLfLyDoneOK: nonqueued-receiver-com-spec{data-element=DoneOK/Val, filter=data-filter-type=ALWAYS}, required-interface=DoneOK
      isLfRecoveryArrivedAtTargetPos: nonqueued-receiver-com-spec{data-element=IsTargetPos/Val, filter=data-filter-type=ALWAYS}, required-interface=IsTargetPos
      isLfRecoveryDoneFailed: nonqueued-receiver-com-spec{data-element=DoneFailed/Val, filter=data-filter-type=ALWAYS}, required-interface=DoneFailed
      isLfRecoveryDoneOK: nonqueued-receiver-com-spec{data-element=DoneOK/Val, filter=data-filter-type=ALWAYS}, required-interface=DoneOK
      isLfVipArrivedAtTargetPos: nonqueued-receiver-com-spec{data-element=IsTargetPos/Val, filter=data-filter-type=ALWAYS}, required-interface=IsTargetPos
      isLfVipDoneFailed: nonqueued-receiver-com-spec{data-element=DoneFailed/Val, filter=data-filter-type=ALWAYS}, required-interface=DoneFailed
      isLfVipDoneOK: nonqueued-receiver-com-spec{data-element=DoneOK/Val, filter=data-filter-type=ALWAYS}, required-interface=DoneOK
      isLgrstCloseLArrivedAtTargetPos: nonqueued-receiver-com-spec{data-element=IsTargetPos/Val, filter=data-filter-type=ALWAYS}, required-interface=IsTargetPos
      isLgrstCloseLDoneFailed: nonqueued-receiver-com-spec{data-element=DoneFailed/Val, filter=data-filter-type=ALWAYS}, required-interface=DoneFailed
      isLgrstCloseLDoneOK: nonqueued-receiver-com-spec{data-element=DoneOK/Val, filter=data-filter-type=ALWAYS}, required-interface=DoneOK
      isLgrstCloseRArrivedAtTargetPos: nonqueued-receiver-com-spec{data-element=IsTargetPos/Val, filter=data-filter-type=ALWAYS}, required-interface=IsTargetPos
      isLgrstCloseRDoneFailed: nonqueued-receiver-com-spec{data-element=DoneFailed/Val, filter=data-filter-type=ALWAYS}, required-interface=DoneFailed
      isLgrstCloseRDoneOK: nonqueued-receiver-com-spec{data-element=DoneOK/Val, filter=data-filter-type=ALWAYS}, required-interface=DoneOK
      isLgrstOpenLArrivedAtTargetPos: nonqueued-receiver-com-spec{data-element=IsTargetPos/Val, filter=data-filter-type=ALWAYS}, required-interface=IsTargetPos
      isLgrstOpenLDoneFailed: nonqueued-receiver-com-spec{data-element=DoneFailed/Val, filter=data-filter-type=ALWAYS}, required-interface=DoneFailed
      isLgrstOpenLDoneOK: nonqueued-receiver-com-spec{data-element=DoneOK/Val, filter=data-filter-type=ALWAYS}, required-interface=DoneOK
      isLgrstOpenRArrivedAtTargetPos: nonqueued-receiver-com-spec{data-element=IsTargetPos/Val, filter=data-filter-type=ALWAYS}, required-interface=IsTargetPos
      isLgrstOpenRDoneFailed: nonqueued-receiver-com-spec{data-element=DoneFailed/Val, filter=data-filter-type=ALWAYS}, required-interface=DoneFailed
      isLgrstOpenRDoneOK: nonqueued-receiver-com-spec{data-element=DoneOK/Val, filter=data-filter-type=ALWAYS}, required-interface=DoneOK
      isRfFamlyDoneFailed: nonqueued-receiver-com-spec{data-element=DoneFailed/Val, filter=data-filter-type=ALWAYS}, required-interface=DoneFailed
      isRfFamlyDoneOK: nonqueued-receiver-com-spec{data-element=DoneOK/Val, filter=data-filter-type=ALWAYS}, required-interface=DoneOK
      isRtFamlyArrivedAtTargetPos: nonqueued-receiver-com-spec{data-element=IsTargetPos/Val, filter=data-filter-type=ALWAYS}, required-interface=IsTargetPos
      isRtLugArrivedAtTargetPos: nonqueued-receiver-com-spec{data-element=IsTargetPos/Val, filter=data-filter-type=ALWAYS}, required-interface=IsTargetPos
      isRtLugDoneFailed: nonqueued-receiver-com-spec{data-element=DoneFailed/Val, filter=data-filter-type=ALWAYS}, required-interface=DoneFailed
      isRtLugDoneOK: nonqueued-receiver-com-spec{data-element=DoneOK/Val, filter=data-filter-type=ALWAYS}, required-interface=DoneOK
      isRtLyArrivedAtTargetPos: nonqueued-receiver-com-spec{data-element=IsTargetPos/Val, filter=data-filter-type=ALWAYS}, required-interface=IsTargetPos
      isRtLyDoneFailed: nonqueued-receiver-com-spec{data-element=DoneFailed/Val, filter=data-filter-type=ALWAYS}, required-interface=DoneFailed
      isRtLyDoneOK: nonqueued-receiver-com-spec{data-element=DoneOK/Val, filter=data-filter-type=ALWAYS}, required-interface=DoneOK
      isRtRecoveryArrivedAtTargetPos: nonqueued-receiver-com-spec{data-element=IsTargetPos/Val, filter=data-filter-type=ALWAYS}, required-interface=IsTargetPos
      isRtRecoveryDoneFailed: nonqueued-receiver-com-spec{data-element=DoneFailed/Val, filter=data-filter-type=ALWAYS}, required-interface=DoneFailed
      isRtRecoveryDoneOK: nonqueued-receiver-com-spec{data-element=DoneOK/Val, filter=data-filter-type=ALWAYS}, required-interface=DoneOK
      isRtVipArrivedAtTargetPos: nonqueued-receiver-com-spec{data-element=IsTargetPos/Val, filter=data-filter-type=ALWAYS}, required-interface=IsTargetPos
      isRtVipDoneFailed: nonqueued-receiver-com-spec{data-element=DoneFailed/Val, filter=data-filter-type=ALWAYS}, required-interface=DoneFailed
      isRtVipDoneOK: nonqueued-receiver-com-spec{data-element=DoneOK/Val, filter=data-filter-type=ALWAYS}, required-interface=DoneOK
      KeSMSbMdChime2Enable: parameter-require-com-spec{init-value=0, parameter=MdChime2Enable/Val}, required-interface=MdChime2Enable
      KeSMSbSRSPosNumConfig: parameter-require-com-spec{init-value=4, parameter=SRSPosNumConfig/Val}, required-interface=SRSPosNumConfig
      KeSMSuChmReqDurnTm: parameter-require-com-spec{init-value=200, parameter=KeSMSuChmReqDurnTm/Val}, required-interface=KeSMSuChmReqDurnTm
      KeSMSuChmReqIntlTm: parameter-require-com-spec{init-value=50, parameter=KeSMSuChmReqIntlTm/Val}, required-interface=KeSMSuChmReqIntlTm
      KeSMSuRspStatHldTm: parameter-require-com-spec{init-value=100, parameter=KeSMSuRspStatHldTm/Val}, required-interface=KeSMSuRspStatHldTm
      LfFamlyReq: nonqueued-receiver-com-spec{data-element=MdReq/Val, filter=data-filter-type=ALWAYS}, required-interface=MdReq
      LfFamlySrcReqTp: nonqueued-receiver-com-spec{data-element=ModeSrcTp/Val, filter=data-filter-type=ALWAYS}, required-interface=ModeSrcTp
      LfLyMdReq: nonqueued-receiver-com-spec{data-element=MdReq/Val, filter=data-filter-type=ALWAYS}, required-interface=MdReq
      LfLySrcReqTp: nonqueued-receiver-com-spec{data-element=ModeSrcTp/Val, filter=data-filter-type=ALWAYS}, required-interface=ModeSrcTp
      LgrstCloseLtMdReq: nonqueued-receiver-com-spec{data-element=AnyModeAjust/Val, filter=data-filter-type=ALWAYS}, required-interface=AnyModeAjust
      LgrstCloseLtSrcReqTp: nonqueued-receiver-com-spec{data-element=ModeSrcTp/Val, filter=data-filter-type=ALWAYS}, required-interface=ModeSrcTp
      LgrstCloseRtMdReq: nonqueued-receiver-com-spec{data-element=AnyModeAjust/Val, filter=data-filter-type=ALWAYS}, required-interface=AnyModeAjust
      LgrstCloseRtSrcReqTp: nonqueued-receiver-com-spec{data-element=ModeSrcTp/Val, filter=data-filter-type=ALWAYS}, required-interface=ModeSrcTp
      LgrstOpenLtMdReq: nonqueued-receiver-com-spec{data-element=AnyModeAjust/Val, filter=data-filter-type=ALWAYS}, required-interface=AnyModeAjust
      LgrstOpenLtSrcReqTp: nonqueued-receiver-com-spec{data-element=ModeSrcTp/Val, filter=data-filter-type=ALWAYS}, required-interface=ModeSrcTp
      LgrstOpenRtMdReq: nonqueued-receiver-com-spec{data-element=AnyModeAjust/Val, filter=data-filter-type=ALWAYS}, required-interface=AnyModeAjust
      LgrstOpenRtSrcReqTp: nonqueued-receiver-com-spec{data-element=ModeSrcTp/Val, filter=data-filter-type=ALWAYS}, required-interface=ModeSrcTp
      LtLugMdReq: nonqueued-receiver-com-spec{data-element=MdReq/Val, filter=data-filter-type=ALWAYS}, required-interface=MdReq
      LtLugSrcReqTp: nonqueued-receiver-com-spec{data-element=ModeSrcTp/Val, filter=data-filter-type=ALWAYS}, required-interface=ModeSrcTp
      LtRcvyMdReq: nonqueued-receiver-com-spec{data-element=MdReq/Val, filter=data-filter-type=ALWAYS}, required-interface=MdReq
      LtRcvySrcReqTp: nonqueued-receiver-com-spec{data-element=ModeSrcTp/Val, filter=data-filter-type=ALWAYS}, required-interface=ModeSrcTp
      LtVipMdReq: nonqueued-receiver-com-spec{data-element=MdReq/Val, filter=data-filter-type=ALWAYS}, required-interface=MdReq
      LtVipSrcReqTp: nonqueued-receiver-com-spec{data-element=ModeSrcTp/Val, filter=data-filter-type=ALWAYS}, required-interface=ModeSrcTp
      LugMdLtAvl: nonqueued-receiver-com-spec{data-element=ModeAdjustAvailable/Val, filter=data-filter-type=ALWAYS}, required-interface=ModeAdjustAvailable
      LugMdRtAvl: nonqueued-receiver-com-spec{data-element=ModeAdjustAvailable/Val, filter=data-filter-type=ALWAYS}, required-interface=ModeAdjustAvailable
      PosArray: nonqueued-receiver-com-spec{data-element=PosArray/Val, filter=data-filter-type=ALWAYS, init-value=11 x 0}, required-interface=PosArray
      PwrMdChked: nonqueued-receiver-com-spec{data-element=PowerMode/Val, filter=data-filter-type=ALWAYS}, required-interface=PowerMode
      R3LMdSeatOccupied: nonqueued-receiver-com-spec{data-element=MdSeatOccupied/Val, filter=data-filter-type=ALWAYS, init-value=0}, required-interface=MdSeatOccupied
      R3RMdSeatOccupied: nonqueued-receiver-com-spec{data-element=MdSeatOccupied/Val, filter=data-filter-type=ALWAYS, init-value=0}, required-interface=MdSeatOccupied
      RtFamlyMdReq: nonqueued-receiver-com-spec{data-element=MdReq/Val, filter=data-filter-type=ALWAYS}, required-interface=MdReq
      RtFamlySrcReqTp: nonqueued-receiver-com-spec{data-element=ModeSrcTp/Val, filter=data-filter-type=ALWAYS}, required-interface=ModeSrcTp
      RtLugMdReq: nonqueued-receiver-com-spec{data-element=MdReq/Val, filter=data-filter-type=ALWAYS}, required-interface=MdReq
      RtLugSrcReqTp: nonqueued-receiver-com-spec{data-element=ModeSrcTp/Val, filter=data-filter-type=ALWAYS}, required-interface=ModeSrcTp
      RtLyMdReq: nonqueued-receiver-com-spec{data-element=MdReq/Val, filter=data-filter-type=ALWAYS}, required-interface=MdReq
      RtLySrcReqTp: nonqueued-receiver-com-spec{data-element=ModeSrcTp/Val, filter=data-filter-type=ALWAYS}, required-interface=ModeSrcTp
      RtRcvyMdReq: nonqueued-receiver-com-spec{data-element=MdReq/Val, filter=data-filter-type=ALWAYS}, required-interface=MdReq
      RtRcvySrcReqTp: nonqueued-receiver-com-spec{data-element=ModeSrcTp/Val, filter=data-filter-type=ALWAYS}, required-interface=ModeSrcTp
      RtVipMdReq: nonqueued-receiver-com-spec{data-element=MdReq/Val, filter=data-filter-type=ALWAYS}, required-interface=MdReq
      RtVipSrcReqTp: nonqueued-receiver-com-spec{data-element=ModeSrcTp/Val, filter=data-filter-type=ALWAYS}, required-interface=ModeSrcTp
      SoftIntAcsEnty: nonqueued-receiver-com-spec{data-element=IntEnable/Val, filter=data-filter-type=ALWAYS}, required-interface=IntEnable
      SoftIntAcsExt: nonqueued-receiver-com-spec{data-element=IntEnable/Val, filter=data-filter-type=ALWAYS}, required-interface=IntEnable
      SoftIntAllLug: nonqueued-receiver-com-spec{data-element=IntEnable/Val, filter=data-filter-type=ALWAYS}, required-interface=IntEnable
      SoftIntAllVip: nonqueued-receiver-com-spec{data-element=IntEnable/Val, filter=data-filter-type=ALWAYS}, required-interface=IntEnable
      SoftIntIntimacyRt: nonqueued-receiver-com-spec{data-element=IntEnable/Val, filter=data-filter-type=ALWAYS}, required-interface=IntEnable
      SoftIntINTM: nonqueued-receiver-com-spec{data-element=IntEnable/Val, filter=data-filter-type=ALWAYS}, required-interface=IntEnable
      SoftIntLfFamly: nonqueued-receiver-com-spec{data-element=IntEnable/Val, filter=data-filter-type=ALWAYS}, required-interface=IntEnable
      SoftIntLfLug: nonqueued-receiver-com-spec{data-element=IntEnable/Val, filter=data-filter-type=ALWAYS}, required-interface=IntEnable
      SoftIntLfLy: nonqueued-receiver-com-spec{data-element=IntEnable/Val, filter=data-filter-type=ALWAYS}, required-interface=IntEnable
      SoftIntLfRcvy: nonqueued-receiver-com-spec{data-element=IntEnable/Val, filter=data-filter-type=ALWAYS}, required-interface=IntEnable
      SoftIntLfVip: nonqueued-receiver-com-spec{data-element=IntEnable/Val, filter=data-filter-type=ALWAYS}, required-interface=IntEnable
      SoftIntLgrstCloseLt: nonqueued-receiver-com-spec{data-element=IntEnable/Val, filter=data-filter-type=ALWAYS}, required-interface=IntEnable
      SoftIntLgrstCloseRt: nonqueued-receiver-com-spec{data-element=IntEnable/Val, filter=data-filter-type=ALWAYS}, required-interface=IntEnable
      SoftIntLgrstOpenLt: nonqueued-receiver-com-spec{data-element=IntEnable/Val, filter=data-filter-type=ALWAYS}, required-interface=IntEnable
      SoftIntLgrstOpenRt: nonqueued-receiver-com-spec{data-element=IntEnable/Val, filter=data-filter-type=ALWAYS}, required-interface=IntEnable
      SoftIntRtFamly: nonqueued-receiver-com-spec{data-element=IntEnable/Val, filter=data-filter-type=ALWAYS}, required-interface=IntEnable
      SoftIntRtLug: nonqueued-receiver-com-spec{data-element=IntEnable/Val, filter=data-filter-type=ALWAYS}, required-interface=IntEnable
      SoftIntRtLy: nonqueued-receiver-com-spec{data-element=IntEnable/Val, filter=data-filter-type=ALWAYS}, required-interface=IntEnable
      SoftIntRtRcvy: nonqueued-receiver-com-spec{data-element=IntEnable/Val, filter=data-filter-type=ALWAYS}, required-interface=IntEnable
      SoftIntRtVip: nonqueued-receiver-com-spec{data-element=IntEnable/Val, filter=data-filter-type=ALWAYS}, required-interface=IntEnable
      SwIntAcsEnty: nonqueued-receiver-com-spec{data-element=IntEnable/Val, filter=data-filter-type=ALWAYS}, required-interface=IntEnable
      SwIntAcsExt: nonqueued-receiver-com-spec{data-element=IntEnable/Val, filter=data-filter-type=ALWAYS}, required-interface=IntEnable
      SwIntAllLug: nonqueued-receiver-com-spec{data-element=IntEnable/Val, filter=data-filter-type=ALWAYS}, required-interface=IntEnable
      SwIntAllVip: nonqueued-receiver-com-spec{data-element=IntEnable/Val, filter=data-filter-type=ALWAYS}, required-interface=IntEnable
      SwIntIntimacyRt: nonqueued-receiver-com-spec{data-element=IntEnable/Val, filter=data-filter-type=ALWAYS}, required-interface=IntEnable
      SwIntINTM: nonqueued-receiver-com-spec{data-element=IntEnable/Val, filter=data-filter-type=ALWAYS}, required-interface=IntEnable
      SwIntLfFamly: nonqueued-receiver-com-spec{data-element=IntEnable/Val, filter=data-filter-type=ALWAYS}, required-interface=IntEnable
      SwIntLfLug: nonqueued-receiver-com-spec{data-element=IntEnable/Val, filter=data-filter-type=ALWAYS}, required-interface=IntEnable
      SwIntLfLy: nonqueued-receiver-com-spec{data-element=IntEnable/Val, filter=data-filter-type=ALWAYS}, required-interface=IntEnable
      SwIntLfRcvy: nonqueued-receiver-com-spec{data-element=IntEnable/Val, filter=data-filter-type=ALWAYS}, required-interface=IntEnable
      SwIntLfVip: nonqueued-receiver-com-spec{data-element=IntEnable/Val, filter=data-filter-type=ALWAYS}, required-interface=IntEnable
      SwIntLgrstCloseLt: nonqueued-receiver-com-spec{data-element=IntEnable/Val, filter=data-filter-type=ALWAYS}, required-interface=IntEnable
      SwIntLgrstCloseRt: nonqueued-receiver-com-spec{data-element=IntEnable/Val, filter=data-filter-type=ALWAYS}, required-interface=IntEnable
      SwIntLgrstOpenLt: nonqueued-receiver-com-spec{data-element=IntEnable/Val, filter=data-filter-type=ALWAYS}, required-interface=IntEnable
      SwIntLgrstOpenRt: nonqueued-receiver-com-spec{data-element=IntEnable/Val, filter=data-filter-type=ALWAYS}, required-interface=IntEnable
      SwIntRtFamly: nonqueued-receiver-com-spec{data-element=IntEnable/Val, filter=data-filter-type=ALWAYS}, required-interface=IntEnable
      SwIntRtLug: nonqueued-receiver-com-spec{data-element=IntEnable/Val, filter=data-filter-type=ALWAYS}, required-interface=IntEnable
      SwIntRtLy: nonqueued-receiver-com-spec{data-element=IntEnable/Val, filter=data-filter-type=ALWAYS}, required-interface=IntEnable
      SwIntRtRcvy: nonqueued-receiver-com-spec{data-element=IntEnable/Val, filter=data-filter-type=ALWAYS}, required-interface=IntEnable
      SwIntRtVip: nonqueued-receiver-com-spec{data-element=IntEnable/Val, filter=data-filter-type=ALWAYS}, required-interface=IntEnable
      VipMdLtAvl: nonqueued-receiver-com-spec{data-element=ModeAdjustAvailable/Val, filter=data-filter-type=ALWAYS}, required-interface=ModeAdjustAvailable
      VipMdRtAvl: nonqueued-receiver-com-spec{data-element=ModeAdjustAvailable/Val, filter=data-filter-type=ALWAYS}, required-interface=ModeAdjustAvailable
    component ModeRsp: type=ModeRsp
    component ModeStatCtrl: type=ModeStatCtrl
    component StNumChk: type=StNumChk
    connect ModeStatCtrl.IsStBsy32Bit -> ModeRsp.IsStBsy32Bit
    connect ModeStatCtrl.IsTargetPos32Bit -> ModeRsp.IsTargetPos32Bit
    connect ModeStatCtrl.MdXX_Rsp -> ModeRsp.MdXX_Rsp
    connect ModeStatCtrl.MdXX_SrcReqTp -> ModeRsp.MdXX_SrcReqTp
    connect ModeStatCtrl.modestate32 -> ModeRsp.modestate32
    connect StNumChk.StNumFlg -> ModeStatCtrl.StNumFlg
    delegate ModeStatCtrl.acsEntyMdReq <-> outer port ModeStatAndRsp/acsEntyMdReq
    delegate ModeStatCtrl.acsEntyMdSrcTp <-> outer port ModeStatAndRsp/acsEntyMdSrcTp
    delegate ModeStatCtrl.acsExtMdReq <-> outer port ModeStatAndRsp/acsExtMdReq
    delegate ModeStatCtrl.acsExtMdSrcTp <-> outer port ModeStatAndRsp/acsExtMdSrcTp
    delegate ModeStatCtrl.AllLugMdReq <-> outer port ModeStatAndRsp/AllLugMdReq
    delegate ModeStatCtrl.AllLugSrcReqTp <-> outer port ModeStatAndRsp/AllLugSrcReqTp
    delegate ModeStatCtrl.AllVipMdReq <-> outer port ModeStatAndRsp/AllVipMdReq
    delegate ModeStatCtrl.AllVipSrcReqTp <-> outer port ModeStatAndRsp/AllVipSrcReqTp
    delegate ModeStatCtrl.CommCond <-> outer port ModeStatAndRsp/CommCond
    delegate ModeStatCtrl.CommExitCond <-> outer port ModeStatAndRsp/CommExitCond
    delegate ModeStatCtrl.CommExitCondwithSpeed <-> outer port ModeStatAndRsp/CommExitCondwithSpeed
    delegate StNumChk.IfVeSMSeStNumConfig <-> outer port ModeStatAndRsp/IfVeSMSeStNumConfig
    delegate ModeRsp.IfVeSMSeStPassCmprtMdNoti2ChmEvntStat <-> outer port ModeStatAndRsp/IfVeSMSeStPassCmprtMdNoti2ChmEvntStat
    delegate ModeRsp.IfVeSMStPassCmprtMd_RfCtrl_Sw_RclRspStat <-> outer port IfVeSMSeStPassCmprtMdRclRspStat
    delegate ModeRsp.IfVeSMSuChmMgrStat <-> outer port ModeStatAndRsp/IfVeSMSuChmMgrStat
    delegate ModeRsp.IfVeSMSuHMI2L_StMd1_Rsp <-> outer port ModeStatAndRsp/IfVeSMSuHMI2L_StMd1_Rsp
    delegate ModeRsp.IfVeSMSuHMI2L_StMd{10..19}_Rsp <-> outer port ModeStatAndRsp/IfVeSMSuHMI2L_StMd{10..19}_Rsp
    delegate ModeRsp.IfVeSMSuHMI2L_StMd2_Rsp <-> outer port ModeStatAndRsp/IfVeSMSuHMI2L_StMd2_Rsp
    delegate ModeRsp.IfVeSMSuHMI2L_StMd{20..29}_Rsp <-> outer port ModeStatAndRsp/IfVeSMSuHMI2L_StMd{20..29}_Rsp
    delegate ModeRsp.IfVeSMSuHMI2L_StMd3_Rsp <-> outer port ModeStatAndRsp/IfVeSMSuHMI2L_StMd3_Rsp
    delegate ModeRsp.IfVeSMSuHMI2L_StMd{30..32}_Rsp <-> outer port ModeStatAndRsp/IfVeSMSuHMI2L_StMd{30..32}_Rsp
    delegate ModeRsp.IfVeSMSuHMI2L_StMd{4..9}_Rsp <-> outer port ModeStatAndRsp/IfVeSMSuHMI2L_StMd{4..9}_Rsp
    delegate ModeRsp.IfVeSMSuHMI2R_StMd1_Rsp <-> outer port ModeStatAndRsp/IfVeSMSuHMI2R_StMd1_Rsp
    delegate ModeRsp.IfVeSMSuHMI2R_StMd{10..19}_Rsp <-> outer port ModeStatAndRsp/IfVeSMSuHMI2R_StMd{10..19}_Rsp
    delegate ModeRsp.IfVeSMSuHMI2R_StMd2_Rsp <-> outer port ModeStatAndRsp/IfVeSMSuHMI2R_StMd2_Rsp
    delegate ModeRsp.IfVeSMSuHMI2R_StMd{20..29}_Rsp <-> outer port ModeStatAndRsp/IfVeSMSuHMI2R_StMd{20..29}_Rsp
    delegate ModeRsp.IfVeSMSuHMI2R_StMd3_Rsp <-> outer port ModeStatAndRsp/IfVeSMSuHMI2R_StMd3_Rsp
    delegate ModeRsp.IfVeSMSuHMI2R_StMd{30..32}_Rsp <-> outer port ModeStatAndRsp/IfVeSMSuHMI2R_StMd{30..32}_Rsp
    delegate ModeRsp.IfVeSMSuHMI2R_StMd{4..9}_Rsp <-> outer port ModeStatAndRsp/IfVeSMSuHMI2R_StMd{4..9}_Rsp
    delegate ModeRsp.IfVeSMSuSRSCrt_MdSw1_Stat <-> outer port ModeStatAndRsp/IfVeSMSuSRSCrt_MdSw1_Stat
    delegate ModeRsp.IfVeSMSuSRSCrt_MdSw10_Stat <-> outer port ModeStatAndRsp/IfVeSMSuSRSCrt_MdSw10_Stat
    delegate ModeRsp.IfVeSMSuSRSCrt_MdSw{2..9}_Stat <-> outer port ModeStatAndRsp/IfVeSMSuSRSCrt_MdSw{2..9}_Stat
    delegate ModeRsp.IfVeSMSuSRSCrtMdIndTyp_67_2 <-> outer port ModeStatAndRsp/IfVeSMSuSRSCrtMdIndTyp_67_2
    delegate ModeRsp.IfVeSMSuStPassCmprtMd_Md1_CrtStat <-> outer port ModeStatAndRsp/IfVeSMSuStPassCmprtMd_Md1_CrtStat
    delegate ModeRsp.IfVeSMSuStPassCmprtMd_Md{10..19}_CrtStat <-> outer port ModeStatAndRsp/IfVeSMSuStPassCmprtMd_Md{10..19}_CrtStat
    delegate ModeRsp.IfVeSMSuStPassCmprtMd_Md2_CrtStat <-> outer port ModeStatAndRsp/IfVeSMSuStPassCmprtMd_Md2_CrtStat
    delegate ModeRsp.IfVeSMSuStPassCmprtMd_Md{20..29}_CrtStat <-> outer port ModeStatAndRsp/IfVeSMSuStPassCmprtMd_Md{20..29}_CrtStat
    delegate ModeRsp.IfVeSMSuStPassCmprtMd_Md3_CrtStat <-> outer port ModeStatAndRsp/IfVeSMSuStPassCmprtMd_Md3_CrtStat
    delegate ModeRsp.IfVeSMSuStPassCmprtMd_Md{30..32}_CrtStat <-> outer port ModeStatAndRsp/IfVeSMSuStPassCmprtMd_Md{30..32}_CrtStat
    delegate ModeRsp.IfVeSMSuStPassCmprtMd_Md{4..9}_CrtStat <-> outer port ModeStatAndRsp/IfVeSMSuStPassCmprtMd_Md{4..9}_CrtStat
    delegate ModeRsp.IfVeSMSuStPassCmprtMd{10..19}RclRspStat <-> outer port ModeStatAndRsp/IfVeSMSuStPassCmprtMd{10..19}RclRspStat
    delegate ModeRsp.IfVeSMSuStPassCmprtMd1RclRspStat <-> outer port ModeStatAndRsp/IfVeSMSuStPassCmprtMd1RclRspStat
    delegate ModeRsp.IfVeSMSuStPassCmprtMd{20..29}RclRspStat <-> outer port ModeStatAndRsp/IfVeSMSuStPassCmprtMd{20..29}RclRspStat
    delegate ModeRsp.IfVeSMSuStPassCmprtMd2RclRspStat <-> outer port ModeStatAndRsp/IfVeSMSuStPassCmprtMd2RclRspStat
    delegate ModeRsp.IfVeSMSuStPassCmprtMd{30..32}RclRspStat <-> outer port ModeStatAndRsp/IfVeSMSuStPassCmprtMd{30..32}RclRspStat
    delegate ModeRsp.IfVeSMSuStPassCmprtMd{3..9}RclRspStat <-> outer port ModeStatAndRsp/IfVeSMSuStPassCmprtMd{3..9}RclRspStat
    delegate ModeRsp.IfVeSMSuStPassCmprtMdCrtMdStat <-> outer port ModeStatAndRsp/IfVeSMSuStPassCmprtMdCrtMdStat
    delegate ModeRsp.IfVeSMSuStPassCmprtMdHMIDisCmd <-> outer port ModeStatAndRsp/IfVeSMSuStPassCmprtMdHMIDisCmd
    delegate ModeRsp.IfVeSMSuStSrv_StMd1_Rsp <-> outer port ModeStatAndRsp/IfVeSMSuStSrv_StMd1_Rsp
    delegate ModeRsp.IfVeSMSuStSrv_StMd{10..19}_Rsp <-> outer port ModeStatAndRsp/IfVeSMSuStSrv_StMd{10..19}_Rsp
    delegate ModeRsp.IfVeSMSuStSrv_StMd2_Rsp <-> outer port ModeStatAndRsp/IfVeSMSuStSrv_StMd2_Rsp
    delegate ModeRsp.IfVeSMSuStSrv_StMd{20..29}_Rsp <-> outer port ModeStatAndRsp/IfVeSMSuStSrv_StMd{20..29}_Rsp
    delegate ModeRsp.IfVeSMSuStSrv_StMd3_Rsp <-> outer port ModeStatAndRsp/IfVeSMSuStSrv_StMd3_Rsp
    delegate ModeRsp.IfVeSMSuStSrv_StMd{30..32}_Rsp <-> outer port ModeStatAndRsp/IfVeSMSuStSrv_StMd{30..32}_Rsp
    delegate ModeRsp.IfVeSMSuStSrv_StMd{4..9}_Rsp <-> outer port ModeStatAndRsp/IfVeSMSuStSrv_StMd{4..9}_Rsp
    delegate ModeStatCtrl.IntimacyRtMdReq <-> outer port ModeStatAndRsp/IntimacyRtMdReq
    delegate ModeStatCtrl.IntimacyRtMdSrcTp <-> outer port ModeStatAndRsp/IntimacyRtMdSrcTp
    delegate ModeStatCtrl.INTMMdReq <-> outer port ModeStatAndRsp/INTMMdReq
    delegate ModeStatCtrl.INTMSrcReqTp <-> outer port ModeStatAndRsp/INTMSrcReqTp
    delegate ModeStatCtrl.isAcsMdEntryArrivedAtTargetPos <-> outer port ModeStatAndRsp/isAcsMdEntryArrivedAtTargetPos
    delegate ModeStatCtrl.isAcsMdEntryDoneFailed <-> outer port ModeStatAndRsp/isAcsMdEntryDoneFailed
    delegate ModeStatCtrl.isAcsMdEntryDoneOK <-> outer port ModeStatAndRsp/isAcsMdEntryDoneOK
    delegate ModeStatCtrl.isAcsMdExtArrivedAtTargetPos <-> outer port ModeStatAndRsp/isAcsMdExtArrivedAtTargetPos
    delegate ModeStatCtrl.isAcsMdExtDoneFailed <-> outer port ModeStatAndRsp/isAcsMdExtDoneFailed
    delegate ModeStatCtrl.isAcsMdExtDoneOK <-> outer port ModeStatAndRsp/isAcsMdExtDoneOK
    delegate ModeStatCtrl.isINTMArrivedAtTargetPos <-> outer port ModeStatAndRsp/isINTMArrivedAtTargetPos
    delegate ModeStatCtrl.isINTMDoneFailed <-> outer port ModeStatAndRsp/isINTMDoneFailed
    delegate ModeStatCtrl.isINTMDoneOK <-> outer port ModeStatAndRsp/isINTMDoneOK
    delegate ModeStatCtrl.isINTMRArrivedAtTargetPos <-> outer port ModeStatAndRsp/isINTMRArrivedAtTargetPos
    delegate ModeStatCtrl.isINTMRDoneFailed <-> outer port ModeStatAndRsp/isINTMRDoneFailed
    delegate ModeStatCtrl.isINTMRDoneOK <-> outer port ModeStatAndRsp/isINTMRDoneOK
    delegate ModeStatCtrl.isLfFamlyArrivedAtTargetPos <-> outer port ModeStatAndRsp/isLfFamlyArrivedAtTargetPos
    delegate ModeStatCtrl.isLfFamlyDoneFailed <-> outer port ModeStatAndRsp/isLfFamlyDoneFailed
    delegate ModeStatCtrl.isLfFamlyDoneOK <-> outer port ModeStatAndRsp/isLfFamlyDoneOK
    delegate ModeStatCtrl.isLfLugArrivedAtTargetPos <-> outer port ModeStatAndRsp/isLfLugArrivedAtTargetPos
    delegate ModeStatCtrl.isLfLugDoneFailed <-> outer port ModeStatAndRsp/isLfLugDoneFailed
    delegate ModeStatCtrl.isLfLugDoneOK <-> outer port ModeStatAndRsp/isLfLugDoneOK
    delegate ModeStatCtrl.isLfLyArrivedAtTargetPos <-> outer port ModeStatAndRsp/isLfLyArrivedAtTargetPos
    delegate ModeStatCtrl.isLfLyDoneFailed <-> outer port ModeStatAndRsp/isLfLyDoneFailed
    delegate ModeStatCtrl.isLfLyDoneOK <-> outer port ModeStatAndRsp/isLfLyDoneOK
    delegate ModeStatCtrl.isLfRecoveryArrivedAtTargetPos <-> outer port ModeStatAndRsp/isLfRecoveryArrivedAtTargetPos
    delegate ModeStatCtrl.isLfRecoveryDoneFailed <-> outer port ModeStatAndRsp/isLfRecoveryDoneFailed
    delegate ModeStatCtrl.isLfRecoveryDoneOK <-> outer port ModeStatAndRsp/isLfRecoveryDoneOK
    delegate ModeStatCtrl.isLfVipArrivedAtTargetPos <-> outer port ModeStatAndRsp/isLfVipArrivedAtTargetPos
    delegate ModeStatCtrl.isLfVipDoneFailed <-> outer port ModeStatAndRsp/isLfVipDoneFailed
    delegate ModeStatCtrl.isLfVipDoneOK <-> outer port ModeStatAndRsp/isLfVipDoneOK
    delegate ModeStatCtrl.isLgrstCloseLArrivedAtTargetPos <-> outer port ModeStatAndRsp/isLgrstCloseLArrivedAtTargetPos
    delegate ModeStatCtrl.isLgrstCloseLDoneFailed <-> outer port ModeStatAndRsp/isLgrstCloseLDoneFailed
    delegate ModeStatCtrl.isLgrstCloseLDoneOK <-> outer port ModeStatAndRsp/isLgrstCloseLDoneOK
    delegate ModeStatCtrl.isLgrstCloseRArrivedAtTargetPos <-> outer port ModeStatAndRsp/isLgrstCloseRArrivedAtTargetPos
    delegate ModeStatCtrl.isLgrstCloseRDoneFailed <-> outer port ModeStatAndRsp/isLgrstCloseRDoneFailed
    delegate ModeStatCtrl.isLgrstCloseRDoneOK <-> outer port ModeStatAndRsp/isLgrstCloseRDoneOK
    delegate ModeStatCtrl.isLgrstOpenLArrivedAtTargetPos <-> outer port ModeStatAndRsp/isLgrstOpenLArrivedAtTargetPos
    delegate ModeStatCtrl.isLgrstOpenLDoneFailed <-> outer port ModeStatAndRsp/isLgrstOpenLDoneFailed
    delegate ModeStatCtrl.isLgrstOpenLDoneOK <-> outer port ModeStatAndRsp/isLgrstOpenLDoneOK
    delegate ModeStatCtrl.isLgrstOpenRArrivedAtTargetPos <-> outer port ModeStatAndRsp/isLgrstOpenRArrivedAtTargetPos
    delegate ModeStatCtrl.isLgrstOpenRDoneFailed <-> outer port ModeStatAndRsp/isLgrstOpenRDoneFailed
    delegate ModeStatCtrl.isLgrstOpenRDoneOK <-> outer port ModeStatAndRsp/isLgrstOpenRDoneOK
    delegate ModeStatCtrl.isRfFamlyDoneFailed <-> outer port ModeStatAndRsp/isRfFamlyDoneFailed
    delegate ModeStatCtrl.isRfFamlyDoneOK <-> outer port ModeStatAndRsp/isRfFamlyDoneOK
    delegate ModeStatCtrl.isRtFamlyArrivedAtTargetPos <-> outer port ModeStatAndRsp/isRtFamlyArrivedAtTargetPos
    delegate ModeStatCtrl.isRtLugArrivedAtTargetPos <-> outer port ModeStatAndRsp/isRtLugArrivedAtTargetPos
    delegate ModeStatCtrl.isRtLugDoneFailed <-> outer port ModeStatAndRsp/isRtLugDoneFailed
    delegate ModeStatCtrl.isRtLugDoneOK <-> outer port ModeStatAndRsp/isRtLugDoneOK
    delegate ModeStatCtrl.isRtLyArrivedAtTargetPos <-> outer port ModeStatAndRsp/isRtLyArrivedAtTargetPos
    delegate ModeStatCtrl.isRtLyDoneFailed <-> outer port ModeStatAndRsp/isRtLyDoneFailed
    delegate ModeStatCtrl.isRtLyDoneOK <-> outer port ModeStatAndRsp/isRtLyDoneOK
    delegate ModeStatCtrl.isRtRecoveryArrivedAtTargetPos <-> outer port ModeStatAndRsp/isRtRecoveryArrivedAtTargetPos
    delegate ModeStatCtrl.isRtRecoveryDoneFailed <-> outer port ModeStatAndRsp/isRtRecoveryDoneFailed
    delegate ModeStatCtrl.isRtRecoveryDoneOK <-> outer port ModeStatAndRsp/isRtRecoveryDoneOK
    delegate ModeStatCtrl.isRtVipArrivedAtTargetPos <-> outer port ModeStatAndRsp/isRtVipArrivedAtTargetPos
    delegate ModeStatCtrl.isRtVipDoneFailed <-> outer port ModeStatAndRsp/isRtVipDoneFailed
    delegate ModeStatCtrl.isRtVipDoneOK <-> outer port ModeStatAndRsp/isRtVipDoneOK
    delegate ModeRsp.KeSMSbMdChime2Enable <-> outer port ModeStatAndRsp/KeSMSbMdChime2Enable
    delegate ModeRsp.KeSMSbSRSPosNumConfig <-> outer port ModeStatAndRsp/KeSMSbSRSPosNumConfig
    delegate ModeRsp.KeSMSuChmReqDurnTm <-> outer port ModeStatAndRsp/KeSMSuChmReqDurnTm
    delegate ModeRsp.KeSMSuChmReqIntlTm <-> outer port ModeStatAndRsp/KeSMSuChmReqIntlTm
    delegate ModeRsp.KeSMSuRspStatHldTm <-> outer port ModeStatAndRsp/KeSMSuRspStatHldTm
    delegate ModeStatCtrl.LfFamlyReq <-> outer port ModeStatAndRsp/LfFamlyReq
    delegate ModeStatCtrl.LfFamlySrcReqTp <-> outer port ModeStatAndRsp/LfFamlySrcReqTp
    delegate ModeStatCtrl.LfLyMdReq <-> outer port ModeStatAndRsp/LfLyMdReq
    delegate ModeStatCtrl.LfLySrcReqTp <-> outer port ModeStatAndRsp/LfLySrcReqTp
    delegate ModeStatCtrl.LgrstCloseLtMdReq <-> outer port ModeStatAndRsp/LgrstCloseLtMdReq
    delegate ModeStatCtrl.LgrstCloseLtSrcReqTp <-> outer port ModeStatAndRsp/LgrstCloseLtSrcReqTp
    delegate ModeStatCtrl.LgrstCloseRtMdReq <-> outer port ModeStatAndRsp/LgrstCloseRtMdReq
    delegate ModeStatCtrl.LgrstCloseRtSrcReqTp <-> outer port ModeStatAndRsp/LgrstCloseRtSrcReqTp
    delegate ModeStatCtrl.LgrstOpenLtMdReq <-> outer port ModeStatAndRsp/LgrstOpenLtMdReq
    delegate ModeStatCtrl.LgrstOpenLtSrcReqTp <-> outer port ModeStatAndRsp/LgrstOpenLtSrcReqTp
    delegate ModeStatCtrl.LgrstOpenRtMdReq <-> outer port ModeStatAndRsp/LgrstOpenRtMdReq
    delegate ModeStatCtrl.LgrstOpenRtSrcReqTp <-> outer port ModeStatAndRsp/LgrstOpenRtSrcReqTp
    delegate ModeStatCtrl.LtLugMdReq <-> outer port ModeStatAndRsp/LtLugMdReq
    delegate ModeStatCtrl.LtLugSrcReqTp <-> outer port ModeStatAndRsp/LtLugSrcReqTp
    delegate ModeStatCtrl.LtRcvyMdReq <-> outer port ModeStatAndRsp/LtRcvyMdReq
    delegate ModeStatCtrl.LtRcvySrcReqTp <-> outer port ModeStatAndRsp/LtRcvySrcReqTp
    delegate ModeStatCtrl.LtVipMdReq <-> outer port ModeStatAndRsp/LtVipMdReq
    delegate ModeStatCtrl.LtVipSrcReqTp <-> outer port ModeStatAndRsp/LtVipSrcReqTp
    delegate ModeStatCtrl.LugMdLtAvl <-> outer port ModeStatAndRsp/LugMdLtAvl
    delegate ModeStatCtrl.LugMdRtAvl <-> outer port ModeStatAndRsp/LugMdRtAvl
    delegate ModeRsp.ModeSrcTpLt <-> outer port ModeStatAndRsp/ModeSrcTpLt
    delegate ModeStatCtrl.modestate32 <-> outer port ModeStatAndRsp/modestate32
    delegate ModeRsp.oModeState <-> outer port ModeStatAndRsp/oModeState
    delegate ModeRsp.PosArray <-> outer port ModeStatAndRsp/PosArray
    delegate ModeRsp.PwrMdChked <-> outer port ModeStatAndRsp/PwrMdChked
    delegate ModeStatCtrl.R3LMdSeatOccupied <-> outer port ModeStatAndRsp/R3LMdSeatOccupied
    delegate ModeStatCtrl.R3RMdSeatOccupied <-> outer port ModeStatAndRsp/R3RMdSeatOccupied
    delegate ModeStatCtrl.RtFamlyMdReq <-> outer port ModeStatAndRsp/RtFamlyMdReq
    delegate ModeStatCtrl.RtFamlySrcReqTp <-> outer port ModeStatAndRsp/RtFamlySrcReqTp
    delegate ModeStatCtrl.RtLugMdReq <-> outer port ModeStatAndRsp/RtLugMdReq
    delegate ModeStatCtrl.RtLugSrcReqTp <-> outer port ModeStatAndRsp/RtLugSrcReqTp
    delegate ModeStatCtrl.RtLyMdReq <-> outer port ModeStatAndRsp/RtLyMdReq
    delegate ModeStatCtrl.RtLySrcReqTp <-> outer port ModeStatAndRsp/RtLySrcReqTp
    delegate ModeStatCtrl.RtRcvyMdReq <-> outer port ModeStatAndRsp/RtRcvyMdReq
    delegate ModeStatCtrl.RtRcvySrcReqTp <-> outer port ModeStatAndRsp/RtRcvySrcReqTp
    delegate ModeStatCtrl.RtVipMdReq <-> outer port ModeStatAndRsp/RtVipMdReq
    delegate ModeStatCtrl.RtVipSrcReqTp <-> outer port ModeStatAndRsp/RtVipSrcReqTp
    delegate ModeStatCtrl.SoftIntAcsEnty <-> outer port ModeStatAndRsp/SoftIntAcsEnty
    delegate ModeStatCtrl.SoftIntAcsExt <-> outer port ModeStatAndRsp/SoftIntAcsExt
    delegate ModeStatCtrl.SoftIntAllLug <-> outer port ModeStatAndRsp/SoftIntAllLug
    delegate ModeStatCtrl.SoftIntAllVip <-> outer port ModeStatAndRsp/SoftIntAllVip
    delegate ModeStatCtrl.SoftIntIntimacyRt <-> outer port ModeStatAndRsp/SoftIntIntimacyRt
    delegate ModeStatCtrl.SoftIntINTM <-> outer port ModeStatAndRsp/SoftIntINTM
    delegate ModeStatCtrl.SoftIntLfFamly <-> outer port ModeStatAndRsp/SoftIntLfFamly
    delegate ModeStatCtrl.SoftIntLfLug <-> outer port ModeStatAndRsp/SoftIntLfLug
    delegate ModeStatCtrl.SoftIntLfLy <-> outer port ModeStatAndRsp/SoftIntLfLy
    delegate ModeStatCtrl.SoftIntLfRcvy <-> outer port ModeStatAndRsp/SoftIntLfRcvy
    delegate ModeStatCtrl.SoftIntLfVip <-> outer port ModeStatAndRsp/SoftIntLfVip
    delegate ModeStatCtrl.SoftIntLgrstCloseLt <-> outer port ModeStatAndRsp/SoftIntLgrstCloseLt
    delegate ModeStatCtrl.SoftIntLgrstCloseRt <-> outer port ModeStatAndRsp/SoftIntLgrstCloseRt
    delegate ModeStatCtrl.SoftIntLgrstOpenLt <-> outer port ModeStatAndRsp/SoftIntLgrstOpenLt
    delegate ModeStatCtrl.SoftIntLgrstOpenRt <-> outer port ModeStatAndRsp/SoftIntLgrstOpenRt
    delegate ModeStatCtrl.SoftIntRtFamly <-> outer port ModeStatAndRsp/SoftIntRtFamly
    delegate ModeStatCtrl.SoftIntRtLug <-> outer port ModeStatAndRsp/SoftIntRtLug
    delegate ModeStatCtrl.SoftIntRtLy <-> outer port ModeStatAndRsp/SoftIntRtLy
    delegate ModeStatCtrl.SoftIntRtRcvy <-> outer port ModeStatAndRsp/SoftIntRtRcvy
    delegate ModeStatCtrl.SoftIntRtVip <-> outer port ModeStatAndRsp/SoftIntRtVip
    delegate ModeRsp.SRSMode <-> outer port ModeStatAndRsp/SRSMode
    delegate ModeStatCtrl.SwIntAcsEnty <-> outer port ModeStatAndRsp/SwIntAcsEnty
    delegate ModeStatCtrl.SwIntAcsExt <-> outer port ModeStatAndRsp/SwIntAcsExt
    delegate ModeStatCtrl.SwIntAllLug <-> outer port ModeStatAndRsp/SwIntAllLug
    delegate ModeStatCtrl.SwIntAllVip <-> outer port ModeStatAndRsp/SwIntAllVip
    delegate ModeStatCtrl.SwIntIntimacyRt <-> outer port ModeStatAndRsp/SwIntIntimacyRt
    delegate ModeStatCtrl.SwIntINTM <-> outer port ModeStatAndRsp/SwIntINTM
    delegate ModeStatCtrl.SwIntLfFamly <-> outer port ModeStatAndRsp/SwIntLfFamly
    delegate ModeStatCtrl.SwIntLfLug <-> outer port ModeStatAndRsp/SwIntLfLug
    delegate ModeStatCtrl.SwIntLfLy <-> outer port ModeStatAndRsp/SwIntLfLy
    delegate ModeStatCtrl.SwIntLfRcvy <-> outer port ModeStatAndRsp/SwIntLfRcvy
    delegate ModeStatCtrl.SwIntLfVip <-> outer port ModeStatAndRsp/SwIntLfVip
    delegate ModeStatCtrl.SwIntLgrstCloseLt <-> outer port ModeStatAndRsp/SwIntLgrstCloseLt
    delegate ModeStatCtrl.SwIntLgrstCloseRt <-> outer port ModeStatAndRsp/SwIntLgrstCloseRt
    delegate ModeStatCtrl.SwIntLgrstOpenLt <-> outer port ModeStatAndRsp/SwIntLgrstOpenLt
    delegate ModeStatCtrl.SwIntLgrstOpenRt <-> outer port ModeStatAndRsp/SwIntLgrstOpenRt
    delegate ModeStatCtrl.SwIntRtFamly <-> outer port ModeStatAndRsp/SwIntRtFamly
    delegate ModeStatCtrl.SwIntRtLug <-> outer port ModeStatAndRsp/SwIntRtLug
    delegate ModeStatCtrl.SwIntRtLy <-> outer port ModeStatAndRsp/SwIntRtLy
    delegate ModeStatCtrl.SwIntRtRcvy <-> outer port ModeStatAndRsp/SwIntRtRcvy
    delegate ModeStatCtrl.SwIntRtVip <-> outer port ModeStatAndRsp/SwIntRtVip
    delegate ModeStatCtrl.VipMdLtAvl <-> outer port ModeStatAndRsp/VipMdLtAvl
    delegate ModeStatCtrl.VipMdRtAvl <-> outer port ModeStatAndRsp/VipMdRtAvl
package /PATAC/MSM/ModeAdjust/CalPortInterface
  parameter interface KeSMSuRspStatHldTm
    parameter data prototype Val: sw-calibration-access=READ-WRITE, type=UInt8
  parameter interface MdChime2Enable
    parameter data prototype Val: sw-calibration-access=READ-WRITE, type=Boolean
  parameter interface SRSPosNumConfig
    parameter data prototype Val: sw-calibration-access=READ-WRITE, type=UInt8
package /PATAC/MSM/ModeAdjust/DataType
  7 x impl type, all with sw-calibration-access=READ-ONLY, type-emitter=RTE:
    EventSts1: category=VALUE, base-type=UInt8, compu {0=EventSts_NoAct, 1=EventSts_Act, 2=EventSts_CancleChime}
    MdRspLocal2: category=VALUE, base-type=UInt8, compu {0=MdRsp_None, 1=MdRsp_RecallSuccessfully, 2=MdRsp_RecallUnsuccessfully_LocalInterrupt, 3=MdRsp_RecallUnsuccessfully_NonEnghSpace, 4=MdRsp_RecallOngoing, 5=MdRsp_TargetPositionAlready, 6=MdRsp_LowPower, 7=MdRsp_CrashStat, 8=MdRsp_ThdRwOccupt, 9=MdRsp_PosNotLrn, 10=MdRsp_NotParkStat, 11=MdRsp_SpdNotCorrt}
    MdTp1: category=VALUE, base-type=UInt8, compu {0=MdTp_None, 1=MdTp_EzeEntry, 2=MdTp_EzeExt, 3=MdTp_Vip, 4=MdTp_Lug, 5=MdTp_Recovery, 6=MdTp_Intimacy, 7=MdTp_Family, 8=MdTp_Lying, 9=MdTp_LgrstOpenLt, 10=MdTp_LgrstCloseLt, 11=MdTp_LgrstOpenRt, 12=MdTp_LgrstCloseRt}
    ModeList: category=ARRAY
      element Val: array-size=11, array-size-semantics=FIXED-SIZE, implementation-data-type=UInt8
    PowerMode1: category=VALUE, base-type=UInt8, compu {0=PowerMode_Off, 1=PowerMode_Acc, 2=PowerMode_Run, 3=PowerMode_Crank, 4=PowerMode_Invalid}
    SrcReqTp1: category=VALUE, base-type=UInt8, compu {0=SrcReqTp_None, 1=SrcReqTp_Local, 2=SrcReqTp_HMI2L, 3=SrcReqTp_HMI2R, 4=SrcReqTp_HMI, 5=SrcReqTp_Remote, 6=SrcReqTp_SRS}
    SRSCurMode1:
      category=VALUE
      base-type=UInt8
      compu {0=SRSMode_None, 1=SRSMode_EZEEntry, 2=SRSMode_EzeExt, 3=SRSMode_LfVip, 4=SRSMode_RtVip, 5=SRSMode_AllVip, 6=SRSMode_LfLug, 7=SRSMode_RtLug, 8=SRSMode_AllLug, 9=SRSMode_IntimacyL, 10=SRSMode_FamilyR, 11=SRSMode_FamilyL, 12=SRSMode_RcvyL, 13=SRSMode_RcvyR, 14=SRSMode_LyingL, 15=SRSMode_LyingR, 16=SRSMode_LgrstOpenLt, 17=SRSMode_LgrstCloseLt, 18=SRSMode_LgrstOpenRt, 19=SRSMode_LgrstCloseRt, 20=SRSMode_IntimacyR}
package /PATAC/MSM/ModeAdjust/PortInterface
  37 x sender receiver interface:
    AnyModeAjust: invalidation-policy{data-element=AnyModeAjust/Val, handle-invalid=DONT-INVALIDATE}
      data Val: type=Boolean
    ChmEvenState: invalidation-policy{data-element=ChmEvenState/Val, handle-invalid=DONT-INVALIDATE}
      data Val: type=EventSts1
    CommCond: invalidation-policy{data-element=CommCond/Val, handle-invalid=DONT-INVALIDATE}
      data Val: type=Boolean
    CommExitCond: invalidation-policy{data-element=CommExitCond/Val, handle-invalid=DONT-INVALIDATE}
      data Val: type=Boolean
    CommExitCondwithSpeed: invalidation-policy{data-element=CommExitCondwithSpeed/Val, handle-invalid=DONT-INVALIDATE}
      data Val: type=Boolean
    DoneFailed: invalidation-policy{data-element=DoneFailed/Val, handle-invalid=DONT-INVALIDATE}
      data Val: type=Boolean
    DoneOK: invalidation-policy{data-element=DoneOK/Val, handle-invalid=DONT-INVALIDATE}
      data Val: type=Boolean
    HMI2LMdRsp: invalidation-policy{data-element=HMI2LMdRsp/Val, handle-invalid=DONT-INVALIDATE}
      data Val: type=UInt8
    HMI2RMdRsp: invalidation-policy{data-element=HMI2RMdRsp/Val, handle-invalid=DONT-INVALIDATE}
      data Val: type=UInt8
    IfVeSMSeStNumConfig: invalidation-policy{data-element=IfVeSMSeStNumConfig/Val, handle-invalid=DONT-INVALIDATE}
      data Val: type=IfVeSMSeStNumConfig
    IfVeSMSuChmMgrStat: invalidation-policy{data-element=IfVeSMSuChmMgrStat/Val, handle-invalid=DONT-INVALIDATE}
      data Val: type=UInt16
    IntEnable: invalidation-policy{data-element=IntEnable/Val, handle-invalid=DONT-INVALIDATE}
      data Val: type=IntEnable
    IsStBsy32Bit: invalidation-policy{data-element=IsStBsy32Bit/Val, handle-invalid=DONT-INVALIDATE}
      data Val: type=UInt32
    IsTargetPos: invalidation-policy{data-element=IsTargetPos/Val, handle-invalid=DONT-INVALIDATE}
      data Val: type=Boolean
    IsTargetPos32Bit: invalidation-policy{data-element=IsTargetPos32Bit/Val, handle-invalid=DONT-INVALIDATE}
      data Val: type=UInt32
    MdRclRspStat: invalidation-policy{data-element=MdRclRspStat/Val, handle-invalid=DONT-INVALIDATE}
      data Val: type=UInt8
    MdReq: invalidation-policy{data-element=MdReq/Val, handle-invalid=DONT-INVALIDATE}
      data Val: type=Boolean
    MdSeatOccupied: invalidation-policy{data-element=MdSeatOccupied/Val, handle-invalid=DONT-INVALIDATE}
      data Val: type=Boolean
    MdXX_Quit32bit: invalidation-policy{data-element=MdXX_Quit32bit/Val, handle-invalid=DONT-INVALIDATE}
      data Val: type=UInt32
    MdXX_Rsp
      32 x data, all with type=MdRspLocal2:
        Md1_Rsp
        Md{10..19}_Rsp
        Md2_Rsp
        Md{20..29}_Rsp
        Md3_Rsp
        Md{30..32}_Rsp
        Md{4..9}_Rsp
      invalidation-policys:
        data-element=Md1_Rsp, handle-invalid=DONT-INVALIDATE
        data-element=Md2_Rsp, handle-invalid=DONT-INVALIDATE
        data-element=Md5_Rsp, handle-invalid=DONT-INVALIDATE
        data-element=Md3_Rsp, handle-invalid=DONT-INVALIDATE
        data-element=Md7_Rsp, handle-invalid=DONT-INVALIDATE
        data-element=Md4_Rsp, handle-invalid=DONT-INVALIDATE
        data-element=Md6_Rsp, handle-invalid=DONT-INVALIDATE
        data-element=Md9_Rsp, handle-invalid=DONT-INVALIDATE
        data-element=Md8_Rsp, handle-invalid=DONT-INVALIDATE
        data-element=Md11_Rsp, handle-invalid=DONT-INVALIDATE
        data-element=Md10_Rsp, handle-invalid=DONT-INVALIDATE
        data-element=Md13_Rsp, handle-invalid=DONT-INVALIDATE
        data-element=Md12_Rsp, handle-invalid=DONT-INVALIDATE
        data-element=Md21_Rsp, handle-invalid=DONT-INVALIDATE
        data-element=Md14_Rsp, handle-invalid=DONT-INVALIDATE
        data-element=Md20_Rsp, handle-invalid=DONT-INVALIDATE
        data-element=Md15_Rsp, handle-invalid=DONT-INVALIDATE
        data-element=Md19_Rsp, handle-invalid=DONT-INVALIDATE
        data-element=Md16_Rsp, handle-invalid=DONT-INVALIDATE
        data-element=Md23_Rsp, handle-invalid=DONT-INVALIDATE
        data-element=Md17_Rsp, handle-invalid=DONT-INVALIDATE
        data-element=Md22_Rsp, handle-invalid=DONT-INVALIDATE
        data-element=Md18_Rsp, handle-invalid=DONT-INVALIDATE
        data-element=Md28_Rsp, handle-invalid=DONT-INVALIDATE
        data-element=Md24_Rsp, handle-invalid=DONT-INVALIDATE
        data-element=Md30_Rsp, handle-invalid=DONT-INVALIDATE
        data-element=Md25_Rsp, handle-invalid=DONT-INVALIDATE
        data-element=Md29_Rsp, handle-invalid=DONT-INVALIDATE
        data-element=Md26_Rsp, handle-invalid=DONT-INVALIDATE
        data-element=Md31_Rsp, handle-invalid=DONT-INVALIDATE
        data-element=Md32_Rsp, handle-invalid=DONT-INVALIDATE
        data-element=Md27_Rsp, handle-invalid=DONT-INVALIDATE
    MdXX_RspOutComm
      32 x data, all with type=UInt8:
        Md1_RspOutComm
        Md{10..19}_RspOutComm
        Md2_RspOutComm
        Md{20..29}_RspOutComm
        Md3_RspOutComm
        Md{30..32}_RspOutComm
        Md{4..9}_RspOutComm
      invalidation-policys:
        data-element=Md1_RspOutComm, handle-invalid=DONT-INVALIDATE
        data-element=Md11_RspOutComm, handle-invalid=DONT-INVALIDATE
        data-element=Md12_RspOutComm, handle-invalid=DONT-INVALIDATE
        data-element=Md14_RspOutComm, handle-invalid=DONT-INVALIDATE
        data-element=Md13_RspOutComm, handle-invalid=DONT-INVALIDATE
        data-element=Md19_RspOutComm, handle-invalid=DONT-INVALIDATE
        data-element=Md15_RspOutComm, handle-invalid=DONT-INVALIDATE
        data-element=Md18_RspOutComm, handle-invalid=DONT-INVALIDATE
        data-element=Md16_RspOutComm, handle-invalid=DONT-INVALIDATE
        data-element=Md17_RspOutComm, handle-invalid=DONT-INVALIDATE
        data-element=Md2_RspOutComm, handle-invalid=DONT-INVALIDATE
        data-element=Md21_RspOutComm, handle-invalid=DONT-INVALIDATE
        data-element=Md22_RspOutComm, handle-invalid=DONT-INVALIDATE
        data-element=Md24_RspOutComm, handle-invalid=DONT-INVALIDATE
        data-element=Md23_RspOutComm, handle-invalid=DONT-INVALIDATE
        data-element=Md{25..27}_RspOutComm, handle-invalid=DONT-INVALIDATE
        data-element=Md29_RspOutComm, handle-invalid=DONT-INVALIDATE
        data-element=Md28_RspOutComm, handle-invalid=DONT-INVALIDATE
        data-element=Md3_RspOutComm, handle-invalid=DONT-INVALIDATE
        data-element=Md31_RspOutComm, handle-invalid=DONT-INVALIDATE
        data-element=Md32_RspOutComm, handle-invalid=DONT-INVALIDATE
        data-element=Md{4..6}_RspOutComm, handle-invalid=DONT-INVALIDATE
        data-element=Md9_RspOutComm, handle-invalid=DONT-INVALIDATE
        data-element=Md7_RspOutComm, handle-invalid=DONT-INVALIDATE
        data-element=Md8_RspOutComm, handle-invalid=DONT-INVALIDATE
        data-element=Md10_RspOutComm, handle-invalid=DONT-INVALIDATE
        data-element=Md20_RspOutComm, handle-invalid=DONT-INVALIDATE
        data-element=Md30_RspOutComm, handle-invalid=DONT-INVALIDATE
    MdXX_SrcReqTp
      32 x data, all with type=SrcReqTp1:
        Md1_SrcTp
        Md{10..19}_SrcTp
        Md2_SrcTp
        Md{20..29}_SrcTp
        Md3_SrcTp
        Md{30..32}_SrcTp
        Md{4..9}_SrcTp
      invalidation-policys:
        data-element=Md1_SrcTp, handle-invalid=DONT-INVALIDATE
        data-element=Md2_SrcTp, handle-invalid=DONT-INVALIDATE
        data-element=Md4_SrcTp, handle-invalid=DONT-INVALIDATE
        data-element=Md3_SrcTp, handle-invalid=DONT-INVALIDATE
        data-element=Md6_SrcTp, handle-invalid=DONT-INVALIDATE
        data-element=Md5_SrcTp, handle-invalid=DONT-INVALIDATE
        data-element=Md10_SrcTp, handle-invalid=DONT-INVALIDATE
        data-element=Md7_SrcTp, handle-invalid=DONT-INVALIDATE
        data-element=Md12_SrcTp, handle-invalid=DONT-INVALIDATE
        data-element=Md8_SrcTp, handle-invalid=DONT-INVALIDATE
        data-element=Md11_SrcTp, handle-invalid=DONT-INVALIDATE
        data-element=Md9_SrcTp, handle-invalid=DONT-INVALIDATE
        data-element=Md14_SrcTp, handle-invalid=DONT-INVALIDATE
        data-element=Md13_SrcTp, handle-invalid=DONT-INVALIDATE
        data-element=Md17_SrcTp, handle-invalid=DONT-INVALIDATE
        data-element=Md16_SrcTp, handle-invalid=DONT-INVALIDATE
        data-element=Md15_SrcTp, handle-invalid=DONT-INVALIDATE
        data-element=Md19_SrcTp, handle-invalid=DONT-INVALIDATE
        data-element=Md18_SrcTp, handle-invalid=DONT-INVALIDATE
        data-element=Md{20..22}_SrcTp, handle-invalid=DONT-INVALIDATE
        data-element=Md24_SrcTp, handle-invalid=DONT-INVALIDATE
        data-element=Md23_SrcTp, handle-invalid=DONT-INVALIDATE
        data-element=Md26_SrcTp, handle-invalid=DONT-INVALIDATE
        data-element=Md25_SrcTp, handle-invalid=DONT-INVALIDATE
        data-element=Md28_SrcTp, handle-invalid=DONT-INVALIDATE
        data-element=Md27_SrcTp, handle-invalid=DONT-INVALIDATE
        data-element=Md30_SrcTp, handle-invalid=DONT-INVALIDATE
        data-element=Md29_SrcTp, handle-invalid=DONT-INVALIDATE
        data-element=Md32_SrcTp, handle-invalid=DONT-INVALIDATE
        data-element=Md31_SrcTp, handle-invalid=DONT-INVALIDATE
    MdXX_Stat
      32 x data, all with type=UInt8:
        Md1_Stat
        Md{10..19}_Stat
        Md2_Stat
        Md{20..29}_Stat
        Md3_Stat
        Md{30..32}_Stat
        Md{4..9}_Stat
      invalidation-policys:
        data-element=Md{1..3}_Stat, handle-invalid=DONT-INVALIDATE
        data-element=Md5_Stat, handle-invalid=DONT-INVALIDATE
        data-element=Md4_Stat, handle-invalid=DONT-INVALIDATE
        data-element=Md12_Stat, handle-invalid=DONT-INVALIDATE
        data-element=Md6_Stat, handle-invalid=DONT-INVALIDATE
        data-element=Md15_Stat, handle-invalid=DONT-INVALIDATE
        data-element=Md7_Stat, handle-invalid=DONT-INVALIDATE
        data-element=Md13_Stat, handle-invalid=DONT-INVALIDATE
        data-element=Md8_Stat, handle-invalid=DONT-INVALIDATE
        data-element=Md18_Stat, handle-invalid=DONT-INVALIDATE
        data-element=Md9_Stat, handle-invalid=DONT-INVALIDATE
        data-element=Md14_Stat, handle-invalid=DONT-INVALIDATE
        data-element=Md10_Stat, handle-invalid=DONT-INVALIDATE
        data-element=Md16_Stat, handle-invalid=DONT-INVALIDATE
        data-element=Md11_Stat, handle-invalid=DONT-INVALIDATE
        data-element=Md20_Stat, handle-invalid=DONT-INVALIDATE
        data-element=Md17_Stat, handle-invalid=DONT-INVALIDATE
        data-element=Md19_Stat, handle-invalid=DONT-INVALIDATE
        data-element=Md22_Stat, handle-invalid=DONT-INVALIDATE
        data-element=Md21_Stat, handle-invalid=DONT-INVALIDATE
        data-element=Md24_Stat, handle-invalid=DONT-INVALIDATE
        data-element=Md23_Stat, handle-invalid=DONT-INVALIDATE
        data-element=Md26_Stat, handle-invalid=DONT-INVALIDATE
        data-element=Md25_Stat, handle-invalid=DONT-INVALIDATE
        data-element=Md28_Stat, handle-invalid=DONT-INVALIDATE
        data-element=Md27_Stat, handle-invalid=DONT-INVALIDATE
        data-element=Md30_Stat, handle-invalid=DONT-INVALIDATE
        data-element=Md29_Stat, handle-invalid=DONT-INVALIDATE
        data-element=Md32_Stat, handle-invalid=DONT-INVALIDATE
        data-element=Md31_Stat, handle-invalid=DONT-INVALIDATE
    ModeAdjustAvailable: invalidation-policy{data-element=ModeAdjustAvailable/Val, handle-invalid=DONT-INVALIDATE}
      data Val: type=Boolean
    ModeSrcTp: invalidation-policy{data-element=ModeSrcTp/Val, handle-invalid=DONT-INVALIDATE}
      data Val: type=SrcReqTp1
    ModeState: invalidation-policy{data-element=ModeState/Val, handle-invalid=DONT-INVALIDATE}
      data Val: type=MdTp1
    modestate32: invalidation-policy{data-element=modestate32/Val, handle-invalid=DONT-INVALIDATE}
      data Val: type=UInt32
    ModeStateOn: invalidation-policy{data-element=ModeStateOn/Val, handle-invalid=DONT-INVALIDATE}
      data Val: type=Boolean
    PosArray: invalidation-policy{data-element=PosArray/Val, handle-invalid=DONT-INVALIDATE}
      data Val: type=ModeList
    PowerMode: invalidation-policy{data-element=PowerMode/Val, handle-invalid=DONT-INVALIDATE}
      data Val: type=PowerMode1
    SRSCrtMdIndTyp_67_2: invalidation-policy{data-element=SRSCrtMdIndTyp_67_2/Val, handle-invalid=DONT-INVALIDATE}
      data Val: type=UInt8
    SRSCrtMdStat_67_2: invalidation-policy{data-element=SRSCrtMdStat_67_2/Val, handle-invalid=DONT-INVALIDATE}
      data Val: type=UInt8
    SRSCurMode: invalidation-policy{data-element=SRSCurMode/Val, handle-invalid=DONT-INVALIDATE}
      data Val: type=SRSCurMode1
    StNumFlg
      4 x data, all with type=Boolean:
        Is4s
        Is6s
        Is6s7s
        Is7s
      invalidation-policys:
        data-element=Is7s, handle-invalid=DONT-INVALIDATE
        data-element=Is6s, handle-invalid=DONT-INVALIDATE
        data-element=Is4s, handle-invalid=DONT-INVALIDATE
        data-element=Is6s7s, handle-invalid=DONT-INVALIDATE
    StPassCmprtMdCrtMdStat: invalidation-policy{data-element=StPassCmprtMdCrtMdStat/Val, handle-invalid=DONT-INVALIDATE}
      data Val: type=UInt8
    StPassCmprtMdHMIDisCmdSrv: invalidation-policy{data-element=StPassCmprtMdHMIDisCmdSrv/Val, handle-invalid=DONT-INVALIDATE}
      data Val: type=UInt8
    StSrvMdRsp: invalidation-policy{data-element=StSrvMdRsp/Val, handle-invalid=DONT-INVALIDATE}
      data Val: type=UInt8
package /PATAC/MSM/PortInterfaces
  parameter interface KeSMSuChmReqDurnTm
    parameter data prototype Val: sw-calibration-access=READ-WRITE, type=UInt8
  parameter interface KeSMSuChmReqIntlTm
    parameter data prototype Val: sw-calibration-access=READ-WRITE, type=UInt8
